// *************************************************************************** *
// *                                                                           *
// *                      Mentor Graphics Corporation                          *
// *                          All rights reserved                              *
// *                                                                           *
// *************************************************************************** *
// *                                                                           *
// * Description:         CANDB File                                           *
// * Generated at:        2022-07-01 13:40                                     *
// * System:              ZSDB122200                                           *
// * Variant:             DC1E_EU                                              *
// * Network:             BodyExposedCAN                                       *
// *                                                                           *
// *************************************************************************** *
// *                                                                           *
// *             THIS CONFIGURATION MIGHT CONTAIN SOME ERRORS                  *
// *              IF THE INPUT MODEL WAS NOT PROPERLY FORMED!                  *
// *                    Do Not Use this File directly!                         *
// *                                                                           *
// *************************************************************************** *
VERSION "BodyExposedCAN"

NS_ :

BS_ :

BU_ :  CEM ETC HCML HCMR RCML RCMM RCMR

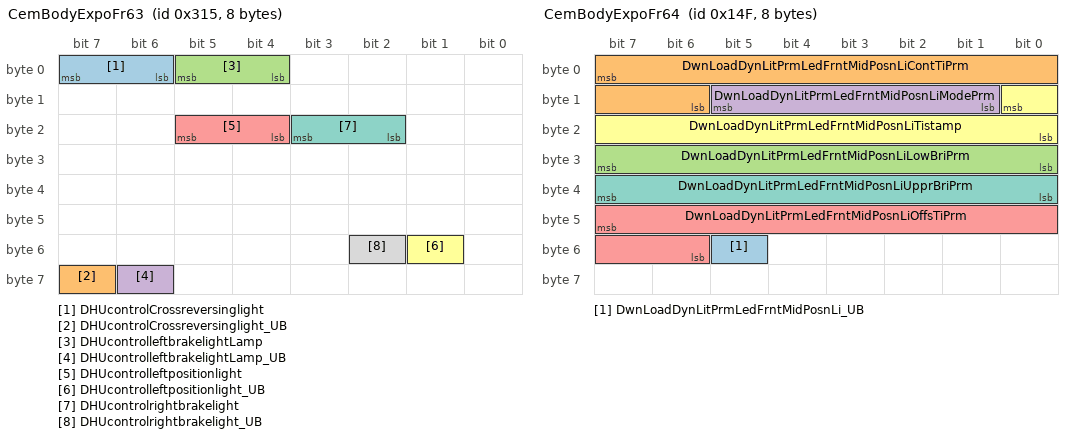
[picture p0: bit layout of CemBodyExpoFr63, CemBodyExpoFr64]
BO_ 789 CemBodyExpoFr63 : 8 CEM
 SG_ DHUcontrolCrossreversinglight : 7|2@0+ (1,0) [0|3] "" RCMM
 SG_ DHUcontrolCrossreversinglight_UB : 63|1@0+ (1,0) [0|1] "" RCMM
 SG_ DHUcontrolleftbrakelightLamp : 5|2@0+ (1,0) [0|3] "" RCML
 SG_ DHUcontrolleftbrakelightLamp_UB : 62|1@0+ (1,0) [0|1] "" RCML
 SG_ DHUcontrolleftpositionlight : 21|2@0+ (1,0) [0|3] "" RCML
 SG_ DHUcontrolleftpositionlight_UB : 49|1@0+ (1,0) [0|1] "" RCML
 SG_ DHUcontrolrightbrakelight : 19|2@0+ (1,0) [0|3] "" RCMR
 SG_ DHUcontrolrightbrakelight_UB : 50|1@0+ (1,0) [0|1] "" RCMR

BO_ 335 CemBodyExpoFr64 : 8 CEM
 SG_ DwnLoadDynLitPrmLedFrntMidPosnLi_UB : 53|1@0+ (1,0) [0|1] "" Vector_XXX
 SG_ DwnLoadDynLitPrmLedFrntMidPosnLiContTiPrm : 7|10@0+ (1.0,0.0) [0.0|1000.0] "Milliseconds" Vector_XXX
 SG_ DwnLoadDynLitPrmLedFrntMidPosnLiLowBriPrm : 31|8@0+ (1.0,0.0) [0.0|100.0] "%" Vector_XXX
 SG_ DwnLoadDynLitPrmLedFrntMidPosnLiModePrm : 13|5@0+ (1,0) [0|31] "" Vector_XXX
 SG_ DwnLoadDynLitPrmLedFrntMidPosnLiOffsTiPrm : 47|10@0+ (1.0,0.0) [0.0|1000.0] "Milliseconds" Vector_XXX
 SG_ DwnLoadDynLitPrmLedFrntMidPosnLiTistamp : 8|9@0+ (1.0,0.0) [0.0|511.0] "Unitless" Vector_XXX
 SG_ DwnLoadDynLitPrmLedFrntMidPosnLiUpprBriPrm : 39|8@0+ (1.0,0.0) [0.0|100.0] "%" Vector_XXX

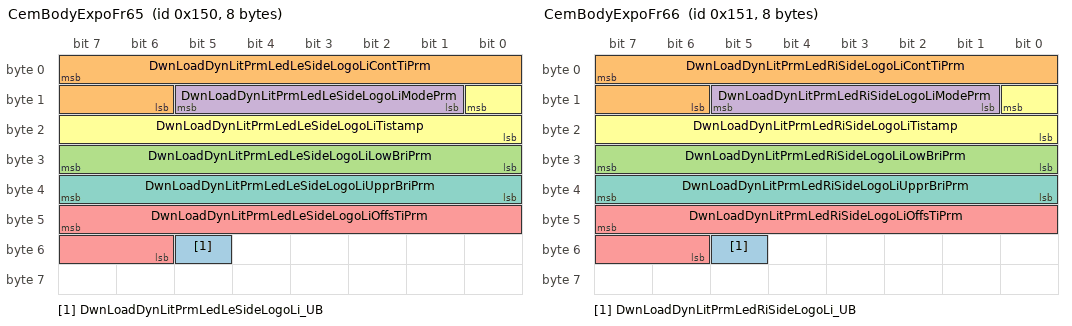
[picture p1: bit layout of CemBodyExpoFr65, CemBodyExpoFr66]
BO_ 336 CemBodyExpoFr65 : 8 CEM
 SG_ DwnLoadDynLitPrmLedLeSideLogoLi_UB : 53|1@0+ (1,0) [0|1] "" HCML
 SG_ DwnLoadDynLitPrmLedLeSideLogoLiContTiPrm : 7|10@0+ (1.0,0.0) [0.0|1000.0] "Milliseconds" HCML
 SG_ DwnLoadDynLitPrmLedLeSideLogoLiLowBriPrm : 31|8@0+ (1.0,0.0) [0.0|100.0] "%" HCML
 SG_ DwnLoadDynLitPrmLedLeSideLogoLiModePrm : 13|5@0+ (1,0) [0|31] "" HCML
 SG_ DwnLoadDynLitPrmLedLeSideLogoLiOffsTiPrm : 47|10@0+ (1.0,0.0) [0.0|1000.0] "Milliseconds" HCML
 SG_ DwnLoadDynLitPrmLedLeSideLogoLiTistamp : 8|9@0+ (1.0,0.0) [0.0|511.0] "Unitless" HCML
 SG_ DwnLoadDynLitPrmLedLeSideLogoLiUpprBriPrm : 39|8@0+ (1.0,0.0) [0.0|100.0] "%" HCML

BO_ 337 CemBodyExpoFr66 : 8 CEM
 SG_ DwnLoadDynLitPrmLedRiSideLogoLi_UB : 53|1@0+ (1,0) [0|1] "" HCMR
 SG_ DwnLoadDynLitPrmLedRiSideLogoLiContTiPrm : 7|10@0+ (1.0,0.0) [0.0|1000.0] "Milliseconds" HCMR
 SG_ DwnLoadDynLitPrmLedRiSideLogoLiLowBriPrm : 31|8@0+ (1.0,0.0) [0.0|100.0] "%" HCMR
 SG_ DwnLoadDynLitPrmLedRiSideLogoLiModePrm : 13|5@0+ (1,0) [0|31] "" HCMR
 SG_ DwnLoadDynLitPrmLedRiSideLogoLiOffsTiPrm : 47|10@0+ (1.0,0.0) [0.0|1000.0] "Milliseconds" HCMR
 SG_ DwnLoadDynLitPrmLedRiSideLogoLiTistamp : 8|9@0+ (1.0,0.0) [0.0|511.0] "Unitless" HCMR
 SG_ DwnLoadDynLitPrmLedRiSideLogoLiUpprBriPrm : 39|8@0+ (1.0,0.0) [0.0|100.0] "%" HCMR

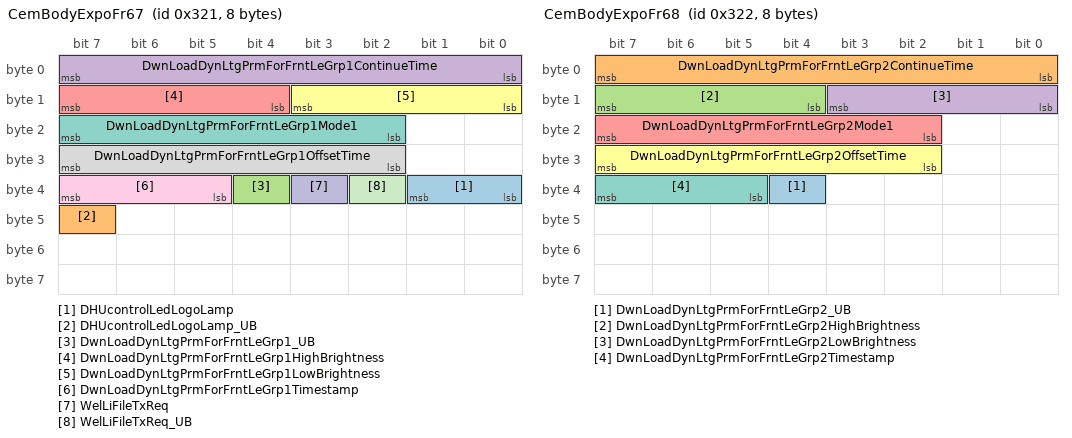
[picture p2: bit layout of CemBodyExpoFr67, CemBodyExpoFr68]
BO_ 801 CemBodyExpoFr67 : 8 CEM
 SG_ DHUcontrolLedLogoLamp : 33|2@0+ (1,0) [0|3] "" RCMM
 SG_ DHUcontrolLedLogoLamp_UB : 47|1@0+ (1,0) [0|1] "" RCMM
 SG_ DwnLoadDynLtgPrmForFrntLeGrp1_UB : 36|1@0+ (1,0) [0|1] "" HCML
 SG_ DwnLoadDynLtgPrmForFrntLeGrp1ContinueTime : 7|8@0+ (1.0,0.0) [0.0|255.0] "Unitless" HCML
 SG_ DwnLoadDynLtgPrmForFrntLeGrp1HighBrightness : 15|4@0+ (1.0,0.0) [0.0|10.0] "Unitless" HCML
 SG_ DwnLoadDynLtgPrmForFrntLeGrp1LowBrightness : 11|4@0+ (1.0,0.0) [0.0|10.0] "Unitless" HCML
 SG_ DwnLoadDynLtgPrmForFrntLeGrp1Mode1 : 23|6@0+ (1,0) [0|63] "" HCML
 SG_ DwnLoadDynLtgPrmForFrntLeGrp1OffsetTime : 31|6@0+ (1.0,0.0) [0.0|63.0] "Unitless" HCML
 SG_ DwnLoadDynLtgPrmForFrntLeGrp1Timestamp : 39|3@0+ (1.0,0.0) [0.0|7.0] "Unitless" HCML
 SG_ WelLiFileTxReq : 35|1@0+ (1,0) [0|1] "" HCML,HCMR
 SG_ WelLiFileTxReq_UB : 34|1@0+ (1,0) [0|1] "" HCML,HCMR

BO_ 802 CemBodyExpoFr68 : 8 CEM
 SG_ DwnLoadDynLtgPrmForFrntLeGrp2_UB : 36|1@0+ (1,0) [0|1] "" HCML
 SG_ DwnLoadDynLtgPrmForFrntLeGrp2ContinueTime : 7|8@0+ (1.0,0.0) [0.0|255.0] "Unitless" HCML
 SG_ DwnLoadDynLtgPrmForFrntLeGrp2HighBrightness : 15|4@0+ (1.0,0.0) [0.0|10.0] "Unitless" HCML
 SG_ DwnLoadDynLtgPrmForFrntLeGrp2LowBrightness : 11|4@0+ (1.0,0.0) [0.0|10.0] "Unitless" HCML
 SG_ DwnLoadDynLtgPrmForFrntLeGrp2Mode1 : 23|6@0+ (1,0) [0|63] "" HCML
 SG_ DwnLoadDynLtgPrmForFrntLeGrp2OffsetTime : 31|6@0+ (1.0,0.0) [0.0|63.0] "Unitless" HCML
 SG_ DwnLoadDynLtgPrmForFrntLeGrp2Timestamp : 39|3@0+ (1.0,0.0) [0.0|7.0] "Unitless" HCML

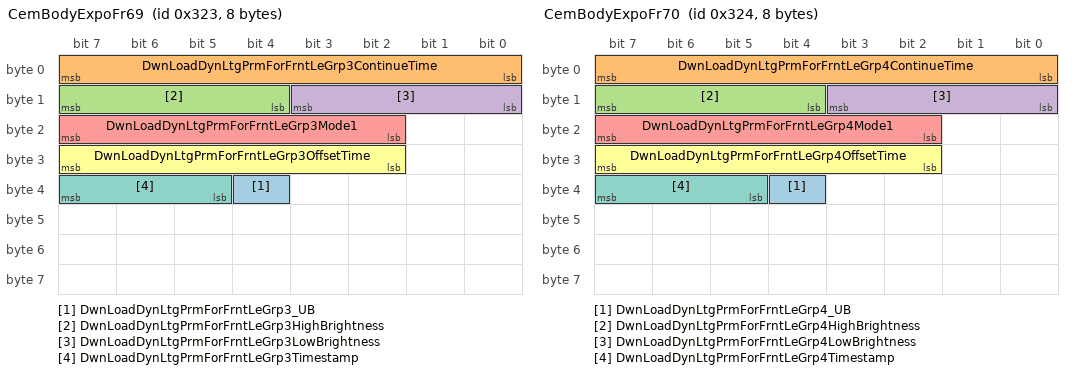
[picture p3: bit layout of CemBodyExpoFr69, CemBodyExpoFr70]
BO_ 803 CemBodyExpoFr69 : 8 CEM
 SG_ DwnLoadDynLtgPrmForFrntLeGrp3_UB : 36|1@0+ (1,0) [0|1] "" HCML
 SG_ DwnLoadDynLtgPrmForFrntLeGrp3ContinueTime : 7|8@0+ (1.0,0.0) [0.0|255.0] "Unitless" HCML
 SG_ DwnLoadDynLtgPrmForFrntLeGrp3HighBrightness : 15|4@0+ (1.0,0.0) [0.0|10.0] "Unitless" HCML
 SG_ DwnLoadDynLtgPrmForFrntLeGrp3LowBrightness : 11|4@0+ (1.0,0.0) [0.0|10.0] "Unitless" HCML
 SG_ DwnLoadDynLtgPrmForFrntLeGrp3Mode1 : 23|6@0+ (1,0) [0|63] "" HCML
 SG_ DwnLoadDynLtgPrmForFrntLeGrp3OffsetTime : 31|6@0+ (1.0,0.0) [0.0|63.0] "Unitless" HCML
 SG_ DwnLoadDynLtgPrmForFrntLeGrp3Timestamp : 39|3@0+ (1.0,0.0) [0.0|7.0] "Unitless" HCML

BO_ 804 CemBodyExpoFr70 : 8 CEM
 SG_ DwnLoadDynLtgPrmForFrntLeGrp4_UB : 36|1@0+ (1,0) [0|1] "" HCML
 SG_ DwnLoadDynLtgPrmForFrntLeGrp4ContinueTime : 7|8@0+ (1.0,0.0) [0.0|255.0] "Unitless" HCML
 SG_ DwnLoadDynLtgPrmForFrntLeGrp4HighBrightness : 15|4@0+ (1.0,0.0) [0.0|10.0] "Unitless" HCML
 SG_ DwnLoadDynLtgPrmForFrntLeGrp4LowBrightness : 11|4@0+ (1.0,0.0) [0.0|10.0] "Unitless" HCML
 SG_ DwnLoadDynLtgPrmForFrntLeGrp4Mode1 : 23|6@0+ (1,0) [0|63] "" HCML
 SG_ DwnLoadDynLtgPrmForFrntLeGrp4OffsetTime : 31|6@0+ (1.0,0.0) [0.0|63.0] "Unitless" HCML
 SG_ DwnLoadDynLtgPrmForFrntLeGrp4Timestamp : 39|3@0+ (1.0,0.0) [0.0|7.0] "Unitless" HCML

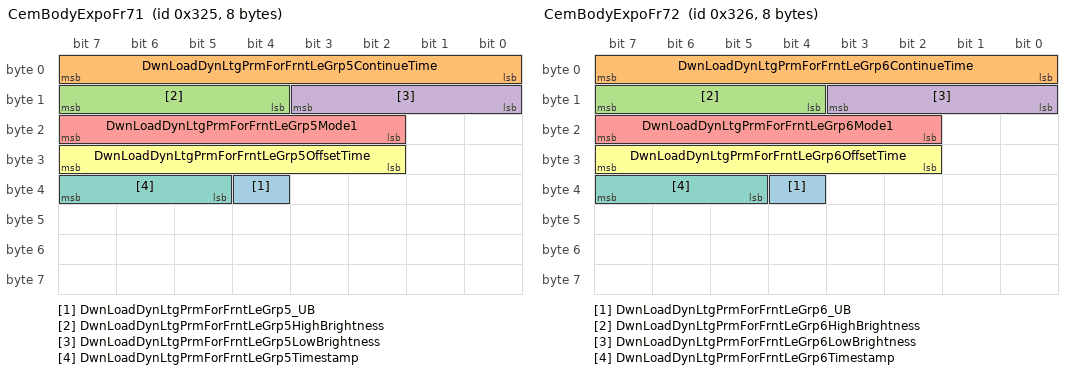
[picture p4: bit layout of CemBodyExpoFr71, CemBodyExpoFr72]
BO_ 805 CemBodyExpoFr71 : 8 CEM
 SG_ DwnLoadDynLtgPrmForFrntLeGrp5_UB : 36|1@0+ (1,0) [0|1] "" HCML
 SG_ DwnLoadDynLtgPrmForFrntLeGrp5ContinueTime : 7|8@0+ (1.0,0.0) [0.0|255.0] "Unitless" HCML
 SG_ DwnLoadDynLtgPrmForFrntLeGrp5HighBrightness : 15|4@0+ (1.0,0.0) [0.0|10.0] "Unitless" HCML
 SG_ DwnLoadDynLtgPrmForFrntLeGrp5LowBrightness : 11|4@0+ (1.0,0.0) [0.0|10.0] "Unitless" HCML
 SG_ DwnLoadDynLtgPrmForFrntLeGrp5Mode1 : 23|6@0+ (1,0) [0|63] "" HCML
 SG_ DwnLoadDynLtgPrmForFrntLeGrp5OffsetTime : 31|6@0+ (1.0,0.0) [0.0|63.0] "Unitless" HCML
 SG_ DwnLoadDynLtgPrmForFrntLeGrp5Timestamp : 39|3@0+ (1.0,0.0) [0.0|7.0] "Unitless" HCML

BO_ 806 CemBodyExpoFr72 : 8 CEM
 SG_ DwnLoadDynLtgPrmForFrntLeGrp6_UB : 36|1@0+ (1,0) [0|1] "" HCML
 SG_ DwnLoadDynLtgPrmForFrntLeGrp6ContinueTime : 7|8@0+ (1.0,0.0) [0.0|255.0] "Unitless" HCML
 SG_ DwnLoadDynLtgPrmForFrntLeGrp6HighBrightness : 15|4@0+ (1.0,0.0) [0.0|10.0] "Unitless" HCML
 SG_ DwnLoadDynLtgPrmForFrntLeGrp6LowBrightness : 11|4@0+ (1.0,0.0) [0.0|10.0] "Unitless" HCML
 SG_ DwnLoadDynLtgPrmForFrntLeGrp6Mode1 : 23|6@0+ (1,0) [0|63] "" HCML
 SG_ DwnLoadDynLtgPrmForFrntLeGrp6OffsetTime : 31|6@0+ (1.0,0.0) [0.0|63.0] "Unitless" HCML
 SG_ DwnLoadDynLtgPrmForFrntLeGrp6Timestamp : 39|3@0+ (1.0,0.0) [0.0|7.0] "Unitless" HCML

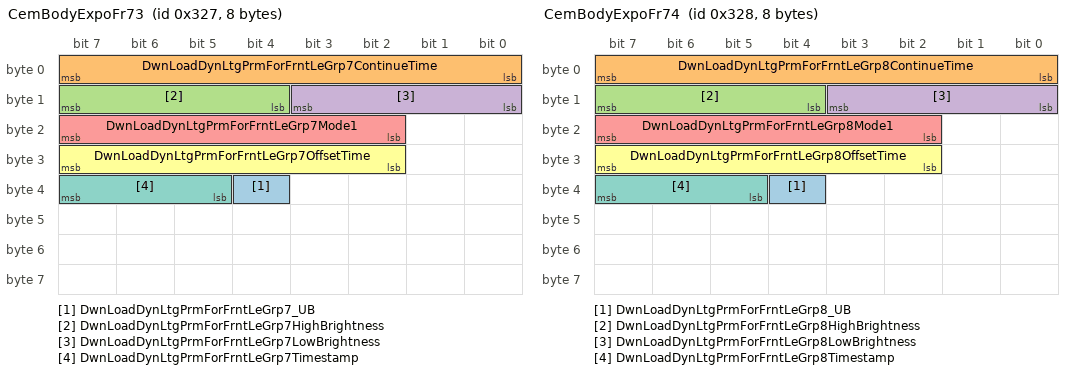
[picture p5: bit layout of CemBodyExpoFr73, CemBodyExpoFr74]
BO_ 807 CemBodyExpoFr73 : 8 CEM
 SG_ DwnLoadDynLtgPrmForFrntLeGrp7_UB : 36|1@0+ (1,0) [0|1] "" HCML
 SG_ DwnLoadDynLtgPrmForFrntLeGrp7ContinueTime : 7|8@0+ (1.0,0.0) [0.0|255.0] "Unitless" HCML
 SG_ DwnLoadDynLtgPrmForFrntLeGrp7HighBrightness : 15|4@0+ (1.0,0.0) [0.0|10.0] "Unitless" HCML
 SG_ DwnLoadDynLtgPrmForFrntLeGrp7LowBrightness : 11|4@0+ (1.0,0.0) [0.0|10.0] "Unitless" HCML
 SG_ DwnLoadDynLtgPrmForFrntLeGrp7Mode1 : 23|6@0+ (1,0) [0|63] "" HCML
 SG_ DwnLoadDynLtgPrmForFrntLeGrp7OffsetTime : 31|6@0+ (1.0,0.0) [0.0|63.0] "Unitless" HCML
 SG_ DwnLoadDynLtgPrmForFrntLeGrp7Timestamp : 39|3@0+ (1.0,0.0) [0.0|7.0] "Unitless" HCML

BO_ 808 CemBodyExpoFr74 : 8 CEM
 SG_ DwnLoadDynLtgPrmForFrntLeGrp8_UB : 36|1@0+ (1,0) [0|1] "" HCML
 SG_ DwnLoadDynLtgPrmForFrntLeGrp8ContinueTime : 7|8@0+ (1.0,0.0) [0.0|255.0] "Unitless" HCML
 SG_ DwnLoadDynLtgPrmForFrntLeGrp8HighBrightness : 15|4@0+ (1.0,0.0) [0.0|10.0] "Unitless" HCML
 SG_ DwnLoadDynLtgPrmForFrntLeGrp8LowBrightness : 11|4@0+ (1.0,0.0) [0.0|10.0] "Unitless" HCML
 SG_ DwnLoadDynLtgPrmForFrntLeGrp8Mode1 : 23|6@0+ (1,0) [0|63] "" HCML
 SG_ DwnLoadDynLtgPrmForFrntLeGrp8OffsetTime : 31|6@0+ (1.0,0.0) [0.0|63.0] "Unitless" HCML
 SG_ DwnLoadDynLtgPrmForFrntLeGrp8Timestamp : 39|3@0+ (1.0,0.0) [0.0|7.0] "Unitless" HCML

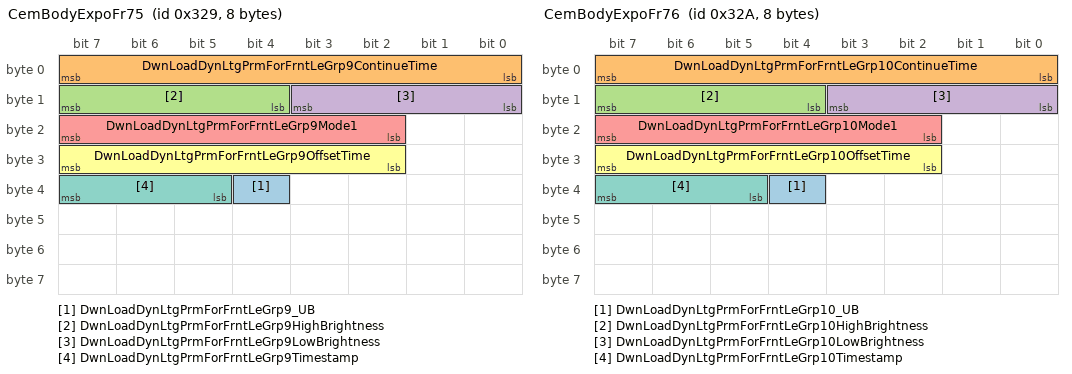
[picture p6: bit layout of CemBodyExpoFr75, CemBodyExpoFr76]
BO_ 809 CemBodyExpoFr75 : 8 CEM
 SG_ DwnLoadDynLtgPrmForFrntLeGrp9_UB : 36|1@0+ (1,0) [0|1] "" HCML
 SG_ DwnLoadDynLtgPrmForFrntLeGrp9ContinueTime : 7|8@0+ (1.0,0.0) [0.0|255.0] "Unitless" HCML
 SG_ DwnLoadDynLtgPrmForFrntLeGrp9HighBrightness : 15|4@0+ (1.0,0.0) [0.0|10.0] "Unitless" HCML
 SG_ DwnLoadDynLtgPrmForFrntLeGrp9LowBrightness : 11|4@0+ (1.0,0.0) [0.0|10.0] "Unitless" HCML
 SG_ DwnLoadDynLtgPrmForFrntLeGrp9Mode1 : 23|6@0+ (1,0) [0|63] "" HCML
 SG_ DwnLoadDynLtgPrmForFrntLeGrp9OffsetTime : 31|6@0+ (1.0,0.0) [0.0|63.0] "Unitless" HCML
 SG_ DwnLoadDynLtgPrmForFrntLeGrp9Timestamp : 39|3@0+ (1.0,0.0) [0.0|7.0] "Unitless" HCML

BO_ 810 CemBodyExpoFr76 : 8 CEM
 SG_ DwnLoadDynLtgPrmForFrntLeGrp10_UB : 36|1@0+ (1,0) [0|1] "" HCML
 SG_ DwnLoadDynLtgPrmForFrntLeGrp10ContinueTime : 7|8@0+ (1.0,0.0) [0.0|255.0] "Unitless" HCML
 SG_ DwnLoadDynLtgPrmForFrntLeGrp10HighBrightness : 15|4@0+ (1.0,0.0) [0.0|10.0] "Unitless" HCML
 SG_ DwnLoadDynLtgPrmForFrntLeGrp10LowBrightness : 11|4@0+ (1.0,0.0) [0.0|10.0] "Unitless" HCML
 SG_ DwnLoadDynLtgPrmForFrntLeGrp10Mode1 : 23|6@0+ (1,0) [0|63] "" HCML
 SG_ DwnLoadDynLtgPrmForFrntLeGrp10OffsetTime : 31|6@0+ (1.0,0.0) [0.0|63.0] "Unitless" HCML
 SG_ DwnLoadDynLtgPrmForFrntLeGrp10Timestamp : 39|3@0+ (1.0,0.0) [0.0|7.0] "Unitless" HCML

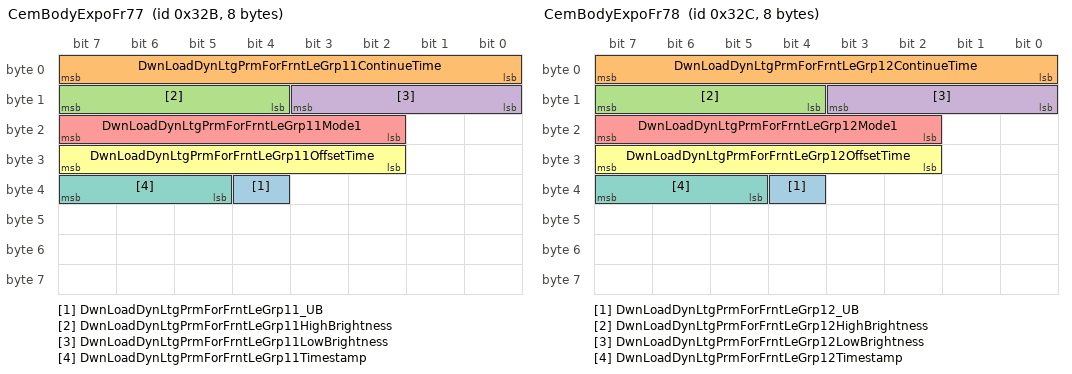
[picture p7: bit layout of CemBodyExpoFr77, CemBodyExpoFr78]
BO_ 811 CemBodyExpoFr77 : 8 CEM
 SG_ DwnLoadDynLtgPrmForFrntLeGrp11_UB : 36|1@0+ (1,0) [0|1] "" HCML
 SG_ DwnLoadDynLtgPrmForFrntLeGrp11ContinueTime : 7|8@0+ (1.0,0.0) [0.0|255.0] "Unitless" HCML
 SG_ DwnLoadDynLtgPrmForFrntLeGrp11HighBrightness : 15|4@0+ (1.0,0.0) [0.0|10.0] "Unitless" HCML
 SG_ DwnLoadDynLtgPrmForFrntLeGrp11LowBrightness : 11|4@0+ (1.0,0.0) [0.0|10.0] "Unitless" HCML
 SG_ DwnLoadDynLtgPrmForFrntLeGrp11Mode1 : 23|6@0+ (1,0) [0|63] "" HCML
 SG_ DwnLoadDynLtgPrmForFrntLeGrp11OffsetTime : 31|6@0+ (1.0,0.0) [0.0|63.0] "Unitless" HCML
 SG_ DwnLoadDynLtgPrmForFrntLeGrp11Timestamp : 39|3@0+ (1.0,0.0) [0.0|7.0] "Unitless" HCML

BO_ 812 CemBodyExpoFr78 : 8 CEM
 SG_ DwnLoadDynLtgPrmForFrntLeGrp12_UB : 36|1@0+ (1,0) [0|1] "" HCML
 SG_ DwnLoadDynLtgPrmForFrntLeGrp12ContinueTime : 7|8@0+ (1.0,0.0) [0.0|255.0] "Unitless" HCML
 SG_ DwnLoadDynLtgPrmForFrntLeGrp12HighBrightness : 15|4@0+ (1.0,0.0) [0.0|10.0] "Unitless" HCML
 SG_ DwnLoadDynLtgPrmForFrntLeGrp12LowBrightness : 11|4@0+ (1.0,0.0) [0.0|10.0] "Unitless" HCML
 SG_ DwnLoadDynLtgPrmForFrntLeGrp12Mode1 : 23|6@0+ (1,0) [0|63] "" HCML
 SG_ DwnLoadDynLtgPrmForFrntLeGrp12OffsetTime : 31|6@0+ (1.0,0.0) [0.0|63.0] "Unitless" HCML
 SG_ DwnLoadDynLtgPrmForFrntLeGrp12Timestamp : 39|3@0+ (1.0,0.0) [0.0|7.0] "Unitless" HCML

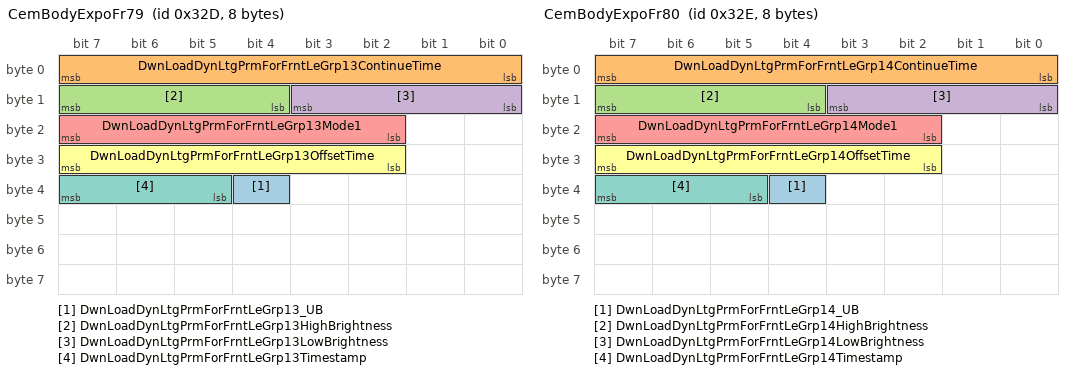
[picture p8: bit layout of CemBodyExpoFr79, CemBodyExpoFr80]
BO_ 813 CemBodyExpoFr79 : 8 CEM
 SG_ DwnLoadDynLtgPrmForFrntLeGrp13_UB : 36|1@0+ (1,0) [0|1] "" HCML
 SG_ DwnLoadDynLtgPrmForFrntLeGrp13ContinueTime : 7|8@0+ (1.0,0.0) [0.0|255.0] "Unitless" HCML
 SG_ DwnLoadDynLtgPrmForFrntLeGrp13HighBrightness : 15|4@0+ (1.0,0.0) [0.0|10.0] "Unitless" HCML
 SG_ DwnLoadDynLtgPrmForFrntLeGrp13LowBrightness : 11|4@0+ (1.0,0.0) [0.0|10.0] "Unitless" HCML
 SG_ DwnLoadDynLtgPrmForFrntLeGrp13Mode1 : 23|6@0+ (1,0) [0|63] "" HCML
 SG_ DwnLoadDynLtgPrmForFrntLeGrp13OffsetTime : 31|6@0+ (1.0,0.0) [0.0|63.0] "Unitless" HCML
 SG_ DwnLoadDynLtgPrmForFrntLeGrp13Timestamp : 39|3@0+ (1.0,0.0) [0.0|7.0] "Unitless" HCML

BO_ 814 CemBodyExpoFr80 : 8 CEM
 SG_ DwnLoadDynLtgPrmForFrntLeGrp14_UB : 36|1@0+ (1,0) [0|1] "" HCML
 SG_ DwnLoadDynLtgPrmForFrntLeGrp14ContinueTime : 7|8@0+ (1.0,0.0) [0.0|255.0] "Unitless" HCML
 SG_ DwnLoadDynLtgPrmForFrntLeGrp14HighBrightness : 15|4@0+ (1.0,0.0) [0.0|10.0] "Unitless" HCML
 SG_ DwnLoadDynLtgPrmForFrntLeGrp14LowBrightness : 11|4@0+ (1.0,0.0) [0.0|10.0] "Unitless" HCML
 SG_ DwnLoadDynLtgPrmForFrntLeGrp14Mode1 : 23|6@0+ (1,0) [0|63] "" HCML
 SG_ DwnLoadDynLtgPrmForFrntLeGrp14OffsetTime : 31|6@0+ (1.0,0.0) [0.0|63.0] "Unitless" HCML
 SG_ DwnLoadDynLtgPrmForFrntLeGrp14Timestamp : 39|3@0+ (1.0,0.0) [0.0|7.0] "Unitless" HCML

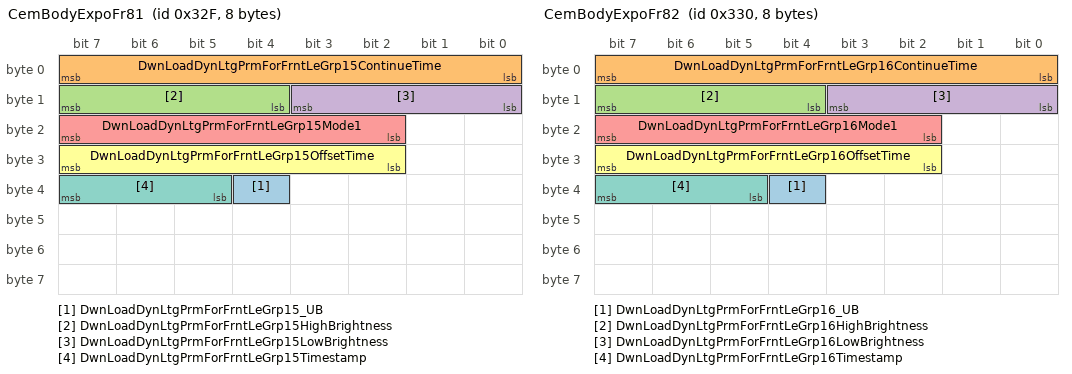
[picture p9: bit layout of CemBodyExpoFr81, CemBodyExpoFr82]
BO_ 815 CemBodyExpoFr81 : 8 CEM
 SG_ DwnLoadDynLtgPrmForFrntLeGrp15_UB : 36|1@0+ (1,0) [0|1] "" HCML
 SG_ DwnLoadDynLtgPrmForFrntLeGrp15ContinueTime : 7|8@0+ (1.0,0.0) [0.0|255.0] "Unitless" HCML
 SG_ DwnLoadDynLtgPrmForFrntLeGrp15HighBrightness : 15|4@0+ (1.0,0.0) [0.0|10.0] "Unitless" HCML
 SG_ DwnLoadDynLtgPrmForFrntLeGrp15LowBrightness : 11|4@0+ (1.0,0.0) [0.0|10.0] "Unitless" HCML
 SG_ DwnLoadDynLtgPrmForFrntLeGrp15Mode1 : 23|6@0+ (1,0) [0|63] "" HCML
 SG_ DwnLoadDynLtgPrmForFrntLeGrp15OffsetTime : 31|6@0+ (1.0,0.0) [0.0|63.0] "Unitless" HCML
 SG_ DwnLoadDynLtgPrmForFrntLeGrp15Timestamp : 39|3@0+ (1.0,0.0) [0.0|7.0] "Unitless" HCML

BO_ 816 CemBodyExpoFr82 : 8 CEM
 SG_ DwnLoadDynLtgPrmForFrntLeGrp16_UB : 36|1@0+ (1,0) [0|1] "" HCML
 SG_ DwnLoadDynLtgPrmForFrntLeGrp16ContinueTime : 7|8@0+ (1.0,0.0) [0.0|255.0] "Unitless" HCML
 SG_ DwnLoadDynLtgPrmForFrntLeGrp16HighBrightness : 15|4@0+ (1.0,0.0) [0.0|10.0] "Unitless" HCML
 SG_ DwnLoadDynLtgPrmForFrntLeGrp16LowBrightness : 11|4@0+ (1.0,0.0) [0.0|10.0] "Unitless" HCML
 SG_ DwnLoadDynLtgPrmForFrntLeGrp16Mode1 : 23|6@0+ (1,0) [0|63] "" HCML
 SG_ DwnLoadDynLtgPrmForFrntLeGrp16OffsetTime : 31|6@0+ (1.0,0.0) [0.0|63.0] "Unitless" HCML
 SG_ DwnLoadDynLtgPrmForFrntLeGrp16Timestamp : 39|3@0+ (1.0,0.0) [0.0|7.0] "Unitless" HCML

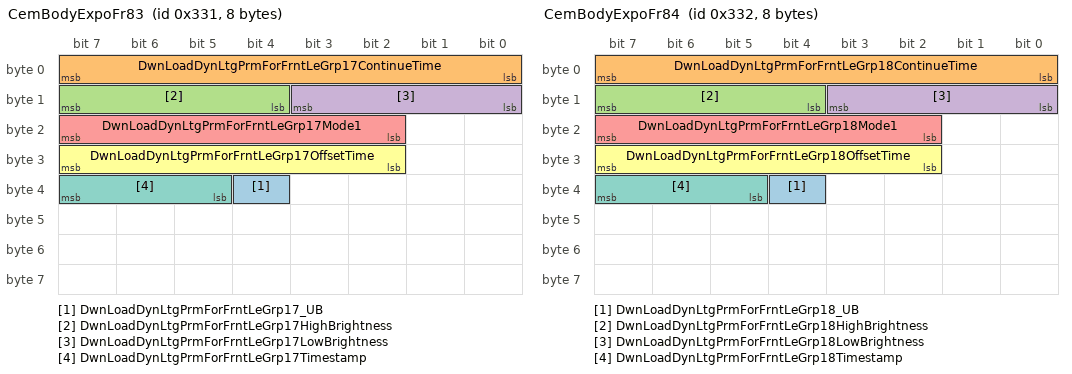
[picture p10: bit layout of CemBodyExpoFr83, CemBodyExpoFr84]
BO_ 817 CemBodyExpoFr83 : 8 CEM
 SG_ DwnLoadDynLtgPrmForFrntLeGrp17_UB : 36|1@0+ (1,0) [0|1] "" HCML
 SG_ DwnLoadDynLtgPrmForFrntLeGrp17ContinueTime : 7|8@0+ (1.0,0.0) [0.0|255.0] "Unitless" HCML
 SG_ DwnLoadDynLtgPrmForFrntLeGrp17HighBrightness : 15|4@0+ (1.0,0.0) [0.0|10.0] "Unitless" HCML
 SG_ DwnLoadDynLtgPrmForFrntLeGrp17LowBrightness : 11|4@0+ (1.0,0.0) [0.0|10.0] "Unitless" HCML
 SG_ DwnLoadDynLtgPrmForFrntLeGrp17Mode1 : 23|6@0+ (1,0) [0|63] "" HCML
 SG_ DwnLoadDynLtgPrmForFrntLeGrp17OffsetTime : 31|6@0+ (1.0,0.0) [0.0|63.0] "Unitless" HCML
 SG_ DwnLoadDynLtgPrmForFrntLeGrp17Timestamp : 39|3@0+ (1.0,0.0) [0.0|7.0] "Unitless" HCML

BO_ 818 CemBodyExpoFr84 : 8 CEM
 SG_ DwnLoadDynLtgPrmForFrntLeGrp18_UB : 36|1@0+ (1,0) [0|1] "" HCML
 SG_ DwnLoadDynLtgPrmForFrntLeGrp18ContinueTime : 7|8@0+ (1.0,0.0) [0.0|255.0] "Unitless" HCML
 SG_ DwnLoadDynLtgPrmForFrntLeGrp18HighBrightness : 15|4@0+ (1.0,0.0) [0.0|10.0] "Unitless" HCML
 SG_ DwnLoadDynLtgPrmForFrntLeGrp18LowBrightness : 11|4@0+ (1.0,0.0) [0.0|10.0] "Unitless" HCML
 SG_ DwnLoadDynLtgPrmForFrntLeGrp18Mode1 : 23|6@0+ (1,0) [0|63] "" HCML
 SG_ DwnLoadDynLtgPrmForFrntLeGrp18OffsetTime : 31|6@0+ (1.0,0.0) [0.0|63.0] "Unitless" HCML
 SG_ DwnLoadDynLtgPrmForFrntLeGrp18Timestamp : 39|3@0+ (1.0,0.0) [0.0|7.0] "Unitless" HCML

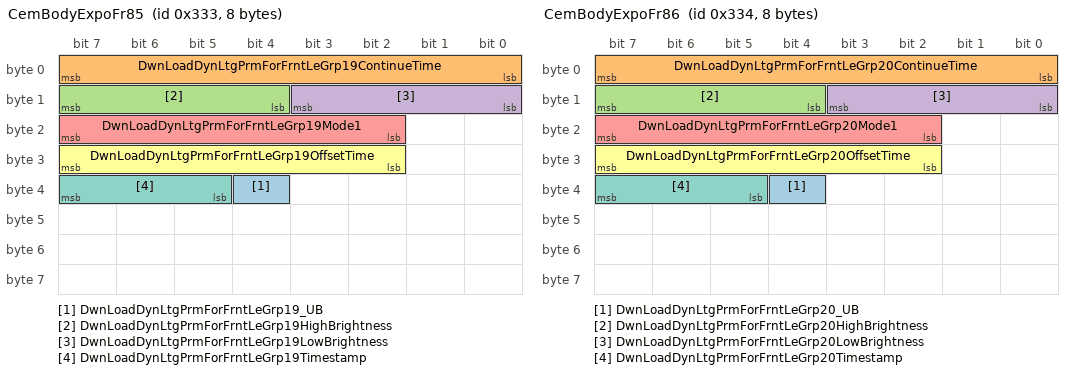
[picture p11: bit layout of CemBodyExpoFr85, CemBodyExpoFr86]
BO_ 819 CemBodyExpoFr85 : 8 CEM
 SG_ DwnLoadDynLtgPrmForFrntLeGrp19_UB : 36|1@0+ (1,0) [0|1] "" HCML
 SG_ DwnLoadDynLtgPrmForFrntLeGrp19ContinueTime : 7|8@0+ (1.0,0.0) [0.0|255.0] "Unitless" HCML
 SG_ DwnLoadDynLtgPrmForFrntLeGrp19HighBrightness : 15|4@0+ (1.0,0.0) [0.0|10.0] "Unitless" HCML
 SG_ DwnLoadDynLtgPrmForFrntLeGrp19LowBrightness : 11|4@0+ (1.0,0.0) [0.0|10.0] "Unitless" HCML
 SG_ DwnLoadDynLtgPrmForFrntLeGrp19Mode1 : 23|6@0+ (1,0) [0|63] "" HCML
 SG_ DwnLoadDynLtgPrmForFrntLeGrp19OffsetTime : 31|6@0+ (1.0,0.0) [0.0|63.0] "Unitless" HCML
 SG_ DwnLoadDynLtgPrmForFrntLeGrp19Timestamp : 39|3@0+ (1.0,0.0) [0.0|7.0] "Unitless" HCML

BO_ 820 CemBodyExpoFr86 : 8 CEM
 SG_ DwnLoadDynLtgPrmForFrntLeGrp20_UB : 36|1@0+ (1,0) [0|1] "" HCML
 SG_ DwnLoadDynLtgPrmForFrntLeGrp20ContinueTime : 7|8@0+ (1.0,0.0) [0.0|255.0] "Unitless" HCML
 SG_ DwnLoadDynLtgPrmForFrntLeGrp20HighBrightness : 15|4@0+ (1.0,0.0) [0.0|10.0] "Unitless" HCML
 SG_ DwnLoadDynLtgPrmForFrntLeGrp20LowBrightness : 11|4@0+ (1.0,0.0) [0.0|10.0] "Unitless" HCML
 SG_ DwnLoadDynLtgPrmForFrntLeGrp20Mode1 : 23|6@0+ (1,0) [0|63] "" HCML
 SG_ DwnLoadDynLtgPrmForFrntLeGrp20OffsetTime : 31|6@0+ (1.0,0.0) [0.0|63.0] "Unitless" HCML
 SG_ DwnLoadDynLtgPrmForFrntLeGrp20Timestamp : 39|3@0+ (1.0,0.0) [0.0|7.0] "Unitless" HCML

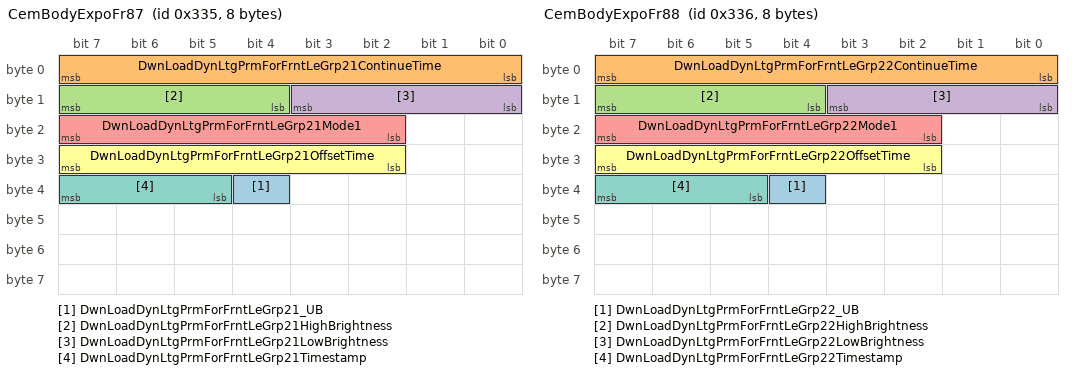
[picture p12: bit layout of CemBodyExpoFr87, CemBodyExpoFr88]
BO_ 821 CemBodyExpoFr87 : 8 CEM
 SG_ DwnLoadDynLtgPrmForFrntLeGrp21_UB : 36|1@0+ (1,0) [0|1] "" HCML
 SG_ DwnLoadDynLtgPrmForFrntLeGrp21ContinueTime : 7|8@0+ (1.0,0.0) [0.0|255.0] "Unitless" HCML
 SG_ DwnLoadDynLtgPrmForFrntLeGrp21HighBrightness : 15|4@0+ (1.0,0.0) [0.0|10.0] "Unitless" HCML
 SG_ DwnLoadDynLtgPrmForFrntLeGrp21LowBrightness : 11|4@0+ (1.0,0.0) [0.0|10.0] "Unitless" HCML
 SG_ DwnLoadDynLtgPrmForFrntLeGrp21Mode1 : 23|6@0+ (1,0) [0|63] "" HCML
 SG_ DwnLoadDynLtgPrmForFrntLeGrp21OffsetTime : 31|6@0+ (1.0,0.0) [0.0|63.0] "Unitless" HCML
 SG_ DwnLoadDynLtgPrmForFrntLeGrp21Timestamp : 39|3@0+ (1.0,0.0) [0.0|7.0] "Unitless" HCML

BO_ 822 CemBodyExpoFr88 : 8 CEM
 SG_ DwnLoadDynLtgPrmForFrntLeGrp22_UB : 36|1@0+ (1,0) [0|1] "" HCML
 SG_ DwnLoadDynLtgPrmForFrntLeGrp22ContinueTime : 7|8@0+ (1.0,0.0) [0.0|255.0] "Unitless" HCML
 SG_ DwnLoadDynLtgPrmForFrntLeGrp22HighBrightness : 15|4@0+ (1.0,0.0) [0.0|10.0] "Unitless" HCML
 SG_ DwnLoadDynLtgPrmForFrntLeGrp22LowBrightness : 11|4@0+ (1.0,0.0) [0.0|10.0] "Unitless" HCML
 SG_ DwnLoadDynLtgPrmForFrntLeGrp22Mode1 : 23|6@0+ (1,0) [0|63] "" HCML
 SG_ DwnLoadDynLtgPrmForFrntLeGrp22OffsetTime : 31|6@0+ (1.0,0.0) [0.0|63.0] "Unitless" HCML
 SG_ DwnLoadDynLtgPrmForFrntLeGrp22Timestamp : 39|3@0+ (1.0,0.0) [0.0|7.0] "Unitless" HCML

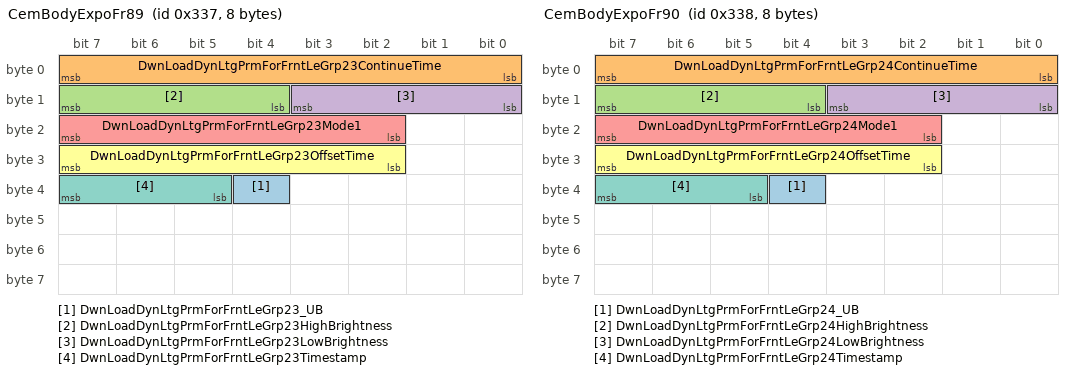
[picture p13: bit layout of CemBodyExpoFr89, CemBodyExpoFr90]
BO_ 823 CemBodyExpoFr89 : 8 CEM
 SG_ DwnLoadDynLtgPrmForFrntLeGrp23_UB : 36|1@0+ (1,0) [0|1] "" HCML
 SG_ DwnLoadDynLtgPrmForFrntLeGrp23ContinueTime : 7|8@0+ (1.0,0.0) [0.0|255.0] "Unitless" HCML
 SG_ DwnLoadDynLtgPrmForFrntLeGrp23HighBrightness : 15|4@0+ (1.0,0.0) [0.0|10.0] "Unitless" HCML
 SG_ DwnLoadDynLtgPrmForFrntLeGrp23LowBrightness : 11|4@0+ (1.0,0.0) [0.0|10.0] "Unitless" HCML
 SG_ DwnLoadDynLtgPrmForFrntLeGrp23Mode1 : 23|6@0+ (1,0) [0|63] "" HCML
 SG_ DwnLoadDynLtgPrmForFrntLeGrp23OffsetTime : 31|6@0+ (1.0,0.0) [0.0|63.0] "Unitless" HCML
 SG_ DwnLoadDynLtgPrmForFrntLeGrp23Timestamp : 39|3@0+ (1.0,0.0) [0.0|7.0] "Unitless" HCML

BO_ 824 CemBodyExpoFr90 : 8 CEM
 SG_ DwnLoadDynLtgPrmForFrntLeGrp24_UB : 36|1@0+ (1,0) [0|1] "" HCML
 SG_ DwnLoadDynLtgPrmForFrntLeGrp24ContinueTime : 7|8@0+ (1.0,0.0) [0.0|255.0] "Unitless" HCML
 SG_ DwnLoadDynLtgPrmForFrntLeGrp24HighBrightness : 15|4@0+ (1.0,0.0) [0.0|10.0] "Unitless" HCML
 SG_ DwnLoadDynLtgPrmForFrntLeGrp24LowBrightness : 11|4@0+ (1.0,0.0) [0.0|10.0] "Unitless" HCML
 SG_ DwnLoadDynLtgPrmForFrntLeGrp24Mode1 : 23|6@0+ (1,0) [0|63] "" HCML
 SG_ DwnLoadDynLtgPrmForFrntLeGrp24OffsetTime : 31|6@0+ (1.0,0.0) [0.0|63.0] "Unitless" HCML
 SG_ DwnLoadDynLtgPrmForFrntLeGrp24Timestamp : 39|3@0+ (1.0,0.0) [0.0|7.0] "Unitless" HCML

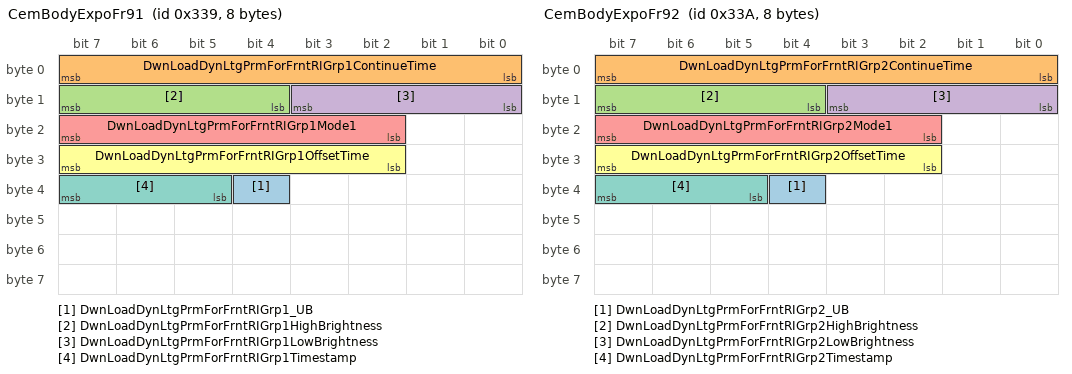
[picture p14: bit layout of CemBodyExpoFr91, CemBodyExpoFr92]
BO_ 825 CemBodyExpoFr91 : 8 CEM
 SG_ DwnLoadDynLtgPrmForFrntRIGrp1_UB : 36|1@0+ (1,0) [0|1] "" HCMR
 SG_ DwnLoadDynLtgPrmForFrntRIGrp1ContinueTime : 7|8@0+ (1.0,0.0) [0.0|255.0] "Unitless" HCMR
 SG_ DwnLoadDynLtgPrmForFrntRIGrp1HighBrightness : 15|4@0+ (1.0,0.0) [0.0|10.0] "Unitless" HCMR
 SG_ DwnLoadDynLtgPrmForFrntRIGrp1LowBrightness : 11|4@0+ (1.0,0.0) [0.0|10.0] "Unitless" HCMR
 SG_ DwnLoadDynLtgPrmForFrntRIGrp1Mode1 : 23|6@0+ (1,0) [0|63] "" HCMR
 SG_ DwnLoadDynLtgPrmForFrntRIGrp1OffsetTime : 31|6@0+ (1.0,0.0) [0.0|63.0] "Unitless" HCMR
 SG_ DwnLoadDynLtgPrmForFrntRIGrp1Timestamp : 39|3@0+ (1.0,0.0) [0.0|7.0] "Unitless" HCMR

BO_ 826 CemBodyExpoFr92 : 8 CEM
 SG_ DwnLoadDynLtgPrmForFrntRIGrp2_UB : 36|1@0+ (1,0) [0|1] "" HCMR
 SG_ DwnLoadDynLtgPrmForFrntRIGrp2ContinueTime : 7|8@0+ (1.0,0.0) [0.0|255.0] "Unitless" HCMR
 SG_ DwnLoadDynLtgPrmForFrntRIGrp2HighBrightness : 15|4@0+ (1.0,0.0) [0.0|10.0] "Unitless" HCMR
 SG_ DwnLoadDynLtgPrmForFrntRIGrp2LowBrightness : 11|4@0+ (1.0,0.0) [0.0|10.0] "Unitless" HCMR
 SG_ DwnLoadDynLtgPrmForFrntRIGrp2Mode1 : 23|6@0+ (1,0) [0|63] "" HCMR
 SG_ DwnLoadDynLtgPrmForFrntRIGrp2OffsetTime : 31|6@0+ (1.0,0.0) [0.0|63.0] "Unitless" HCMR
 SG_ DwnLoadDynLtgPrmForFrntRIGrp2Timestamp : 39|3@0+ (1.0,0.0) [0.0|7.0] "Unitless" HCMR

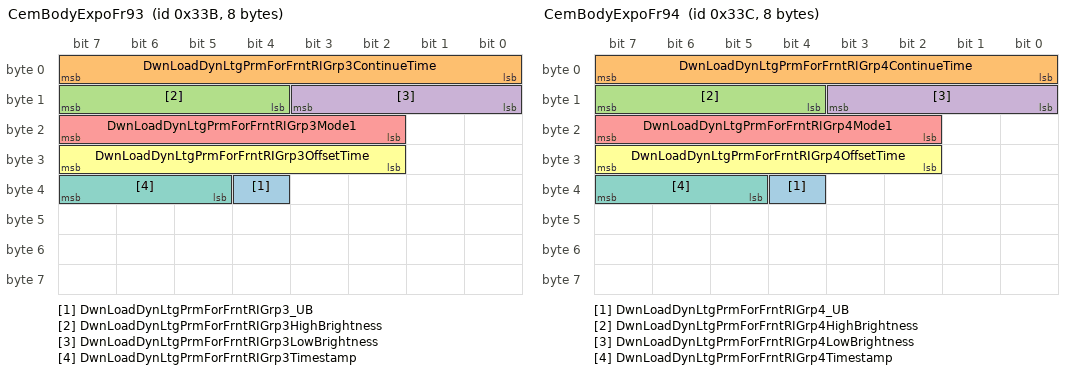
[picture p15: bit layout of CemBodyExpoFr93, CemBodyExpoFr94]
BO_ 827 CemBodyExpoFr93 : 8 CEM
 SG_ DwnLoadDynLtgPrmForFrntRIGrp3_UB : 36|1@0+ (1,0) [0|1] "" HCMR
 SG_ DwnLoadDynLtgPrmForFrntRIGrp3ContinueTime : 7|8@0+ (1.0,0.0) [0.0|255.0] "Unitless" HCMR
 SG_ DwnLoadDynLtgPrmForFrntRIGrp3HighBrightness : 15|4@0+ (1.0,0.0) [0.0|10.0] "Unitless" HCMR
 SG_ DwnLoadDynLtgPrmForFrntRIGrp3LowBrightness : 11|4@0+ (1.0,0.0) [0.0|10.0] "Unitless" HCMR
 SG_ DwnLoadDynLtgPrmForFrntRIGrp3Mode1 : 23|6@0+ (1,0) [0|63] "" HCMR
 SG_ DwnLoadDynLtgPrmForFrntRIGrp3OffsetTime : 31|6@0+ (1.0,0.0) [0.0|63.0] "Unitless" HCMR
 SG_ DwnLoadDynLtgPrmForFrntRIGrp3Timestamp : 39|3@0+ (1.0,0.0) [0.0|7.0] "Unitless" HCMR

BO_ 828 CemBodyExpoFr94 : 8 CEM
 SG_ DwnLoadDynLtgPrmForFrntRIGrp4_UB : 36|1@0+ (1,0) [0|1] "" HCMR
 SG_ DwnLoadDynLtgPrmForFrntRIGrp4ContinueTime : 7|8@0+ (1.0,0.0) [0.0|255.0] "Unitless" HCMR
 SG_ DwnLoadDynLtgPrmForFrntRIGrp4HighBrightness : 15|4@0+ (1.0,0.0) [0.0|10.0] "Unitless" HCMR
 SG_ DwnLoadDynLtgPrmForFrntRIGrp4LowBrightness : 11|4@0+ (1.0,0.0) [0.0|10.0] "Unitless" HCMR
 SG_ DwnLoadDynLtgPrmForFrntRIGrp4Mode1 : 23|6@0+ (1,0) [0|63] "" HCMR
 SG_ DwnLoadDynLtgPrmForFrntRIGrp4OffsetTime : 31|6@0+ (1.0,0.0) [0.0|63.0] "Unitless" HCMR
 SG_ DwnLoadDynLtgPrmForFrntRIGrp4Timestamp : 39|3@0+ (1.0,0.0) [0.0|7.0] "Unitless" HCMR

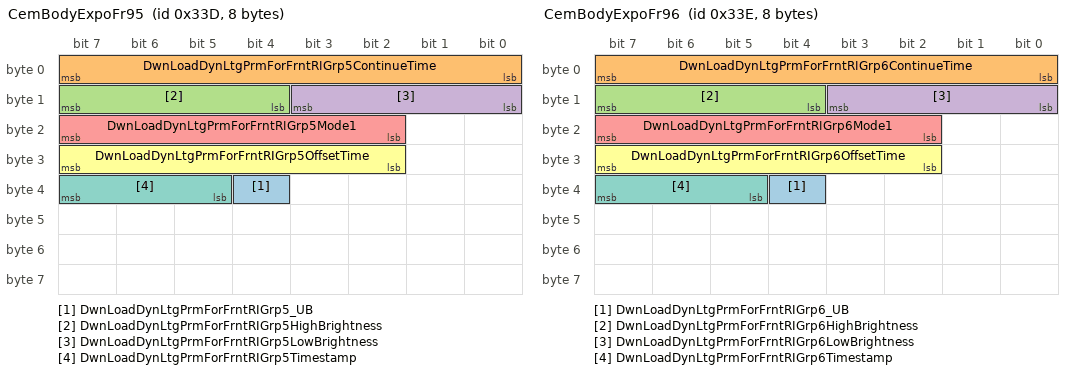
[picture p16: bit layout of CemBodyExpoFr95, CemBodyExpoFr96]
BO_ 829 CemBodyExpoFr95 : 8 CEM
 SG_ DwnLoadDynLtgPrmForFrntRIGrp5_UB : 36|1@0+ (1,0) [0|1] "" HCMR
 SG_ DwnLoadDynLtgPrmForFrntRIGrp5ContinueTime : 7|8@0+ (1.0,0.0) [0.0|255.0] "Unitless" HCMR
 SG_ DwnLoadDynLtgPrmForFrntRIGrp5HighBrightness : 15|4@0+ (1.0,0.0) [0.0|10.0] "Unitless" HCMR
 SG_ DwnLoadDynLtgPrmForFrntRIGrp5LowBrightness : 11|4@0+ (1.0,0.0) [0.0|10.0] "Unitless" HCMR
 SG_ DwnLoadDynLtgPrmForFrntRIGrp5Mode1 : 23|6@0+ (1,0) [0|63] "" HCMR
 SG_ DwnLoadDynLtgPrmForFrntRIGrp5OffsetTime : 31|6@0+ (1.0,0.0) [0.0|63.0] "Unitless" HCMR
 SG_ DwnLoadDynLtgPrmForFrntRIGrp5Timestamp : 39|3@0+ (1.0,0.0) [0.0|7.0] "Unitless" HCMR

BO_ 830 CemBodyExpoFr96 : 8 CEM
 SG_ DwnLoadDynLtgPrmForFrntRIGrp6_UB : 36|1@0+ (1,0) [0|1] "" HCMR
 SG_ DwnLoadDynLtgPrmForFrntRIGrp6ContinueTime : 7|8@0+ (1.0,0.0) [0.0|255.0] "Unitless" HCMR
 SG_ DwnLoadDynLtgPrmForFrntRIGrp6HighBrightness : 15|4@0+ (1.0,0.0) [0.0|10.0] "Unitless" HCMR
 SG_ DwnLoadDynLtgPrmForFrntRIGrp6LowBrightness : 11|4@0+ (1.0,0.0) [0.0|10.0] "Unitless" HCMR
 SG_ DwnLoadDynLtgPrmForFrntRIGrp6Mode1 : 23|6@0+ (1,0) [0|63] "" HCMR
 SG_ DwnLoadDynLtgPrmForFrntRIGrp6OffsetTime : 31|6@0+ (1.0,0.0) [0.0|63.0] "Unitless" HCMR
 SG_ DwnLoadDynLtgPrmForFrntRIGrp6Timestamp : 39|3@0+ (1.0,0.0) [0.0|7.0] "Unitless" HCMR

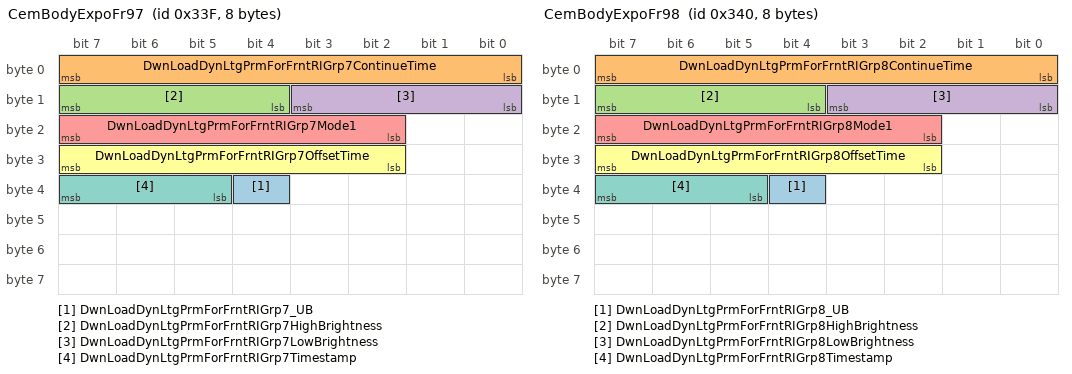
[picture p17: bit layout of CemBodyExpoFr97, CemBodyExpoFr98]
BO_ 831 CemBodyExpoFr97 : 8 CEM
 SG_ DwnLoadDynLtgPrmForFrntRIGrp7_UB : 36|1@0+ (1,0) [0|1] "" HCMR
 SG_ DwnLoadDynLtgPrmForFrntRIGrp7ContinueTime : 7|8@0+ (1.0,0.0) [0.0|255.0] "Unitless" HCMR
 SG_ DwnLoadDynLtgPrmForFrntRIGrp7HighBrightness : 15|4@0+ (1.0,0.0) [0.0|10.0] "Unitless" HCMR
 SG_ DwnLoadDynLtgPrmForFrntRIGrp7LowBrightness : 11|4@0+ (1.0,0.0) [0.0|10.0] "Unitless" HCMR
 SG_ DwnLoadDynLtgPrmForFrntRIGrp7Mode1 : 23|6@0+ (1,0) [0|63] "" HCMR
 SG_ DwnLoadDynLtgPrmForFrntRIGrp7OffsetTime : 31|6@0+ (1.0,0.0) [0.0|63.0] "Unitless" HCMR
 SG_ DwnLoadDynLtgPrmForFrntRIGrp7Timestamp : 39|3@0+ (1.0,0.0) [0.0|7.0] "Unitless" HCMR

BO_ 832 CemBodyExpoFr98 : 8 CEM
 SG_ DwnLoadDynLtgPrmForFrntRIGrp8_UB : 36|1@0+ (1,0) [0|1] "" HCMR
 SG_ DwnLoadDynLtgPrmForFrntRIGrp8ContinueTime : 7|8@0+ (1.0,0.0) [0.0|255.0] "Unitless" HCMR
 SG_ DwnLoadDynLtgPrmForFrntRIGrp8HighBrightness : 15|4@0+ (1.0,0.0) [0.0|10.0] "Unitless" HCMR
 SG_ DwnLoadDynLtgPrmForFrntRIGrp8LowBrightness : 11|4@0+ (1.0,0.0) [0.0|10.0] "Unitless" HCMR
 SG_ DwnLoadDynLtgPrmForFrntRIGrp8Mode1 : 23|6@0+ (1,0) [0|63] "" HCMR
 SG_ DwnLoadDynLtgPrmForFrntRIGrp8OffsetTime : 31|6@0+ (1.0,0.0) [0.0|63.0] "Unitless" HCMR
 SG_ DwnLoadDynLtgPrmForFrntRIGrp8Timestamp : 39|3@0+ (1.0,0.0) [0.0|7.0] "Unitless" HCMR

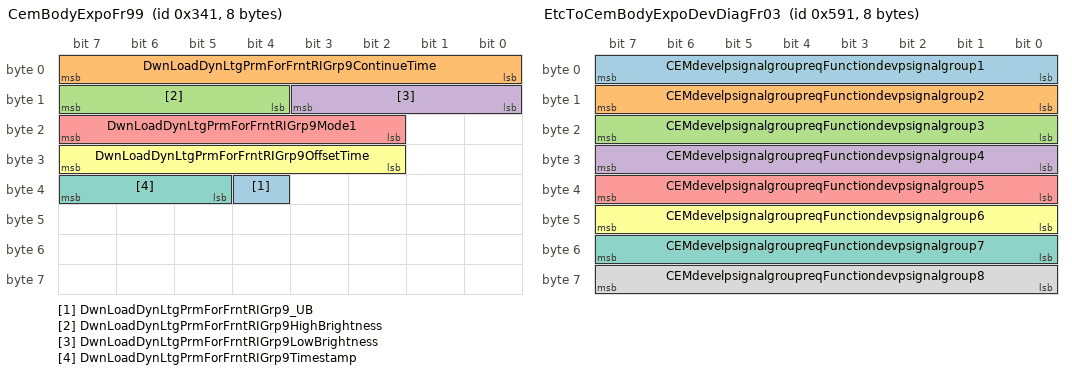
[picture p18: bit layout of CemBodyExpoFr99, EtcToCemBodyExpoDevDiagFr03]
BO_ 833 CemBodyExpoFr99 : 8 CEM
 SG_ DwnLoadDynLtgPrmForFrntRIGrp9_UB : 36|1@0+ (1,0) [0|1] "" HCMR
 SG_ DwnLoadDynLtgPrmForFrntRIGrp9ContinueTime : 7|8@0+ (1.0,0.0) [0.0|255.0] "Unitless" HCMR
 SG_ DwnLoadDynLtgPrmForFrntRIGrp9HighBrightness : 15|4@0+ (1.0,0.0) [0.0|10.0] "Unitless" HCMR
 SG_ DwnLoadDynLtgPrmForFrntRIGrp9LowBrightness : 11|4@0+ (1.0,0.0) [0.0|10.0] "Unitless" HCMR
 SG_ DwnLoadDynLtgPrmForFrntRIGrp9Mode1 : 23|6@0+ (1,0) [0|63] "" HCMR
 SG_ DwnLoadDynLtgPrmForFrntRIGrp9OffsetTime : 31|6@0+ (1.0,0.0) [0.0|63.0] "Unitless" HCMR
 SG_ DwnLoadDynLtgPrmForFrntRIGrp9Timestamp : 39|3@0+ (1.0,0.0) [0.0|7.0] "Unitless" HCMR

BO_ 2047 CemToAllFuncBodyCanExposedDiagReqFrame : 8 CEM
 SG_ CemToAllFuncBodyCanExpDiagReqNpdu : 7|64@0+ (1,0) [0|0] "" HCML, HCMR, RCML, RCMM, RCMR

BO_ 1969 CemToDpod2BodyCanExposedDiagReqFrame : 8 CEM
 SG_ CemToDpod2BodyCanExpDiagReqNpdu : 7|64@0+ (1,0) [0|0] "" Vector_XXX

BO_ 1978 CemToFccmBodyCanExposedDiagReqFrame : 8 CEM
 SG_ CemToFccmBodyCanExpDiagReqNpdu : 7|64@0+ (1,0) [0|0] "" Vector_XXX

BO_ 1977 CemToGcmBodyCanExposedDiagReqFrame : 8 CEM
 SG_ CemToGcmBodyCanExpDiagReqNpdu : 7|64@0+ (1,0) [0|0] "" Vector_XXX

BO_ 1981 CemToGpflBodyCanExposedDiagReqFrame : 8 CEM
 SG_ CemToGpflBodyCanExpDiagReqNpdu : 7|64@0+ (1,0) [0|0] "" Vector_XXX

BO_ 1982 CemToGpfrBodyCanExposedDiagReqFrame : 8 CEM
 SG_ CemToGpfrBodyCanExpDiagReqNpdu : 7|64@0+ (1,0) [0|0] "" Vector_XXX

BO_ 1984 CemToGprlBodyCanExposedDiagReqFrame : 8 CEM
 SG_ CemToGprlBodyCanExpDiagReqNpdu : 7|64@0+ (1,0) [0|0] "" Vector_XXX

BO_ 1985 CemToGprrBodyCanExposedDiagReqFrame : 8 CEM
 SG_ CemToGprrBodyCanExpDiagReqNpdu : 7|64@0+ (1,0) [0|0] "" Vector_XXX

BO_ 1971 CemToHcmlBodyCanExposedDiagReqFrame : 8 CEM
 SG_ CemToHcmlBodyCanExpDiagReqNpdu : 7|64@0+ (1,0) [0|0] "" HCML

BO_ 1972 CemToHcmrBodyCanExposedDiagReqFrame : 8 CEM
 SG_ CemToHcmrBodyCanExpDiagReqNpdu : 7|64@0+ (1,0) [0|0] "" HCMR

BO_ 1968 CemToLpod2BodyCanExposedDiagReqFrame : 8 CEM
 SG_ CemToLpod2BodyCanExpDiagReqNpdu : 7|64@0+ (1,0) [0|0] "" Vector_XXX

BO_ 1980 CemToPpod2BodyCanExposedDiagReqFrame : 8 CEM
 SG_ CemToPpod2BodyCanExpDiagReqNpdu : 7|64@0+ (1,0) [0|0] "" Vector_XXX

BO_ 1970 CemToRcmBodyCanExposedDiagReqFrame : 8 CEM
 SG_ CemToRcmBodyCanExpDiagReqNpdu : 7|64@0+ (1,0) [0|0] "" Vector_XXX

BO_ 1973 CemToRcmlBodyCanExposedDiagReqFrame : 8 CEM
 SG_ CemToRcmlBodyCanExpDiagReqNpdu : 7|64@0+ (1,0) [0|0] "" RCML

BO_ 1975 CemToRcmmBodyCanExposedDiagReqFrame : 8 CEM
 SG_ CemToRcmmBodyCanExpDiagReqNpdu : 7|64@0+ (1,0) [0|0] "" RCMM

BO_ 1974 CemToRcmrBodyCanExposedDiagReqFrame : 8 CEM
 SG_ CemToRcmrBodyCanExpDiagReqNpdu : 7|64@0+ (1,0) [0|0] "" RCMR

BO_ 1979 CemToRpod2BodyCanExposedDiagReqFrame : 8 CEM
 SG_ CemToRpod2BodyCanExpDiagReqNpdu : 7|64@0+ (1,0) [0|0] "" Vector_XXX

BO_ 1425 EtcToCemBodyExpoDevDiagFr03 : 8 ETC
 SG_ CEMdevelpsignalgroupreqFunctiondevpsignalgroup1 : 7|8@0+ (1.0,0.0) [0.0|255.0] "Unitless" CEM
 SG_ CEMdevelpsignalgroupreqFunctiondevpsignalgroup2 : 15|8@0+ (1.0,0.0) [0.0|255.0] "Unitless" CEM
 SG_ CEMdevelpsignalgroupreqFunctiondevpsignalgroup3 : 23|8@0+ (1.0,0.0) [0.0|255.0] "Unitless" CEM
 SG_ CEMdevelpsignalgroupreqFunctiondevpsignalgroup4 : 31|8@0+ (1.0,0.0) [0.0|255.0] "Unitless" CEM
 SG_ CEMdevelpsignalgroupreqFunctiondevpsignalgroup5 : 39|8@0+ (1.0,0.0) [0.0|255.0] "Unitless" CEM
 SG_ CEMdevelpsignalgroupreqFunctiondevpsignalgroup6 : 47|8@0+ (1.0,0.0) [0.0|255.0] "Unitless" CEM
 SG_ CEMdevelpsignalgroupreqFunctiondevpsignalgroup7 : 55|8@0+ (1.0,0.0) [0.0|255.0] "Unitless" CEM
 SG_ CEMdevelpsignalgroupreqFunctiondevpsignalgroup8 : 63|8@0+ (1.0,0.0) [0.0|255.0] "Unitless" CEM

BO_ 1430 EtctoHcmlXCPFr01 : 8 ETC

BO_ 1428 EtctoHcmrXCPFr01 : 8 ETC

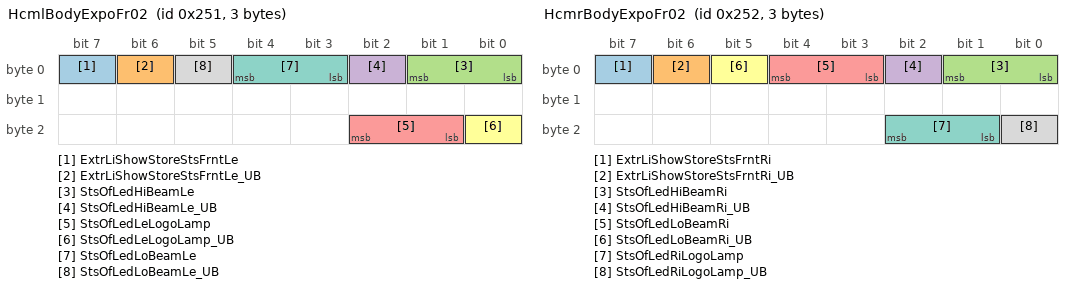
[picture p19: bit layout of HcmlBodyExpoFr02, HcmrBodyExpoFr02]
BO_ 593 HcmlBodyExpoFr02 : 3 HCML
 SG_ ExtrLiShowStoreStsFrntLe : 7|1@0+ (1,0) [0|1] "" CEM
 SG_ ExtrLiShowStoreStsFrntLe_UB : 6|1@0+ (1,0) [0|1] "" CEM
 SG_ StsOfLedHiBeamLe : 1|2@0+ (1,0) [0|3] "" CEM
 SG_ StsOfLedHiBeamLe_UB : 2|1@0+ (1,0) [0|1] "" CEM
 SG_ StsOfLedLeLogoLamp : 18|2@0+ (1,0) [0|3] "" CEM
 SG_ StsOfLedLeLogoLamp_UB : 16|1@0+ (1,0) [0|1] "" CEM
 SG_ StsOfLedLoBeamLe : 4|2@0+ (1,0) [0|3] "" CEM
 SG_ StsOfLedLoBeamLe_UB : 5|1@0+ (1,0) [0|1] "" CEM

BO_ 124 HcmlBodyExpoFr04 : 8 HCML
 SG_ DwnLoadStsFbOfHdlampLe : 5|2@0+ (1,0) [0|3] "" CEM
 SG_ DwnLoadStsFbOfHdlampLe_UB : 39|1@0+ (1,0) [0|1] "" CEM
 SG_ DwnLoadStsFbOfLogoLampLe : 57|2@0+ (1,0) [0|3] "" CEM
 SG_ DwnLoadStsFbOfLogoLampLe_UB : 21|1@0+ (1,0) [0|1] "" CEM
 SG_ ExtrLiShowActvnFrntLeFb : 28|2@0+ (1,0) [0|3] "" CEM
 SG_ ExtrLiShowActvnFrntLeFb_UB : 20|1@0+ (1,0) [0|1] "" CEM
 SG_ ExtrLiShowActvnLeLogoFb : 59|2@0+ (1,0) [0|3] "" CEM
 SG_ ExtrLiShowActvnLeLogoFb_UB : 22|1@0+ (1,0) [0|1] "" CEM
 SG_ HdlampLeInpSts1 : 49|1@0+ (1,0) [0|1] "" CEM
 SG_ HdlampLeInpSts1_UB : 48|1@0+ (1,0) [0|1] "" CEM
 SG_ HdlampLeInpSts2 : 63|1@0+ (1,0) [0|1] "" CEM
 SG_ HdlampLeInpSts2_UB : 62|1@0+ (1,0) [0|1] "" CEM
 SG_ StsOfAfsLe : 1|2@0+ (1,0) [0|3] "" CEM
 SG_ StsOfAfsLe_UB : 38|1@0+ (1,0) [0|1] "" CEM
 SG_ StsOfAhbcLe : 3|2@0+ (1,0) [0|3] "" CEM
 SG_ StsOfAhbcLe_UB : 37|1@0+ (1,0) [0|1] "" CEM
 SG_ StsOfFrntSideMkrLampLe2 : 9|2@0+ (1,0) [0|3] "" CEM
 SG_ StsOfFrntSideMkrLampLe2_UB : 34|1@0+ (1,0) [0|1] "" CEM
 SG_ StsOfLedCornrgLampLe : 11|2@0+ (1,0) [0|3] "" CEM
 SG_ StsOfLedCornrgLampLe_UB : 33|1@0+ (1,0) [0|1] "" CEM
 SG_ StsOfLedDaytiRunngLampLe : 13|2@0+ (1,0) [0|3] "" CEM
 SG_ StsOfLedDaytiRunngLampLe_UB : 32|1@0+ (1,0) [0|1] "" CEM
 SG_ StsOfLedFrntFogLampLe : 15|2@0+ (1,0) [0|3] "" CEM
 SG_ StsOfLedFrntFogLampLe_UB : 31|1@0+ (1,0) [0|1] "" CEM
 SG_ StsOfLedFrntPosnLampLe : 17|2@0+ (1,0) [0|3] "" CEM
 SG_ StsOfLedFrntPosnLampLe_UB : 30|1@0+ (1,0) [0|1] "" CEM
 SG_ StsOfLedFrntTurnIndcrLe : 19|2@0+ (1,0) [0|3] "" CEM
 SG_ StsOfLedFrntTurnIndcrLe_UB : 29|1@0+ (1,0) [0|1] "" CEM
 SG_ StsOfLvlgLe_UB : 36|1@0+ (1,0) [0|1] "" CEM
 SG_ StsOfLvlgLeChks : 47|8@0+ (1.0,0.0) [0.0|255.0] "Unitless" CEM
 SG_ StsOfLvlgLeCntr : 55|4@0+ (1.0,0.0) [0.0|15.0] "Unitless" CEM
 SG_ StsOfLvlgLeStsOfLvlgLe : 51|2@0+ (1,0) [0|3] "" CEM
 SG_ StsOfSwvlgLe : 7|2@0+ (1,0) [0|3] "" CEM
 SG_ StsOfSwvlgLe_UB : 35|1@0+ (1,0) [0|1] "" CEM
 SG_ StsOfTouristModLe : 25|2@0+ (1,0) [0|3] "" CEM
 SG_ StsOfTouristModLe_UB : 26|1@0+ (1,0) [0|1] "" CEM
 SG_ StsOfWelGbyFrntLe : 61|1@0+ (1,0) [0|1] "" CEM
 SG_ StsOfWelGbyFrntLe_UB : 60|1@0+ (1,0) [0|1] "" CEM

BO_ 1329 HcmlBodyExposedNMFr : 8 HCML
 SG_ PNC16_HCML : 16|1@0+ (1,0) [0|0] "" Vector_XXX
 SG_ PNC17_HCML : 17|1@0+ (1,0) [0|0] "" Vector_XXX
 SG_ PNC18_HCML : 18|1@0+ (1,0) [0|0] "" Vector_XXX
 SG_ PNC19_HCML : 19|1@0+ (1,0) [0|0] "" Vector_XXX
 SG_ PNC20_HCML : 20|1@0+ (1,0) [0|0] "" Vector_XXX
 SG_ PNC21_HCML : 21|1@0+ (1,0) [0|0] "" Vector_XXX
 SG_ PNC22_HCML : 22|1@0+ (1,0) [0|0] "" Vector_XXX
 SG_ PNC23_HCML : 23|1@0+ (1,0) [0|0] "" Vector_XXX
 SG_ PNC24_HCML : 24|1@0+ (1,0) [0|0] "" Vector_XXX
 SG_ PNC25_HCML : 25|1@0+ (1,0) [0|0] "" Vector_XXX
 SG_ PNC26_HCML : 26|1@0+ (1,0) [0|0] "" Vector_XXX
 SG_ PNC27_HCML : 27|1@0+ (1,0) [0|0] "" Vector_XXX
 SG_ PNC28_HCML : 28|1@0+ (1,0) [0|0] "" Vector_XXX
 SG_ PNC29_HCML : 29|1@0+ (1,0) [0|0] "" Vector_XXX
 SG_ PNC30_HCML : 30|1@0+ (1,0) [0|0] "" Vector_XXX
 SG_ PNC31_HCML : 31|1@0+ (1,0) [0|0] "" Vector_XXX
 SG_ PNC32_HCML : 32|1@0+ (1,0) [0|0] "" Vector_XXX
 SG_ PNC33_HCML : 33|1@0+ (1,0) [0|0] "" Vector_XXX
 SG_ PNC34_HCML : 34|1@0+ (1,0) [0|0] "" Vector_XXX
 SG_ PNC35_HCML : 35|1@0+ (1,0) [0|0] "" Vector_XXX
 SG_ PNC36_HCML : 36|1@0+ (1,0) [0|0] "" Vector_XXX
 SG_ PNC37_HCML : 37|1@0+ (1,0) [0|0] "" Vector_XXX
 SG_ PNC38_HCML : 38|1@0+ (1,0) [0|0] "" Vector_XXX
 SG_ PNC39_HCML : 39|1@0+ (1,0) [0|0] "" Vector_XXX
 SG_ PNC40_HCML : 40|1@0+ (1,0) [0|0] "" Vector_XXX
 SG_ PNC41_HCML : 41|1@0+ (1,0) [0|0] "" Vector_XXX
 SG_ PNC42_HCML : 42|1@0+ (1,0) [0|0] "" Vector_XXX
 SG_ NM_PNI_HCML : 14|1@0+ (1,0) [0|0] "" Vector_XXX
 SG_ NM_AW_HCML : 12|1@0+ (1,0) [0|0] "" Vector_XXX
 SG_ NM_CS_HCML : 11|1@0+ (1,0) [0|0] "" Vector_XXX
 SG_ NM_RMR_HCML : 8|1@0+ (1,0) [0|0] "" Vector_XXX
 SG_ NM_NodeID_HCML : 7|8@0+ (1,0) [0|0] "" Vector_XXX

BO_ 1715 HcmlToCemBodyCanExposedDiagResFrame : 8 HCML
 SG_ HcmlToCemBodyCanExpDiagResNpdu : 7|64@0+ (1,0) [0|0] "" CEM

BO_ 1424 HcmltoEtcXCPFr01 : 8 HCML

BO_ 594 HcmrBodyExpoFr02 : 3 HCMR
 SG_ ExtrLiShowStoreStsFrntRi : 7|1@0+ (1,0) [0|1] "" CEM
 SG_ ExtrLiShowStoreStsFrntRi_UB : 6|1@0+ (1,0) [0|1] "" CEM
 SG_ StsOfLedHiBeamRi : 1|2@0+ (1,0) [0|3] "" CEM
 SG_ StsOfLedHiBeamRi_UB : 2|1@0+ (1,0) [0|1] "" CEM
 SG_ StsOfLedLoBeamRi : 4|2@0+ (1,0) [0|3] "" CEM
 SG_ StsOfLedLoBeamRi_UB : 5|1@0+ (1,0) [0|1] "" CEM
 SG_ StsOfLedRiLogoLamp : 18|2@0+ (1,0) [0|3] "" CEM
 SG_ StsOfLedRiLogoLamp_UB : 16|1@0+ (1,0) [0|1] "" CEM

BO_ 127 HcmrBodyExpoFr04 : 8 HCMR
 SG_ DwnLoadStsFbOfHdlampRi : 5|2@0+ (1,0) [0|3] "" CEM
 SG_ DwnLoadStsFbOfHdlampRi_UB : 39|1@0+ (1,0) [0|1] "" CEM
 SG_ DwnLoadStsFbOfLogoLampRi : 57|2@0+ (1,0) [0|3] "" CEM
 SG_ DwnLoadStsFbOfLogoLampRi_UB : 21|1@0+ (1,0) [0|1] "" CEM
 SG_ ExtrLiShowActvnFrntRiFb : 28|2@0+ (1,0) [0|3] "" CEM
 SG_ ExtrLiShowActvnFrntRiFb_UB : 20|1@0+ (1,0) [0|1] "" CEM
 SG_ ExtrLiShowActvnRiLogoFb : 59|2@0+ (1,0) [0|3] "" CEM
 SG_ ExtrLiShowActvnRiLogoFb_UB : 22|1@0+ (1,0) [0|1] "" CEM
 SG_ HdlampRiInpSts1 : 49|1@0+ (1,0) [0|1] "" CEM
 SG_ HdlampRiInpSts1_UB : 48|1@0+ (1,0) [0|1] "" CEM
 SG_ HdlampRiInpSts2 : 63|1@0+ (1,0) [0|1] "" CEM
 SG_ HdlampRiInpSts2_UB : 62|1@0+ (1,0) [0|1] "" CEM
 SG_ StsOfAfsRi : 1|2@0+ (1,0) [0|3] "" CEM
 SG_ StsOfAfsRi_UB : 38|1@0+ (1,0) [0|1] "" CEM
 SG_ StsOfAhbcRi : 3|2@0+ (1,0) [0|3] "" CEM
 SG_ StsOfAhbcRi_UB : 37|1@0+ (1,0) [0|1] "" CEM
 SG_ StsOfFrntSideMkrLampRi2 : 9|2@0+ (1,0) [0|3] "" CEM
 SG_ StsOfFrntSideMkrLampRi2_UB : 34|1@0+ (1,0) [0|1] "" CEM
 SG_ StsOfLedCornrgLampRi : 11|2@0+ (1,0) [0|3] "" CEM
 SG_ StsOfLedCornrgLampRi_UB : 33|1@0+ (1,0) [0|1] "" CEM
 SG_ StsOfLedDaytiRunngLampRi : 13|2@0+ (1,0) [0|3] "" CEM
 SG_ StsOfLedDaytiRunngLampRi_UB : 32|1@0+ (1,0) [0|1] "" CEM
 SG_ StsOfLedFrntFogLampRi : 15|2@0+ (1,0) [0|3] "" CEM
 SG_ StsOfLedFrntFogLampRi_UB : 31|1@0+ (1,0) [0|1] "" CEM
 SG_ StsOfLedFrntPosnLampRi : 17|2@0+ (1,0) [0|3] "" CEM
 SG_ StsOfLedFrntPosnLampRi_UB : 30|1@0+ (1,0) [0|1] "" CEM
 SG_ StsOfLedFrntTurnIndcrRi : 19|2@0+ (1,0) [0|3] "" CEM
 SG_ StsOfLedFrntTurnIndcrRi_UB : 29|1@0+ (1,0) [0|1] "" CEM
 SG_ StsOfLvlgRi_UB : 36|1@0+ (1,0) [0|1] "" CEM
 SG_ StsOfLvlgRiChks : 47|8@0+ (1.0,0.0) [0.0|255.0] "Unitless" CEM
 SG_ StsOfLvlgRiCntr : 55|4@0+ (1.0,0.0) [0.0|15.0] "Unitless" CEM
 SG_ StsOfLvlgRiStsOfLvlgRi : 51|2@0+ (1,0) [0|3] "" CEM
 SG_ StsOfSwvlgRi : 7|2@0+ (1,0) [0|3] "" CEM
 SG_ StsOfSwvlgRi_UB : 35|1@0+ (1,0) [0|1] "" CEM
 SG_ StsOfTouristModRi : 25|2@0+ (1,0) [0|3] "" CEM
 SG_ StsOfTouristModRi_UB : 26|1@0+ (1,0) [0|1] "" CEM
 SG_ StsOfWelGbyFrntRi : 61|1@0+ (1,0) [0|1] "" CEM
 SG_ StsOfWelGbyFrntRi_UB : 60|1@0+ (1,0) [0|1] "" CEM

BO_ 1330 HcmrBodyExposedNMFr : 8 HCMR
 SG_ PNC16_HCMR : 16|1@0+ (1,0) [0|0] "" HCML
 SG_ PNC17_HCMR : 17|1@0+ (1,0) [0|0] "" HCML
 SG_ PNC18_HCMR : 18|1@0+ (1,0) [0|0] "" HCML
 SG_ PNC19_HCMR : 19|1@0+ (1,0) [0|0] "" HCML
 SG_ PNC20_HCMR : 20|1@0+ (1,0) [0|0] "" HCML
 SG_ PNC21_HCMR : 21|1@0+ (1,0) [0|0] "" HCML
 SG_ PNC22_HCMR : 22|1@0+ (1,0) [0|0] "" HCML
 SG_ PNC23_HCMR : 23|1@0+ (1,0) [0|0] "" HCML
 SG_ PNC24_HCMR : 24|1@0+ (1,0) [0|0] "" HCML
 SG_ PNC25_HCMR : 25|1@0+ (1,0) [0|0] "" HCML
 SG_ PNC26_HCMR : 26|1@0+ (1,0) [0|0] "" HCML
 SG_ PNC27_HCMR : 27|1@0+ (1,0) [0|0] "" HCML
 SG_ PNC28_HCMR : 28|1@0+ (1,0) [0|0] "" HCML
 SG_ PNC29_HCMR : 29|1@0+ (1,0) [0|0] "" HCML
 SG_ PNC30_HCMR : 30|1@0+ (1,0) [0|0] "" HCML
 SG_ PNC31_HCMR : 31|1@0+ (1,0) [0|0] "" HCML
 SG_ PNC32_HCMR : 32|1@0+ (1,0) [0|0] "" HCML
 SG_ PNC33_HCMR : 33|1@0+ (1,0) [0|0] "" HCML
 SG_ PNC34_HCMR : 34|1@0+ (1,0) [0|0] "" HCML
 SG_ PNC35_HCMR : 35|1@0+ (1,0) [0|0] "" HCML
 SG_ PNC36_HCMR : 36|1@0+ (1,0) [0|0] "" HCML
 SG_ PNC37_HCMR : 37|1@0+ (1,0) [0|0] "" HCML
 SG_ PNC38_HCMR : 38|1@0+ (1,0) [0|0] "" HCML
 SG_ PNC39_HCMR : 39|1@0+ (1,0) [0|0] "" HCML
 SG_ PNC40_HCMR : 40|1@0+ (1,0) [0|0] "" HCML
 SG_ PNC41_HCMR : 41|1@0+ (1,0) [0|0] "" HCML
 SG_ PNC42_HCMR : 42|1@0+ (1,0) [0|0] "" HCML
 SG_ NM_PNI_HCMR : 14|1@0+ (1,0) [0|0] "" HCML
 SG_ NM_AW_HCMR : 12|1@0+ (1,0) [0|0] "" HCML
 SG_ NM_CS_HCMR : 11|1@0+ (1,0) [0|0] "" HCML
 SG_ NM_RMR_HCMR : 8|1@0+ (1,0) [0|0] "" HCML
 SG_ NM_NodeID_HCMR : 7|8@0+ (1,0) [0|0] "" HCML

BO_ 1716 HcmrToCemBodyCanExposedDiagResFrame : 8 HCMR
 SG_ HcmrToCemBodyCanExpDiagResNpdu : 7|64@0+ (1,0) [0|0] "" CEM

BO_ 1426 HcmrtoEtcXCPFr01 : 8 HCMR

BO_ 592 RcmlBodyExpoFr01 : 8 RCML
 SG_ DwnLoadStsFbOfReLampCtrlLe1 : 17|2@0+ (1,0) [0|3] "" CEM
 SG_ DwnLoadStsFbOfReLampCtrlLe1_UB : 27|1@0+ (1,0) [0|1] "" CEM
 SG_ ExtrLiShowActvnReLeFb : 19|2@0+ (1,0) [0|3] "" CEM
 SG_ ExtrLiShowActvnReLeFb_UB : 26|1@0+ (1,0) [0|1] "" CEM
 SG_ ExtrLiShowStoreStsReLe1 : 1|1@0+ (1,0) [0|1] "" CEM
 SG_ ExtrLiShowStoreStsReLe1_UB : 0|1@0+ (1,0) [0|1] "" CEM
 SG_ StsOfLedPosnLampLe1 : 9|2@0+ (1,0) [0|3] "" CEM
 SG_ StsOfLedPosnLampLe1_UB : 25|1@0+ (1,0) [0|1] "" CEM
 SG_ StsOfLedReFogLampLe1 : 11|2@0+ (1,0) [0|3] "" CEM
 SG_ StsOfLedReFogLampLe1_UB : 24|1@0+ (1,0) [0|1] "" CEM
 SG_ StsOfLedReLampLe1 : 13|2@0+ (1,0) [0|3] "" CEM
 SG_ StsOfLedReLampLe1_UB : 23|1@0+ (1,0) [0|1] "" CEM
 SG_ StsOfLedRvsgLampLe1 : 15|2@0+ (1,0) [0|3] "" CEM
 SG_ StsOfLedRvsgLampLe1_UB : 22|1@0+ (1,0) [0|1] "" CEM
 SG_ StsOfLedStopLampLe1 : 21|2@0+ (1,0) [0|3] "" CEM
 SG_ StsOfLedStopLampLe1_UB : 30|1@0+ (1,0) [0|1] "" CEM
 SG_ StsOfLedTurnIndcrLe1 : 29|2@0+ (1,0) [0|3] "" CEM
 SG_ StsOfLedTurnIndcrLe1_UB : 31|1@0+ (1,0) [0|1] "" CEM
 SG_ StsOfWelGbyReLe1 : 39|1@0+ (1,0) [0|1] "" CEM
 SG_ StsOfWelGbyReLe1_UB : 38|1@0+ (1,0) [0|1] "" CEM

BO_ 1331 RcmlBodyExposedNMFr : 8 RCML
 SG_ PNC16_RCML : 16|1@0+ (1,0) [0|0] "" Vector_XXX
 SG_ PNC17_RCML : 17|1@0+ (1,0) [0|0] "" Vector_XXX
 SG_ PNC18_RCML : 18|1@0+ (1,0) [0|0] "" Vector_XXX
 SG_ PNC19_RCML : 19|1@0+ (1,0) [0|0] "" Vector_XXX
 SG_ PNC20_RCML : 20|1@0+ (1,0) [0|0] "" Vector_XXX
 SG_ PNC21_RCML : 21|1@0+ (1,0) [0|0] "" Vector_XXX
 SG_ PNC22_RCML : 22|1@0+ (1,0) [0|0] "" Vector_XXX
 SG_ PNC23_RCML : 23|1@0+ (1,0) [0|0] "" Vector_XXX
 SG_ PNC24_RCML : 24|1@0+ (1,0) [0|0] "" Vector_XXX
 SG_ PNC25_RCML : 25|1@0+ (1,0) [0|0] "" Vector_XXX
 SG_ PNC26_RCML : 26|1@0+ (1,0) [0|0] "" Vector_XXX
 SG_ PNC27_RCML : 27|1@0+ (1,0) [0|0] "" Vector_XXX
 SG_ PNC28_RCML : 28|1@0+ (1,0) [0|0] "" Vector_XXX
 SG_ PNC29_RCML : 29|1@0+ (1,0) [0|0] "" Vector_XXX
 SG_ PNC30_RCML : 30|1@0+ (1,0) [0|0] "" Vector_XXX
 SG_ PNC31_RCML : 31|1@0+ (1,0) [0|0] "" Vector_XXX
 SG_ PNC32_RCML : 32|1@0+ (1,0) [0|0] "" Vector_XXX
 SG_ PNC33_RCML : 33|1@0+ (1,0) [0|0] "" Vector_XXX
 SG_ PNC34_RCML : 34|1@0+ (1,0) [0|0] "" Vector_XXX
 SG_ PNC35_RCML : 35|1@0+ (1,0) [0|0] "" Vector_XXX
 SG_ PNC36_RCML : 36|1@0+ (1,0) [0|0] "" Vector_XXX
 SG_ PNC37_RCML : 37|1@0+ (1,0) [0|0] "" Vector_XXX
 SG_ PNC38_RCML : 38|1@0+ (1,0) [0|0] "" Vector_XXX
 SG_ PNC39_RCML : 39|1@0+ (1,0) [0|0] "" Vector_XXX
 SG_ PNC40_RCML : 40|1@0+ (1,0) [0|0] "" Vector_XXX
 SG_ PNC41_RCML : 41|1@0+ (1,0) [0|0] "" Vector_XXX
 SG_ PNC42_RCML : 42|1@0+ (1,0) [0|0] "" Vector_XXX
 SG_ NM_PNI_RCML : 14|1@0+ (1,0) [0|0] "" Vector_XXX
 SG_ NM_AW_RCML : 12|1@0+ (1,0) [0|0] "" Vector_XXX
 SG_ NM_CS_RCML : 11|1@0+ (1,0) [0|0] "" Vector_XXX
 SG_ NM_RMR_RCML : 8|1@0+ (1,0) [0|0] "" Vector_XXX
 SG_ NM_NodeID_RCML : 7|8@0+ (1,0) [0|0] "" Vector_XXX

BO_ 1717 RcmlToCemBodyCanExposedDiagResFrame : 8 RCML
 SG_ RcmlToCemBodyCanExpDiagResNpdu : 7|64@0+ (1,0) [0|0] "" CEM

BO_ 596 RcmmBodyExpoFr02 : 8 RCMM
 SG_ DwnLoadStsFbOfReLampCtrlLe2 : 1|2@0+ (1,0) [0|3] "" CEM
 SG_ DwnLoadStsFbOfReLampCtrlLe2_UB : 47|1@0+ (1,0) [0|1] "" CEM
 SG_ DwnLoadStsFbOfReLampCtrlRi2 : 3|2@0+ (1,0) [0|3] "" CEM
 SG_ DwnLoadStsFbOfReLampCtrlRi2_UB : 46|1@0+ (1,0) [0|1] "" CEM
 SG_ ExtrLiShowActvnReLe2Fb : 5|2@0+ (1,0) [0|3] "" CEM
 SG_ ExtrLiShowActvnReLe2Fb_UB : 45|1@0+ (1,0) [0|1] "" CEM
 SG_ ExtrLiShowActvnReRi2Fb : 7|2@0+ (1,0) [0|3] "" CEM
 SG_ ExtrLiShowActvnReRi2Fb_UB : 44|1@0+ (1,0) [0|1] "" CEM
 SG_ ExtrLiShowStoreStsReLe2 : 51|1@0+ (1,0) [0|1] "" CEM
 SG_ ExtrLiShowStoreStsReLe2_UB : 50|1@0+ (1,0) [0|1] "" CEM
 SG_ ExtrLiShowStoreStsReRi2 : 49|1@0+ (1,0) [0|1] "" CEM
 SG_ ExtrLiShowStoreStsReRi2_UB : 48|1@0+ (1,0) [0|1] "" CEM
 SG_ StsOfLedPosnLampLe2 : 9|2@0+ (1,0) [0|3] "" CEM
 SG_ StsOfLedPosnLampLe2_UB : 43|1@0+ (1,0) [0|1] "" CEM
 SG_ StsOfLedPosnLampRi2 : 11|2@0+ (1,0) [0|3] "" CEM
 SG_ StsOfLedPosnLampRi2_UB : 42|1@0+ (1,0) [0|1] "" CEM
 SG_ StsOfLedReFogLampLe2 : 13|2@0+ (1,0) [0|3] "" CEM
 SG_ StsOfLedReFogLampLe2_UB : 41|1@0+ (1,0) [0|1] "" CEM
 SG_ StsOfLedReFogLampRi2 : 15|2@0+ (1,0) [0|3] "" CEM
 SG_ StsOfLedReFogLampRi2_UB : 40|1@0+ (1,0) [0|1] "" CEM
 SG_ StsOfLedReLampLe2 : 17|2@0+ (1,0) [0|3] "" CEM
 SG_ StsOfLedReLampLe2_UB : 39|1@0+ (1,0) [0|1] "" CEM
 SG_ StsOfLedReLampRi2 : 19|2@0+ (1,0) [0|3] "" CEM
 SG_ StsOfLedReLampRi2_UB : 38|1@0+ (1,0) [0|1] "" CEM
 SG_ StsOfLedRvsgLampLe2 : 21|2@0+ (1,0) [0|3] "" CEM
 SG_ StsOfLedRvsgLampLe2_UB : 37|1@0+ (1,0) [0|1] "" CEM
 SG_ StsOfLedRvsgLampRi2 : 23|2@0+ (1,0) [0|3] "" CEM
 SG_ StsOfLedRvsgLampRi2_UB : 36|1@0+ (1,0) [0|1] "" CEM
 SG_ StsOfLedStopLampLe2 : 25|2@0+ (1,0) [0|3] "" CEM
 SG_ StsOfLedStopLampLe2_UB : 35|1@0+ (1,0) [0|1] "" CEM
 SG_ StsOfLedStopLampRi2 : 27|2@0+ (1,0) [0|3] "" CEM
 SG_ StsOfLedStopLampRi2_UB : 34|1@0+ (1,0) [0|1] "" CEM
 SG_ StsOfLedTurnIndcrLe2 : 29|2@0+ (1,0) [0|3] "" CEM
 SG_ StsOfLedTurnIndcrLe2_UB : 33|1@0+ (1,0) [0|1] "" CEM
 SG_ StsOfLedTurnIndcrRi2 : 31|2@0+ (1,0) [0|3] "" CEM
 SG_ StsOfLedTurnIndcrRi2_UB : 32|1@0+ (1,0) [0|1] "" CEM
 SG_ StsOfWelGbyReLe2 : 55|1@0+ (1,0) [0|1] "" CEM
 SG_ StsOfWelGbyReLe2_UB : 54|1@0+ (1,0) [0|1] "" CEM
 SG_ StsOfWelGbyReRi2 : 53|1@0+ (1,0) [0|1] "" CEM
 SG_ StsOfWelGbyReRi2_UB : 52|1@0+ (1,0) [0|1] "" CEM

BO_ 1333 RcmmBodyExposedNMFr : 8 RCMM
 SG_ PNC16_RCMM : 16|1@0+ (1,0) [0|0] "" RCML
 SG_ PNC17_RCMM : 17|1@0+ (1,0) [0|0] "" RCML
 SG_ PNC18_RCMM : 18|1@0+ (1,0) [0|0] "" RCML
 SG_ PNC19_RCMM : 19|1@0+ (1,0) [0|0] "" RCML
 SG_ PNC20_RCMM : 20|1@0+ (1,0) [0|0] "" RCML
 SG_ PNC21_RCMM : 21|1@0+ (1,0) [0|0] "" RCML
 SG_ PNC22_RCMM : 22|1@0+ (1,0) [0|0] "" RCML
 SG_ PNC23_RCMM : 23|1@0+ (1,0) [0|0] "" RCML
 SG_ PNC24_RCMM : 24|1@0+ (1,0) [0|0] "" RCML
 SG_ PNC25_RCMM : 25|1@0+ (1,0) [0|0] "" RCML
 SG_ PNC26_RCMM : 26|1@0+ (1,0) [0|0] "" RCML
 SG_ PNC27_RCMM : 27|1@0+ (1,0) [0|0] "" RCML
 SG_ PNC28_RCMM : 28|1@0+ (1,0) [0|0] "" RCML
 SG_ PNC29_RCMM : 29|1@0+ (1,0) [0|0] "" RCML
 SG_ PNC30_RCMM : 30|1@0+ (1,0) [0|0] "" RCML
 SG_ PNC31_RCMM : 31|1@0+ (1,0) [0|0] "" RCML
 SG_ PNC32_RCMM : 32|1@0+ (1,0) [0|0] "" RCML
 SG_ PNC33_RCMM : 33|1@0+ (1,0) [0|0] "" RCML
 SG_ PNC34_RCMM : 34|1@0+ (1,0) [0|0] "" RCML
 SG_ PNC35_RCMM : 35|1@0+ (1,0) [0|0] "" RCML
 SG_ PNC36_RCMM : 36|1@0+ (1,0) [0|0] "" RCML
 SG_ PNC37_RCMM : 37|1@0+ (1,0) [0|0] "" RCML
 SG_ PNC38_RCMM : 38|1@0+ (1,0) [0|0] "" RCML
 SG_ PNC39_RCMM : 39|1@0+ (1,0) [0|0] "" RCML
 SG_ PNC40_RCMM : 40|1@0+ (1,0) [0|0] "" RCML
 SG_ PNC41_RCMM : 41|1@0+ (1,0) [0|0] "" RCML
 SG_ PNC42_RCMM : 42|1@0+ (1,0) [0|0] "" RCML
 SG_ NM_PNI_RCMM : 14|1@0+ (1,0) [0|0] "" RCML
 SG_ NM_AW_RCMM : 12|1@0+ (1,0) [0|0] "" RCML
 SG_ NM_CS_RCMM : 11|1@0+ (1,0) [0|0] "" RCML
 SG_ NM_RMR_RCMM : 8|1@0+ (1,0) [0|0] "" RCML
 SG_ NM_NodeID_RCMM : 7|8@0+ (1,0) [0|0] "" RCML

BO_ 1719 RcmmToCemBodyCanExposedDiagResFrame : 8 RCMM
 SG_ RcmmToCemBodyCanExpDiagResNpdu : 7|64@0+ (1,0) [0|0] "" CEM

BO_ 608 RcmrBodyExpoFr01 : 8 RCMR
 SG_ DwnLoadStsFbOfReLampCtrlRi1 : 17|2@0+ (1,0) [0|3] "" CEM
 SG_ DwnLoadStsFbOfReLampCtrlRi1_UB : 20|1@0+ (1,0) [0|1] "" CEM
 SG_ ExtrLiShowActvnReRiFb : 19|2@0+ (1,0) [0|3] "" CEM
 SG_ ExtrLiShowActvnReRiFb_UB : 21|1@0+ (1,0) [0|1] "" CEM
 SG_ ExtrLiShowStoreStsReRi1 : 1|1@0+ (1,0) [0|1] "" CEM
 SG_ ExtrLiShowStoreStsReRi1_UB : 0|1@0+ (1,0) [0|1] "" CEM
 SG_ StsOfLedPosnLampRi1 : 9|2@0+ (1,0) [0|3] "" CEM
 SG_ StsOfLedPosnLampRi1_UB : 31|1@0+ (1,0) [0|1] "" CEM
 SG_ StsOfLedReFogLampRi1 : 11|2@0+ (1,0) [0|3] "" CEM
 SG_ StsOfLedReFogLampRi1_UB : 30|1@0+ (1,0) [0|1] "" CEM
 SG_ StsOfLedReLampRi1 : 13|2@0+ (1,0) [0|3] "" CEM
 SG_ StsOfLedReLampRi1_UB : 29|1@0+ (1,0) [0|1] "" CEM
 SG_ StsOfLedRvsgLampRi1 : 15|2@0+ (1,0) [0|3] "" CEM
 SG_ StsOfLedRvsgLampRi1_UB : 28|1@0+ (1,0) [0|1] "" CEM
 SG_ StsOfLedStopLampRi1 : 23|2@0+ (1,0) [0|3] "" CEM
 SG_ StsOfLedStopLampRi1_UB : 27|1@0+ (1,0) [0|1] "" CEM
 SG_ StsOfLedTurnIndcrRi1 : 25|2@0+ (1,0) [0|3] "" CEM
 SG_ StsOfLedTurnIndcrRi1_UB : 26|1@0+ (1,0) [0|1] "" CEM
 SG_ StsOfWelGbyReRi1 : 39|1@0+ (1,0) [0|1] "" CEM
 SG_ StsOfWelGbyReRi1_UB : 38|1@0+ (1,0) [0|1] "" CEM

BO_ 1332 RcmrBodyExposedNMFr : 8 RCMR
 SG_ PNC16_RCMR : 16|1@0+ (1,0) [0|0] "" RCMM
 SG_ PNC17_RCMR : 17|1@0+ (1,0) [0|0] "" RCMM
 SG_ PNC18_RCMR : 18|1@0+ (1,0) [0|0] "" RCMM
 SG_ PNC19_RCMR : 19|1@0+ (1,0) [0|0] "" RCMM
 SG_ PNC20_RCMR : 20|1@0+ (1,0) [0|0] "" RCMM
 SG_ PNC21_RCMR : 21|1@0+ (1,0) [0|0] "" RCMM
 SG_ PNC22_RCMR : 22|1@0+ (1,0) [0|0] "" RCMM
 SG_ PNC23_RCMR : 23|1@0+ (1,0) [0|0] "" RCMM
 SG_ PNC24_RCMR : 24|1@0+ (1,0) [0|0] "" RCMM
 SG_ PNC25_RCMR : 25|1@0+ (1,0) [0|0] "" RCMM
 SG_ PNC26_RCMR : 26|1@0+ (1,0) [0|0] "" RCMM
 SG_ PNC27_RCMR : 27|1@0+ (1,0) [0|0] "" RCMM
 SG_ PNC28_RCMR : 28|1@0+ (1,0) [0|0] "" RCMM
 SG_ PNC29_RCMR : 29|1@0+ (1,0) [0|0] "" RCMM
 SG_ PNC30_RCMR : 30|1@0+ (1,0) [0|0] "" RCMM
 SG_ PNC31_RCMR : 31|1@0+ (1,0) [0|0] "" RCMM
 SG_ PNC32_RCMR : 32|1@0+ (1,0) [0|0] "" RCMM
 SG_ PNC33_RCMR : 33|1@0+ (1,0) [0|0] "" RCMM
 SG_ PNC34_RCMR : 34|1@0+ (1,0) [0|0] "" RCMM
 SG_ PNC35_RCMR : 35|1@0+ (1,0) [0|0] "" RCMM
 SG_ PNC36_RCMR : 36|1@0+ (1,0) [0|0] "" RCMM
 SG_ PNC37_RCMR : 37|1@0+ (1,0) [0|0] "" RCMM
 SG_ PNC38_RCMR : 38|1@0+ (1,0) [0|0] "" RCMM
 SG_ PNC39_RCMR : 39|1@0+ (1,0) [0|0] "" RCMM
 SG_ PNC40_RCMR : 40|1@0+ (1,0) [0|0] "" RCMM
 SG_ PNC41_RCMR : 41|1@0+ (1,0) [0|0] "" RCMM
 SG_ PNC42_RCMR : 42|1@0+ (1,0) [0|0] "" RCMM
 SG_ NM_PNI_RCMR : 14|1@0+ (1,0) [0|0] "" RCMM
 SG_ NM_AW_RCMR : 12|1@0+ (1,0) [0|0] "" RCMM
 SG_ NM_CS_RCMR : 11|1@0+ (1,0) [0|0] "" RCMM
 SG_ NM_RMR_RCMR : 8|1@0+ (1,0) [0|0] "" RCMM
 SG_ NM_NodeID_RCMR : 7|8@0+ (1,0) [0|0] "" RCMM

BO_ 1718 RcmrToCemBodyCanExposedDiagResFrame : 8 RCMR
 SG_ RcmrToCemBodyCanExpDiagResNpdu : 7|64@0+ (1,0) [0|0] "" CEM

CM_ SG_ 789 DHUcontrolCrossreversinglight "DHU control Cross reversing light
0 = OnOffNoReqNoReq
1 = OnOffNoReqOn
2 = OnOffNoReqOff";
CM_ SG_ 789 DHUcontrolleftbrakelightLamp "DHU control left brakelight Lamp
0 = OnOffNoReqNoReq
1 = OnOffNoReqOn
2 = OnOffNoReqOff";
CM_ SG_ 789 DHUcontrolleftpositionlight "DHU control left position light
0 = OnOffNoReqNoReq
1 = OnOffNoReqOn
2 = OnOffNoReqOff";
CM_ SG_ 789 DHUcontrolrightbrakelight "DHU control right brake light
0 = OnOffNoReqNoReq
1 = OnOffNoReqOn
2 = OnOffNoReqOff

";
CM_ SG_ 335 DwnLoadDynLitPrmLedFrntMidPosnLiContTiPrm "Light Show Continue Time Parameter 1";
CM_ SG_ 335 DwnLoadDynLitPrmLedFrntMidPosnLiLowBriPrm "Light Show Lower Brightness Parameter 1";
CM_ SG_ 335 DwnLoadDynLitPrmLedFrntMidPosnLiModePrm "Light Show Mode Parameter 1";
CM_ SG_ 335 DwnLoadDynLitPrmLedFrntMidPosnLiOffsTiPrm "Light Show Offset Time Parameter 1";
CM_ SG_ 335 DwnLoadDynLitPrmLedFrntMidPosnLiTistamp "Light Show time stamp";
CM_ SG_ 335 DwnLoadDynLitPrmLedFrntMidPosnLiUpprBriPrm "Light Show Upper Brightness Parameter 1";
CM_ SG_ 336 DwnLoadDynLitPrmLedLeSideLogoLiContTiPrm "Light Show Continue Time Parameter 1";
CM_ SG_ 336 DwnLoadDynLitPrmLedLeSideLogoLiLowBriPrm "Light Show Lower Brightness Parameter 1";
CM_ SG_ 336 DwnLoadDynLitPrmLedLeSideLogoLiModePrm "Light Show Mode Parameter 1";
CM_ SG_ 336 DwnLoadDynLitPrmLedLeSideLogoLiOffsTiPrm "Light Show Offset Time Parameter 1";
CM_ SG_ 336 DwnLoadDynLitPrmLedLeSideLogoLiTistamp "Light Show time stamp";
CM_ SG_ 336 DwnLoadDynLitPrmLedLeSideLogoLiUpprBriPrm "Light Show Upper Brightness Parameter 1";
CM_ SG_ 337 DwnLoadDynLitPrmLedRiSideLogoLiContTiPrm "Light Show Continue Time Parameter 1";
CM_ SG_ 337 DwnLoadDynLitPrmLedRiSideLogoLiLowBriPrm "Light Show Lower Brightness Parameter 1";
CM_ SG_ 337 DwnLoadDynLitPrmLedRiSideLogoLiModePrm "Light Show Mode Parameter 1";
CM_ SG_ 337 DwnLoadDynLitPrmLedRiSideLogoLiOffsTiPrm "Light Show Offset Time Parameter 1";
CM_ SG_ 337 DwnLoadDynLitPrmLedRiSideLogoLiTistamp "Light Show time stamp";
CM_ SG_ 337 DwnLoadDynLitPrmLedRiSideLogoLiUpprBriPrm "Light Show Upper Brightness Parameter 1";
CM_ SG_ 801 DHUcontrolLedLogoLamp "DHU control active LedLogo Lamp";
CM_ SG_ 801 DwnLoadDynLtgPrmForFrntLeGrp1ContinueTime "Light Show Continue Time Parameter 2";
CM_ SG_ 801 DwnLoadDynLtgPrmForFrntLeGrp1HighBrightness "Light Show Upper Brightness Parameter 2";
CM_ SG_ 801 DwnLoadDynLtgPrmForFrntLeGrp1LowBrightness "Light Show Lower Brightness Parameter 2";
CM_ SG_ 801 DwnLoadDynLtgPrmForFrntLeGrp1Mode1 "Light Show Mode Parameter 2";
CM_ SG_ 801 DwnLoadDynLtgPrmForFrntLeGrp1OffsetTime "Light Show Offset Time Parameter 2";
CM_ SG_ 801 DwnLoadDynLtgPrmForFrntLeGrp1Timestamp "Light Show time stamp 2";
CM_ SG_ 801 WelLiFileTxReq "Request signal for transferring sequence table. If the value has been set to on, the parameter of lamp elements can be downloaded from DHU to HCM/RCM. ";
CM_ SG_ 802 DwnLoadDynLtgPrmForFrntLeGrp2ContinueTime "Light Show Continue Time Parameter 2";
CM_ SG_ 802 DwnLoadDynLtgPrmForFrntLeGrp2HighBrightness "Light Show Upper Brightness Parameter 2";
CM_ SG_ 802 DwnLoadDynLtgPrmForFrntLeGrp2LowBrightness "Light Show Lower Brightness Parameter 2";
CM_ SG_ 802 DwnLoadDynLtgPrmForFrntLeGrp2Mode1 "Light Show Mode Parameter 2";
CM_ SG_ 802 DwnLoadDynLtgPrmForFrntLeGrp2OffsetTime "Light Show Offset Time Parameter 2";
CM_ SG_ 802 DwnLoadDynLtgPrmForFrntLeGrp2Timestamp "Light Show time stamp 2";
CM_ SG_ 803 DwnLoadDynLtgPrmForFrntLeGrp3ContinueTime "Light Show Continue Time Parameter 2";
CM_ SG_ 803 DwnLoadDynLtgPrmForFrntLeGrp3HighBrightness "Light Show Upper Brightness Parameter 2";
CM_ SG_ 803 DwnLoadDynLtgPrmForFrntLeGrp3LowBrightness "Light Show Lower Brightness Parameter 2";
CM_ SG_ 803 DwnLoadDynLtgPrmForFrntLeGrp3Mode1 "Light Show Mode Parameter 2";
CM_ SG_ 803 DwnLoadDynLtgPrmForFrntLeGrp3OffsetTime "Light Show Offset Time Parameter 2";
CM_ SG_ 803 DwnLoadDynLtgPrmForFrntLeGrp3Timestamp "Light Show time stamp 2";
CM_ SG_ 804 DwnLoadDynLtgPrmForFrntLeGrp4ContinueTime "Light Show Continue Time Parameter 2";
CM_ SG_ 804 DwnLoadDynLtgPrmForFrntLeGrp4HighBrightness "Light Show Upper Brightness Parameter 2";
CM_ SG_ 804 DwnLoadDynLtgPrmForFrntLeGrp4LowBrightness "Light Show Lower Brightness Parameter 2";
CM_ SG_ 804 DwnLoadDynLtgPrmForFrntLeGrp4Mode1 "Light Show Mode Parameter 2";
CM_ SG_ 804 DwnLoadDynLtgPrmForFrntLeGrp4OffsetTime "Light Show Offset Time Parameter 2";
CM_ SG_ 804 DwnLoadDynLtgPrmForFrntLeGrp4Timestamp "Light Show time stamp 2";
CM_ SG_ 805 DwnLoadDynLtgPrmForFrntLeGrp5ContinueTime "Light Show Continue Time Parameter 2";
CM_ SG_ 805 DwnLoadDynLtgPrmForFrntLeGrp5HighBrightness "Light Show Upper Brightness Parameter 2";
CM_ SG_ 805 DwnLoadDynLtgPrmForFrntLeGrp5LowBrightness "Light Show Lower Brightness Parameter 2";
CM_ SG_ 805 DwnLoadDynLtgPrmForFrntLeGrp5Mode1 "Light Show Mode Parameter 2";
CM_ SG_ 805 DwnLoadDynLtgPrmForFrntLeGrp5OffsetTime "Light Show Offset Time Parameter 2";
CM_ SG_ 805 DwnLoadDynLtgPrmForFrntLeGrp5Timestamp "Light Show time stamp 2";
CM_ SG_ 806 DwnLoadDynLtgPrmForFrntLeGrp6ContinueTime "Light Show Continue Time Parameter 2";
CM_ SG_ 806 DwnLoadDynLtgPrmForFrntLeGrp6HighBrightness "Light Show Upper Brightness Parameter 2";
CM_ SG_ 806 DwnLoadDynLtgPrmForFrntLeGrp6LowBrightness "Light Show Lower Brightness Parameter 2";
CM_ SG_ 806 DwnLoadDynLtgPrmForFrntLeGrp6Mode1 "Light Show Mode Parameter 2";
CM_ SG_ 806 DwnLoadDynLtgPrmForFrntLeGrp6OffsetTime "Light Show Offset Time Parameter 2";
CM_ SG_ 806 DwnLoadDynLtgPrmForFrntLeGrp6Timestamp "Light Show time stamp 2";
CM_ SG_ 807 DwnLoadDynLtgPrmForFrntLeGrp7ContinueTime "Light Show Continue Time Parameter 2";
CM_ SG_ 807 DwnLoadDynLtgPrmForFrntLeGrp7HighBrightness "Light Show Upper Brightness Parameter 2";
CM_ SG_ 807 DwnLoadDynLtgPrmForFrntLeGrp7LowBrightness "Light Show Lower Brightness Parameter 2";
CM_ SG_ 807 DwnLoadDynLtgPrmForFrntLeGrp7Mode1 "Light Show Mode Parameter 2";
CM_ SG_ 807 DwnLoadDynLtgPrmForFrntLeGrp7OffsetTime "Light Show Offset Time Parameter 2";
CM_ SG_ 807 DwnLoadDynLtgPrmForFrntLeGrp7Timestamp "Light Show time stamp 2";
CM_ SG_ 808 DwnLoadDynLtgPrmForFrntLeGrp8ContinueTime "Light Show Continue Time Parameter 2";
CM_ SG_ 808 DwnLoadDynLtgPrmForFrntLeGrp8HighBrightness "Light Show Upper Brightness Parameter 2";
CM_ SG_ 808 DwnLoadDynLtgPrmForFrntLeGrp8LowBrightness "Light Show Lower Brightness Parameter 2";
CM_ SG_ 808 DwnLoadDynLtgPrmForFrntLeGrp8Mode1 "Light Show Mode Parameter 2";
CM_ SG_ 808 DwnLoadDynLtgPrmForFrntLeGrp8OffsetTime "Light Show Offset Time Parameter 2";
CM_ SG_ 808 DwnLoadDynLtgPrmForFrntLeGrp8Timestamp "Light Show time stamp 2";
CM_ SG_ 809 DwnLoadDynLtgPrmForFrntLeGrp9ContinueTime "Light Show Continue Time Parameter 2";
CM_ SG_ 809 DwnLoadDynLtgPrmForFrntLeGrp9HighBrightness "Light Show Upper Brightness Parameter 2";
CM_ SG_ 809 DwnLoadDynLtgPrmForFrntLeGrp9LowBrightness "Light Show Lower Brightness Parameter 2";
CM_ SG_ 809 DwnLoadDynLtgPrmForFrntLeGrp9Mode1 "Light Show Mode Parameter 2";
CM_ SG_ 809 DwnLoadDynLtgPrmForFrntLeGrp9OffsetTime "Light Show Offset Time Parameter 2";
CM_ SG_ 809 DwnLoadDynLtgPrmForFrntLeGrp9Timestamp "Light Show time stamp 2";
CM_ SG_ 810 DwnLoadDynLtgPrmForFrntLeGrp10ContinueTime "Light Show Continue Time Parameter 2";
CM_ SG_ 810 DwnLoadDynLtgPrmForFrntLeGrp10HighBrightness "Light Show Upper Brightness Parameter 2";
CM_ SG_ 810 DwnLoadDynLtgPrmForFrntLeGrp10LowBrightness "Light Show Lower Brightness Parameter 2";
CM_ SG_ 810 DwnLoadDynLtgPrmForFrntLeGrp10Mode1 "Light Show Mode Parameter 2";
CM_ SG_ 810 DwnLoadDynLtgPrmForFrntLeGrp10OffsetTime "Light Show Offset Time Parameter 2";
CM_ SG_ 810 DwnLoadDynLtgPrmForFrntLeGrp10Timestamp "Light Show time stamp 2";
CM_ SG_ 811 DwnLoadDynLtgPrmForFrntLeGrp11ContinueTime "Light Show Continue Time Parameter 2";
CM_ SG_ 811 DwnLoadDynLtgPrmForFrntLeGrp11HighBrightness "Light Show Upper Brightness Parameter 2";
CM_ SG_ 811 DwnLoadDynLtgPrmForFrntLeGrp11LowBrightness "Light Show Lower Brightness Parameter 2";
CM_ SG_ 811 DwnLoadDynLtgPrmForFrntLeGrp11Mode1 "Light Show Mode Parameter 2";
CM_ SG_ 811 DwnLoadDynLtgPrmForFrntLeGrp11OffsetTime "Light Show Offset Time Parameter 2";
CM_ SG_ 811 DwnLoadDynLtgPrmForFrntLeGrp11Timestamp "Light Show time stamp 2";
CM_ SG_ 812 DwnLoadDynLtgPrmForFrntLeGrp12ContinueTime "Light Show Continue Time Parameter 2";
CM_ SG_ 812 DwnLoadDynLtgPrmForFrntLeGrp12HighBrightness "Light Show Upper Brightness Parameter 2";
CM_ SG_ 812 DwnLoadDynLtgPrmForFrntLeGrp12LowBrightness "Light Show Lower Brightness Parameter 2";
CM_ SG_ 812 DwnLoadDynLtgPrmForFrntLeGrp12Mode1 "Light Show Mode Parameter 2";
CM_ SG_ 812 DwnLoadDynLtgPrmForFrntLeGrp12OffsetTime "Light Show Offset Time Parameter 2";
CM_ SG_ 812 DwnLoadDynLtgPrmForFrntLeGrp12Timestamp "Light Show time stamp 2";
CM_ SG_ 813 DwnLoadDynLtgPrmForFrntLeGrp13ContinueTime "Light Show Continue Time Parameter 2";
CM_ SG_ 813 DwnLoadDynLtgPrmForFrntLeGrp13HighBrightness "Light Show Upper Brightness Parameter 2";
CM_ SG_ 813 DwnLoadDynLtgPrmForFrntLeGrp13LowBrightness "Light Show Lower Brightness Parameter 2";
CM_ SG_ 813 DwnLoadDynLtgPrmForFrntLeGrp13Mode1 "Light Show Mode Parameter 2";
CM_ SG_ 813 DwnLoadDynLtgPrmForFrntLeGrp13OffsetTime "Light Show Offset Time Parameter 2";
CM_ SG_ 813 DwnLoadDynLtgPrmForFrntLeGrp13Timestamp "Light Show time stamp 2";
CM_ SG_ 814 DwnLoadDynLtgPrmForFrntLeGrp14ContinueTime "Light Show Continue Time Parameter 2";
CM_ SG_ 814 DwnLoadDynLtgPrmForFrntLeGrp14HighBrightness "Light Show Upper Brightness Parameter 2";
CM_ SG_ 814 DwnLoadDynLtgPrmForFrntLeGrp14LowBrightness "Light Show Lower Brightness Parameter 2";
CM_ SG_ 814 DwnLoadDynLtgPrmForFrntLeGrp14Mode1 "Light Show Mode Parameter 2";
CM_ SG_ 814 DwnLoadDynLtgPrmForFrntLeGrp14OffsetTime "Light Show Offset Time Parameter 2";
CM_ SG_ 814 DwnLoadDynLtgPrmForFrntLeGrp14Timestamp "Light Show time stamp 2";
CM_ SG_ 815 DwnLoadDynLtgPrmForFrntLeGrp15ContinueTime "Light Show Continue Time Parameter 2";
CM_ SG_ 815 DwnLoadDynLtgPrmForFrntLeGrp15HighBrightness "Light Show Upper Brightness Parameter 2";
CM_ SG_ 815 DwnLoadDynLtgPrmForFrntLeGrp15LowBrightness "Light Show Lower Brightness Parameter 2";
CM_ SG_ 815 DwnLoadDynLtgPrmForFrntLeGrp15Mode1 "Light Show Mode Parameter 2";
CM_ SG_ 815 DwnLoadDynLtgPrmForFrntLeGrp15OffsetTime "Light Show Offset Time Parameter 2";
CM_ SG_ 815 DwnLoadDynLtgPrmForFrntLeGrp15Timestamp "Light Show time stamp 2";
CM_ SG_ 816 DwnLoadDynLtgPrmForFrntLeGrp16ContinueTime "Light Show Continue Time Parameter 2";
CM_ SG_ 816 DwnLoadDynLtgPrmForFrntLeGrp16HighBrightness "Light Show Upper Brightness Parameter 2";
CM_ SG_ 816 DwnLoadDynLtgPrmForFrntLeGrp16LowBrightness "Light Show Lower Brightness Parameter 2";
CM_ SG_ 816 DwnLoadDynLtgPrmForFrntLeGrp16Mode1 "Light Show Mode Parameter 2";
CM_ SG_ 816 DwnLoadDynLtgPrmForFrntLeGrp16OffsetTime "Light Show Offset Time Parameter 2";
CM_ SG_ 816 DwnLoadDynLtgPrmForFrntLeGrp16Timestamp "Light Show time stamp 2";
CM_ SG_ 817 DwnLoadDynLtgPrmForFrntLeGrp17ContinueTime "Light Show Continue Time Parameter 2";
CM_ SG_ 817 DwnLoadDynLtgPrmForFrntLeGrp17HighBrightness "Light Show Upper Brightness Parameter 2";
CM_ SG_ 817 DwnLoadDynLtgPrmForFrntLeGrp17LowBrightness "Light Show Lower Brightness Parameter 2";
CM_ SG_ 817 DwnLoadDynLtgPrmForFrntLeGrp17Mode1 "Light Show Mode Parameter 2";
CM_ SG_ 817 DwnLoadDynLtgPrmForFrntLeGrp17OffsetTime "Light Show Offset Time Parameter 2";
CM_ SG_ 817 DwnLoadDynLtgPrmForFrntLeGrp17Timestamp "Light Show time stamp 2";
CM_ SG_ 818 DwnLoadDynLtgPrmForFrntLeGrp18ContinueTime "Light Show Continue Time Parameter 2";
CM_ SG_ 818 DwnLoadDynLtgPrmForFrntLeGrp18HighBrightness "Light Show Upper Brightness Parameter 2";
CM_ SG_ 818 DwnLoadDynLtgPrmForFrntLeGrp18LowBrightness "Light Show Lower Brightness Parameter 2";
CM_ SG_ 818 DwnLoadDynLtgPrmForFrntLeGrp18Mode1 "Light Show Mode Parameter 2";
CM_ SG_ 818 DwnLoadDynLtgPrmForFrntLeGrp18OffsetTime "Light Show Offset Time Parameter 2";
CM_ SG_ 818 DwnLoadDynLtgPrmForFrntLeGrp18Timestamp "Light Show time stamp 2";
CM_ SG_ 819 DwnLoadDynLtgPrmForFrntLeGrp19ContinueTime "Light Show Continue Time Parameter 2";
CM_ SG_ 819 DwnLoadDynLtgPrmForFrntLeGrp19HighBrightness "Light Show Upper Brightness Parameter 2";
CM_ SG_ 819 DwnLoadDynLtgPrmForFrntLeGrp19LowBrightness "Light Show Lower Brightness Parameter 2";
CM_ SG_ 819 DwnLoadDynLtgPrmForFrntLeGrp19Mode1 "Light Show Mode Parameter 2";
CM_ SG_ 819 DwnLoadDynLtgPrmForFrntLeGrp19OffsetTime "Light Show Offset Time Parameter 2";
CM_ SG_ 819 DwnLoadDynLtgPrmForFrntLeGrp19Timestamp "Light Show time stamp 2";
CM_ SG_ 820 DwnLoadDynLtgPrmForFrntLeGrp20ContinueTime "Light Show Continue Time Parameter 2";
CM_ SG_ 820 DwnLoadDynLtgPrmForFrntLeGrp20HighBrightness "Light Show Upper Brightness Parameter 2";
CM_ SG_ 820 DwnLoadDynLtgPrmForFrntLeGrp20LowBrightness "Light Show Lower Brightness Parameter 2";
CM_ SG_ 820 DwnLoadDynLtgPrmForFrntLeGrp20Mode1 "Light Show Mode Parameter 2";
CM_ SG_ 820 DwnLoadDynLtgPrmForFrntLeGrp20OffsetTime "Light Show Offset Time Parameter 2";
CM_ SG_ 820 DwnLoadDynLtgPrmForFrntLeGrp20Timestamp "Light Show time stamp 2";
CM_ SG_ 821 DwnLoadDynLtgPrmForFrntLeGrp21ContinueTime "Light Show Continue Time Parameter 2";
CM_ SG_ 821 DwnLoadDynLtgPrmForFrntLeGrp21HighBrightness "Light Show Upper Brightness Parameter 2";
CM_ SG_ 821 DwnLoadDynLtgPrmForFrntLeGrp21LowBrightness "Light Show Lower Brightness Parameter 2";
CM_ SG_ 821 DwnLoadDynLtgPrmForFrntLeGrp21Mode1 "Light Show Mode Parameter 2";
CM_ SG_ 821 DwnLoadDynLtgPrmForFrntLeGrp21OffsetTime "Light Show Offset Time Parameter 2";
CM_ SG_ 821 DwnLoadDynLtgPrmForFrntLeGrp21Timestamp "Light Show time stamp 2";
CM_ SG_ 822 DwnLoadDynLtgPrmForFrntLeGrp22ContinueTime "Light Show Continue Time Parameter 2";
CM_ SG_ 822 DwnLoadDynLtgPrmForFrntLeGrp22HighBrightness "Light Show Upper Brightness Parameter 2";
CM_ SG_ 822 DwnLoadDynLtgPrmForFrntLeGrp22LowBrightness "Light Show Lower Brightness Parameter 2";
CM_ SG_ 822 DwnLoadDynLtgPrmForFrntLeGrp22Mode1 "Light Show Mode Parameter 2";
CM_ SG_ 822 DwnLoadDynLtgPrmForFrntLeGrp22OffsetTime "Light Show Offset Time Parameter 2";
CM_ SG_ 822 DwnLoadDynLtgPrmForFrntLeGrp22Timestamp "Light Show time stamp 2";
CM_ SG_ 823 DwnLoadDynLtgPrmForFrntLeGrp23ContinueTime "Light Show Continue Time Parameter 2";
CM_ SG_ 823 DwnLoadDynLtgPrmForFrntLeGrp23HighBrightness "Light Show Upper Brightness Parameter 2";
CM_ SG_ 823 DwnLoadDynLtgPrmForFrntLeGrp23LowBrightness "Light Show Lower Brightness Parameter 2";
CM_ SG_ 823 DwnLoadDynLtgPrmForFrntLeGrp23Mode1 "Light Show Mode Parameter 2";
CM_ SG_ 823 DwnLoadDynLtgPrmForFrntLeGrp23OffsetTime "Light Show Offset Time Parameter 2";
CM_ SG_ 823 DwnLoadDynLtgPrmForFrntLeGrp23Timestamp "Light Show time stamp 2";
CM_ SG_ 824 DwnLoadDynLtgPrmForFrntLeGrp24ContinueTime "Light Show Continue Time Parameter 2";
CM_ SG_ 824 DwnLoadDynLtgPrmForFrntLeGrp24HighBrightness "Light Show Upper Brightness Parameter 2";
CM_ SG_ 824 DwnLoadDynLtgPrmForFrntLeGrp24LowBrightness "Light Show Lower Brightness Parameter 2";
CM_ SG_ 824 DwnLoadDynLtgPrmForFrntLeGrp24Mode1 "Light Show Mode Parameter 2";
CM_ SG_ 824 DwnLoadDynLtgPrmForFrntLeGrp24OffsetTime "Light Show Offset Time Parameter 2";
CM_ SG_ 824 DwnLoadDynLtgPrmForFrntLeGrp24Timestamp "Light Show time stamp 2";
CM_ SG_ 825 DwnLoadDynLtgPrmForFrntRIGrp1ContinueTime "Light Show Continue Time Parameter 2";
CM_ SG_ 825 DwnLoadDynLtgPrmForFrntRIGrp1HighBrightness "Light Show Upper Brightness Parameter 2";
CM_ SG_ 825 DwnLoadDynLtgPrmForFrntRIGrp1LowBrightness "Light Show Lower Brightness Parameter 2";
CM_ SG_ 825 DwnLoadDynLtgPrmForFrntRIGrp1Mode1 "Light Show Mode Parameter 2";
CM_ SG_ 825 DwnLoadDynLtgPrmForFrntRIGrp1OffsetTime "Light Show Offset Time Parameter 2";
CM_ SG_ 825 DwnLoadDynLtgPrmForFrntRIGrp1Timestamp "Light Show time stamp 2";
CM_ SG_ 826 DwnLoadDynLtgPrmForFrntRIGrp2ContinueTime "Light Show Continue Time Parameter 2";
CM_ SG_ 826 DwnLoadDynLtgPrmForFrntRIGrp2HighBrightness "Light Show Upper Brightness Parameter 2";
CM_ SG_ 826 DwnLoadDynLtgPrmForFrntRIGrp2LowBrightness "Light Show Lower Brightness Parameter 2";
CM_ SG_ 826 DwnLoadDynLtgPrmForFrntRIGrp2Mode1 "Light Show Mode Parameter 2";
CM_ SG_ 826 DwnLoadDynLtgPrmForFrntRIGrp2OffsetTime "Light Show Offset Time Parameter 2";
CM_ SG_ 826 DwnLoadDynLtgPrmForFrntRIGrp2Timestamp "Light Show time stamp 2";
CM_ SG_ 827 DwnLoadDynLtgPrmForFrntRIGrp3ContinueTime "Light Show Continue Time Parameter 2";
CM_ SG_ 827 DwnLoadDynLtgPrmForFrntRIGrp3HighBrightness "Light Show Upper Brightness Parameter 2";
CM_ SG_ 827 DwnLoadDynLtgPrmForFrntRIGrp3LowBrightness "Light Show Lower Brightness Parameter 2";
CM_ SG_ 827 DwnLoadDynLtgPrmForFrntRIGrp3Mode1 "Light Show Mode Parameter 2";
CM_ SG_ 827 DwnLoadDynLtgPrmForFrntRIGrp3OffsetTime "Light Show Offset Time Parameter 2";
CM_ SG_ 827 DwnLoadDynLtgPrmForFrntRIGrp3Timestamp "Light Show time stamp 2";
CM_ SG_ 828 DwnLoadDynLtgPrmForFrntRIGrp4ContinueTime "Light Show Continue Time Parameter 2";
CM_ SG_ 828 DwnLoadDynLtgPrmForFrntRIGrp4HighBrightness "Light Show Upper Brightness Parameter 2";
CM_ SG_ 828 DwnLoadDynLtgPrmForFrntRIGrp4LowBrightness "Light Show Lower Brightness Parameter 2";
CM_ SG_ 828 DwnLoadDynLtgPrmForFrntRIGrp4Mode1 "Light Show Mode Parameter 2";
CM_ SG_ 828 DwnLoadDynLtgPrmForFrntRIGrp4OffsetTime "Light Show Offset Time Parameter 2";
CM_ SG_ 828 DwnLoadDynLtgPrmForFrntRIGrp4Timestamp "Light Show time stamp 2";
CM_ SG_ 829 DwnLoadDynLtgPrmForFrntRIGrp5ContinueTime "Light Show Continue Time Parameter 2";
CM_ SG_ 829 DwnLoadDynLtgPrmForFrntRIGrp5HighBrightness "Light Show Upper Brightness Parameter 2";
CM_ SG_ 829 DwnLoadDynLtgPrmForFrntRIGrp5LowBrightness "Light Show Lower Brightness Parameter 2";
CM_ SG_ 829 DwnLoadDynLtgPrmForFrntRIGrp5Mode1 "Light Show Mode Parameter 2";
CM_ SG_ 829 DwnLoadDynLtgPrmForFrntRIGrp5OffsetTime "Light Show Offset Time Parameter 2";
CM_ SG_ 829 DwnLoadDynLtgPrmForFrntRIGrp5Timestamp "Light Show time stamp 2";
CM_ SG_ 830 DwnLoadDynLtgPrmForFrntRIGrp6ContinueTime "Light Show Continue Time Parameter 2";
CM_ SG_ 830 DwnLoadDynLtgPrmForFrntRIGrp6HighBrightness "Light Show Upper Brightness Parameter 2";
CM_ SG_ 830 DwnLoadDynLtgPrmForFrntRIGrp6LowBrightness "Light Show Lower Brightness Parameter 2";
CM_ SG_ 830 DwnLoadDynLtgPrmForFrntRIGrp6Mode1 "Light Show Mode Parameter 2";
CM_ SG_ 830 DwnLoadDynLtgPrmForFrntRIGrp6OffsetTime "Light Show Offset Time Parameter 2";
CM_ SG_ 830 DwnLoadDynLtgPrmForFrntRIGrp6Timestamp "Light Show time stamp 2";
CM_ SG_ 831 DwnLoadDynLtgPrmForFrntRIGrp7ContinueTime "Light Show Continue Time Parameter 2";
CM_ SG_ 831 DwnLoadDynLtgPrmForFrntRIGrp7HighBrightness "Light Show Upper Brightness Parameter 2";
CM_ SG_ 831 DwnLoadDynLtgPrmForFrntRIGrp7LowBrightness "Light Show Lower Brightness Parameter 2";
CM_ SG_ 831 DwnLoadDynLtgPrmForFrntRIGrp7Mode1 "Light Show Mode Parameter 2";
CM_ SG_ 831 DwnLoadDynLtgPrmForFrntRIGrp7OffsetTime "Light Show Offset Time Parameter 2";
CM_ SG_ 831 DwnLoadDynLtgPrmForFrntRIGrp7Timestamp "Light Show time stamp 2";
CM_ SG_ 832 DwnLoadDynLtgPrmForFrntRIGrp8ContinueTime "Light Show Continue Time Parameter 2";
CM_ SG_ 832 DwnLoadDynLtgPrmForFrntRIGrp8HighBrightness "Light Show Upper Brightness Parameter 2";
CM_ SG_ 832 DwnLoadDynLtgPrmForFrntRIGrp8LowBrightness "Light Show Lower Brightness Parameter 2";
CM_ SG_ 832 DwnLoadDynLtgPrmForFrntRIGrp8Mode1 "Light Show Mode Parameter 2";
CM_ SG_ 832 DwnLoadDynLtgPrmForFrntRIGrp8OffsetTime "Light Show Offset Time Parameter 2";
CM_ SG_ 832 DwnLoadDynLtgPrmForFrntRIGrp8Timestamp "Light Show time stamp 2";
CM_ SG_ 833 DwnLoadDynLtgPrmForFrntRIGrp9ContinueTime "Light Show Continue Time Parameter 2";
CM_ SG_ 833 DwnLoadDynLtgPrmForFrntRIGrp9HighBrightness "Light Show Upper Brightness Parameter 2";
CM_ SG_ 833 DwnLoadDynLtgPrmForFrntRIGrp9LowBrightness "Light Show Lower Brightness Parameter 2";
CM_ SG_ 833 DwnLoadDynLtgPrmForFrntRIGrp9Mode1 "Light Show Mode Parameter 2";
CM_ SG_ 833 DwnLoadDynLtgPrmForFrntRIGrp9OffsetTime "Light Show Offset Time Parameter 2";
CM_ SG_ 833 DwnLoadDynLtgPrmForFrntRIGrp9Timestamp "Light Show time stamp 2";
CM_ SG_ 1425 CEMdevelpsignalgroupreqFunctiondevpsignalgroup1 "develop signal group request";
CM_ SG_ 1425 CEMdevelpsignalgroupreqFunctiondevpsignalgroup2 "develop signal group request";
CM_ SG_ 1425 CEMdevelpsignalgroupreqFunctiondevpsignalgroup3 "develop signal group request";
CM_ SG_ 1425 CEMdevelpsignalgroupreqFunctiondevpsignalgroup4 "develop signal group request";
CM_ SG_ 1425 CEMdevelpsignalgroupreqFunctiondevpsignalgroup5 "develop signal group request";
CM_ SG_ 1425 CEMdevelpsignalgroupreqFunctiondevpsignalgroup6 "develop signal group request";
CM_ SG_ 1425 CEMdevelpsignalgroupreqFunctiondevpsignalgroup7 "develop signal group request";
CM_ SG_ 1425 CEMdevelpsignalgroupreqFunctiondevpsignalgroup8 "develop signal group request";
CM_ SG_ 593 ExtrLiShowStoreStsFrntLe "ExtrLiShowStoreStsFrntLe";
CM_ SG_ 593 StsOfLedHiBeamLe "Status of Led High Beam Left.";
CM_ SG_ 593 StsOfLedLeLogoLamp "Status of Led Left Logo Light Lamp";
CM_ SG_ 593 StsOfLedLoBeamLe "Status of Led Low Beam Left.";
CM_ SG_ 124 DwnLoadStsFbOfHdlampLe "Download of Dynamic light sequence Feedback signal.";
CM_ SG_ 124 DwnLoadStsFbOfLogoLampLe "Download status feedback of Left Logo Light lamp.";
CM_ SG_ 124 ExtrLiShowActvnFrntLeFb "Activation of Exterior Light Show Feedback Frong Left Head Lamp";
CM_ SG_ 124 ExtrLiShowActvnLeLogoFb "Activation of Exterior Light Show Feedback from Left Logo Light Lamp";
CM_ SG_ 124 HdlampLeInpSts1 "Ext. Light relay input driver warning and fault tracing";
CM_ SG_ 124 HdlampLeInpSts2 "Ignition relay input driver warning and fault tracing";
CM_ SG_ 124 StsOfAfsLe "Status of AFS light distribution Left.";
CM_ SG_ 124 StsOfAhbcLe "Status of Auto High Beam Control Left.";
CM_ SG_ 124 StsOfFrntSideMkrLampLe2 "Status of Front Side Marker Lamp Left 2.";
CM_ SG_ 124 StsOfLedCornrgLampLe "Status of Led Cornering Lamp Left.";
CM_ SG_ 124 StsOfLedDaytiRunngLampLe "Status of Led Day Time Running Lamp Left.";
CM_ SG_ 124 StsOfLedFrntFogLampLe "Status of Led Front Fog Light Left.";
CM_ SG_ 124 StsOfLedFrntPosnLampLe "Status of Led Front Position Lamp Left.";
CM_ SG_ 124 StsOfLedFrntTurnIndcrLe "Status of Led Front Turn Indicator Left.";
CM_ SG_ 124 StsOfLvlgLeChks "Status of Head Lamp Leveling Motor Check Sum";
CM_ SG_ 124 StsOfLvlgLeCntr "Status of Head Lamp Leveling Motor Counter";
CM_ SG_ 124 StsOfLvlgLeStsOfLvlgLe "Status of Head Lamp Leveling Motor";
CM_ SG_ 124 StsOfSwvlgLe "Status of Bending Light Left.";
CM_ SG_ 124 StsOfTouristModLe "Status of Tourist Mode Left.";
CM_ SG_ 124 StsOfWelGbyFrntLe "status of welcome and goodbye light from HCML";
CM_ SG_ 594 ExtrLiShowStoreStsFrntRi "ExtrLiShowStoreStsFrntRi";
CM_ SG_ 594 StsOfLedHiBeamRi "Status of High Beam Led Right.";
CM_ SG_ 594 StsOfLedLoBeamRi "Status of Low Beam Led Right";
CM_ SG_ 594 StsOfLedRiLogoLamp "Status of Led Right Logo Light Lamp";
CM_ SG_ 127 DwnLoadStsFbOfHdlampRi "Download of Dynamic light sequence Feedback signal.";
CM_ SG_ 127 DwnLoadStsFbOfLogoLampRi "Download status feedback of Right Logo Light lamp.";
CM_ SG_ 127 ExtrLiShowActvnFrntRiFb "Activation of Exterior Light Show Feedback Frong Right Head Lamp";
CM_ SG_ 127 ExtrLiShowActvnRiLogoFb "Activation of Exterior Light Show Feedback from Right Logo Light Lamp";
CM_ SG_ 127 HdlampRiInpSts1 "Ext. Light relay input driver warning and fault tracing";
CM_ SG_ 127 HdlampRiInpSts2 "Ignition relay input driver warning and fault tracing";
CM_ SG_ 127 StsOfAfsRi "Status of AFS light distribution Right.";
CM_ SG_ 127 StsOfAhbcRi "Status of Auto High Beam Control Right.";
CM_ SG_ 127 StsOfFrntSideMkrLampRi2 "Status of Front Side Marker Lamp Right 2.";
CM_ SG_ 127 StsOfLedCornrgLampRi "Status of Led Cornering Lamp Right.";
CM_ SG_ 127 StsOfLedDaytiRunngLampRi "Status of Led Day Time Running Lamp Right.";
CM_ SG_ 127 StsOfLedFrntFogLampRi "Status of Led Front Fog Lamp Right.";
CM_ SG_ 127 StsOfLedFrntPosnLampRi "Status of Led Front Position Lamp Right.";
CM_ SG_ 127 StsOfLedFrntTurnIndcrRi "Status of Front Turn Right Indicator";
CM_ SG_ 127 StsOfLvlgRiChks "Status of Head Lamp Leveling Motor Check Sum";
CM_ SG_ 127 StsOfLvlgRiCntr "Status of Head Lamp Leveling Motor Counter";
CM_ SG_ 127 StsOfLvlgRiStsOfLvlgRi "Status of Head Lamp Leveling Motor";
CM_ SG_ 127 StsOfSwvlgRi "Status of Bending Light Right.";
CM_ SG_ 127 StsOfTouristModRi "Status of Tourist Mode Right.";
CM_ SG_ 127 StsOfWelGbyFrntRi "status of welcome and goodbye light from HCMR";
CM_ SG_ 592 DwnLoadStsFbOfReLampCtrlLe1 "Download Status Feedback of Rear Lamp Control Left 1";
CM_ SG_ 592 ExtrLiShowActvnReLeFb "Activation Exterior Light Show Feedback";
CM_ SG_ 592 ExtrLiShowStoreStsReLe1 "ExtrLiShowStoreStsReLe1";
CM_ SG_ 592 StsOfLedPosnLampLe1 "Status of Led Position Lamp Left 1. ";
CM_ SG_ 592 StsOfLedReFogLampLe1 "Status of Led Rear Fog Lampp Left 1.";
CM_ SG_ 592 StsOfLedReLampLe1 "Status Of LED Rear Lamp Left 1.";
CM_ SG_ 592 StsOfLedRvsgLampLe1 "Status of Led Reversing Lamp left 1.";
CM_ SG_ 592 StsOfLedStopLampLe1 "Status of Led Stop Lamp Left 1.";
CM_ SG_ 592 StsOfLedTurnIndcrLe1 "Status of Led Turn Indicator Left 1.";
CM_ SG_ 592 StsOfWelGbyReLe1 "status of welcome and goodbye light from RCML";
CM_ SG_ 596 DwnLoadStsFbOfReLampCtrlLe2 "Download status feedback of Rearlamp Left 2.";
CM_ SG_ 596 DwnLoadStsFbOfReLampCtrlRi2 "Download Status Feedback of Rear Lamp Control Right 2";
CM_ SG_ 596 ExtrLiShowActvnReLe2Fb "Activation of Exterior Light Show Feedback Rear Lamp Left 2.";
CM_ SG_ 596 ExtrLiShowActvnReRi2Fb "Activation of Exterior Light Show Feedback Rear Lamp Right 2.";
CM_ SG_ 596 ExtrLiShowStoreStsReLe2 "ExtrLiShowStoreStsReLe2";
CM_ SG_ 596 ExtrLiShowStoreStsReRi2 "ExtrLiShowStoreStsReRi2";
CM_ SG_ 596 StsOfLedPosnLampLe2 "Status of Led Position Lamp Left 2.";
CM_ SG_ 596 StsOfLedPosnLampRi2 "Status of Led Position Lamp Right 2.";
CM_ SG_ 596 StsOfLedReFogLampLe2 "Status of Led Rear Fog Lamp Left 2.";
CM_ SG_ 596 StsOfLedReFogLampRi2 "Status of Led Rear Fog Lamp Right 2.";
CM_ SG_ 596 StsOfLedReLampLe2 "Status Of LED Rear Lamp Left 2.";
CM_ SG_ 596 StsOfLedReLampRi2 "Status Of LED Rear Lamp Right 2.";
CM_ SG_ 596 StsOfLedRvsgLampLe2 "Status of Led Reversing Lamp Left 2.";
CM_ SG_ 596 StsOfLedRvsgLampRi2 "Status of Led Reversing Lamp Right 2.";
CM_ SG_ 596 StsOfLedStopLampLe2 "Status of Led Stop Lamp Left 2.";
CM_ SG_ 596 StsOfLedStopLampRi2 "Status of Led Stop Lamp Right 2.";
CM_ SG_ 596 StsOfLedTurnIndcrLe2 "Status of Led Turn Indicator Left 2.";
CM_ SG_ 596 StsOfLedTurnIndcrRi2 "Status of Led Turn Indicator Right 2.";
CM_ SG_ 596 StsOfWelGbyReLe2 "status of welcome and goodbye light from RCMM";
CM_ SG_ 596 StsOfWelGbyReRi2 "status of welcome and goodbye light from RCMM";
CM_ SG_ 608 DwnLoadStsFbOfReLampCtrlRi1 "Download Status Feedback of Rear Lamp Control Right 1";
CM_ SG_ 608 ExtrLiShowActvnReRiFb "Activation Exterior Light Show Feedback";
CM_ SG_ 608 ExtrLiShowStoreStsReRi1 "ExtrLiShowStoreStsReRi1";
CM_ SG_ 608 StsOfLedPosnLampRi1 "Status of Led Position Lamp Right 1. ";
CM_ SG_ 608 StsOfLedReFogLampRi1 "Status of Led Rear Fog Lamp Right. ";
CM_ SG_ 608 StsOfLedReLampRi1 "Status Of LED Rear Lamp Right 1.";
CM_ SG_ 608 StsOfLedRvsgLampRi1 "Status of Led Reversing Lamp 1.";
CM_ SG_ 608 StsOfLedStopLampRi1 "Status of Led Stop Lamp Right 1. ";
CM_ SG_ 608 StsOfLedTurnIndcrRi1 "Status of Led Turn Indicator Right 1.";
CM_ SG_ 608 StsOfWelGbyReRi1 "status of welcome and goodbye light from RCMR";
BA_DEF_ BO_ "GenMsgSendType" ENUM "cyclic", "spontaneous", "not-used", "not-used", "not-used", "cyclicAndSpontaneous", "not-used", "cyclicIfActive", "NoMsgSendType"; // [us]
BA_DEF_ BO_ "GenMsgCycleTime" INT 0 65536; // [ms]
BA_DEF_ BO_ "GenMsgStartDelayTime" INT 0 65536; // [ms]
BA_DEF_ BO_ "GenMsgDelayTime" INT 0 65536; // [ms]
BA_DEF_ SG_ "GenSigSendType" ENUM "Cyclic","OnWrite","OnWriteWithRepetition","OnChange","OnChangeWithRepetition","IfActive","IfActiveWithRepetition","NoSigSendType";
BA_DEF_ SG_ "GenSigStartValue" HEX 0 80000000;
BA_DEF_ BO_ "GenMsgILSupport" ENUM "No","Yes";
BA_DEF_ BO_ "NmAsrMessage" ENUM "No","Yes";
BA_DEF_ SG_ "GenSigFuncType" ENUM "NoFunction","n/a","n/a","n/a","n/a","n/a","n/a","n/a","n/a","n/a","n/a","n/a","n/a","n/a","n/a","CHK","CNTR","n/a","n/a","n/a","CNTR_AR_01","CRC_AR_01_BOTH","CRC_AR_01_ALT","CRC_AR_01_LOW","CRC_AR_01_NIBBLE","CNTR_AR_04","CRC_AR_04A","CNTR_AR_05","CRC_AR_05";
BA_DEF_ SG_ "GenSigDataID" STRING;
BA_DEF_ SG_ "SigGroup" STRING;

BA_DEF_DEF_ "GenSigStartValue" 0;
BA_DEF_DEF_ "GenSigSendType" "NoSigSendType";
BA_DEF_DEF_ "GenMsgCycleTime" 0;
BA_DEF_DEF_ "GenMsgDelayTime" 0;
BA_DEF_DEF_ "GenMsgStartDelayTime" 0;
BA_DEF_DEF_ "GenMsgSendType" "NoMsgSendType";
BA_DEF_DEF_ "GenMsgILSupport" "Yes";
BA_DEF_DEF_ "NmAsrMessage" "No";
BA_DEF_DEF_ "GenSigFuncType" "NoFunction";
BA_DEF_DEF_ "GenSigDataID" "";
BA_DEF_DEF_ "SigGroup" "";
// Frame: CemBodyExpoFr63
BA_ "GenMsgSendType" BO_ 789 1;
BA_ "GenMsgDelayTime" BO_ 789 150.000;
BA_ "GenSigSendType" SG_ 789 DHUcontrolCrossreversinglight 1;
BA_ "GenSigSendType" SG_ 789 DHUcontrolleftbrakelightLamp 1;
BA_ "GenSigSendType" SG_ 789 DHUcontrolleftpositionlight 1;
BA_ "GenSigSendType" SG_ 789 DHUcontrolrightbrakelight 1;
// Frame: CemBodyExpoFr64
BA_ "GenMsgSendType" BO_ 335 1;
BA_ "GenMsgDelayTime" BO_ 335 30.000;
BA_ "GenSigSendType" SG_ 335 DwnLoadDynLitPrmLedFrntMidPosnLiContTiPrm 1;
BA_ "SigGroup" SG_ 335 DwnLoadDynLitPrmLedFrntMidPosnLiContTiPrm "DwnLoadDynLitPrmLedFrntMidPosnLi";
BA_ "GenSigSendType" SG_ 335 DwnLoadDynLitPrmLedFrntMidPosnLiLowBriPrm 1;
BA_ "SigGroup" SG_ 335 DwnLoadDynLitPrmLedFrntMidPosnLiLowBriPrm "DwnLoadDynLitPrmLedFrntMidPosnLi";
BA_ "GenSigSendType" SG_ 335 DwnLoadDynLitPrmLedFrntMidPosnLiModePrm 1;
BA_ "SigGroup" SG_ 335 DwnLoadDynLitPrmLedFrntMidPosnLiModePrm "DwnLoadDynLitPrmLedFrntMidPosnLi";
BA_ "GenSigSendType" SG_ 335 DwnLoadDynLitPrmLedFrntMidPosnLiOffsTiPrm 1;
BA_ "SigGroup" SG_ 335 DwnLoadDynLitPrmLedFrntMidPosnLiOffsTiPrm "DwnLoadDynLitPrmLedFrntMidPosnLi";
BA_ "GenSigSendType" SG_ 335 DwnLoadDynLitPrmLedFrntMidPosnLiTistamp 1;
BA_ "SigGroup" SG_ 335 DwnLoadDynLitPrmLedFrntMidPosnLiTistamp "DwnLoadDynLitPrmLedFrntMidPosnLi";
BA_ "GenSigSendType" SG_ 335 DwnLoadDynLitPrmLedFrntMidPosnLiUpprBriPrm 1;
BA_ "SigGroup" SG_ 335 DwnLoadDynLitPrmLedFrntMidPosnLiUpprBriPrm "DwnLoadDynLitPrmLedFrntMidPosnLi";
// Frame: CemBodyExpoFr65
BA_ "GenMsgSendType" BO_ 336 1;
BA_ "GenMsgDelayTime" BO_ 336 30.000;
BA_ "GenSigSendType" SG_ 336 DwnLoadDynLitPrmLedLeSideLogoLiContTiPrm 1;
BA_ "GenSigSendType" SG_ 336 DwnLoadDynLitPrmLedLeSideLogoLiLowBriPrm 1;
BA_ "GenSigSendType" SG_ 336 DwnLoadDynLitPrmLedLeSideLogoLiModePrm 1;
BA_ "GenSigSendType" SG_ 336 DwnLoadDynLitPrmLedLeSideLogoLiOffsTiPrm 1;
BA_ "GenSigSendType" SG_ 336 DwnLoadDynLitPrmLedLeSideLogoLiTistamp 1;
BA_ "GenSigSendType" SG_ 336 DwnLoadDynLitPrmLedLeSideLogoLiUpprBriPrm 1;
// Frame: CemBodyExpoFr66
BA_ "GenMsgSendType" BO_ 337 1;
BA_ "GenMsgDelayTime" BO_ 337 30.000;
BA_ "GenSigSendType" SG_ 337 DwnLoadDynLitPrmLedRiSideLogoLiContTiPrm 1;
BA_ "GenSigSendType" SG_ 337 DwnLoadDynLitPrmLedRiSideLogoLiLowBriPrm 1;
BA_ "GenSigSendType" SG_ 337 DwnLoadDynLitPrmLedRiSideLogoLiModePrm 1;
BA_ "GenSigSendType" SG_ 337 DwnLoadDynLitPrmLedRiSideLogoLiOffsTiPrm 1;
BA_ "GenSigSendType" SG_ 337 DwnLoadDynLitPrmLedRiSideLogoLiTistamp 1;
BA_ "GenSigSendType" SG_ 337 DwnLoadDynLitPrmLedRiSideLogoLiUpprBriPrm 1;
// Frame: CemBodyExpoFr67
BA_ "GenMsgSendType" BO_ 801 1;
BA_ "GenMsgDelayTime" BO_ 801 35.000;
BA_ "GenSigSendType" SG_ 801 DHUcontrolLedLogoLamp 1;
BA_ "GenSigSendType" SG_ 801 DwnLoadDynLtgPrmForFrntLeGrp1ContinueTime 1;
BA_ "GenSigSendType" SG_ 801 DwnLoadDynLtgPrmForFrntLeGrp1HighBrightness 1;
BA_ "GenSigSendType" SG_ 801 DwnLoadDynLtgPrmForFrntLeGrp1LowBrightness 1;
BA_ "GenSigSendType" SG_ 801 DwnLoadDynLtgPrmForFrntLeGrp1Mode1 1;
BA_ "GenSigSendType" SG_ 801 DwnLoadDynLtgPrmForFrntLeGrp1OffsetTime 1;
BA_ "GenSigSendType" SG_ 801 DwnLoadDynLtgPrmForFrntLeGrp1Timestamp 1;
BA_ "GenSigSendType" SG_ 801 WelLiFileTxReq 1;
// Frame: CemBodyExpoFr68
BA_ "GenMsgSendType" BO_ 802 1;
BA_ "GenMsgDelayTime" BO_ 802 35.000;
BA_ "GenSigSendType" SG_ 802 DwnLoadDynLtgPrmForFrntLeGrp2ContinueTime 1;
BA_ "GenSigSendType" SG_ 802 DwnLoadDynLtgPrmForFrntLeGrp2HighBrightness 1;
BA_ "GenSigSendType" SG_ 802 DwnLoadDynLtgPrmForFrntLeGrp2LowBrightness 1;
BA_ "GenSigSendType" SG_ 802 DwnLoadDynLtgPrmForFrntLeGrp2Mode1 1;
BA_ "GenSigSendType" SG_ 802 DwnLoadDynLtgPrmForFrntLeGrp2OffsetTime 1;
BA_ "GenSigSendType" SG_ 802 DwnLoadDynLtgPrmForFrntLeGrp2Timestamp 1;
// Frame: CemBodyExpoFr69
BA_ "GenMsgSendType" BO_ 803 1;
BA_ "GenMsgDelayTime" BO_ 803 35.000;
BA_ "GenSigSendType" SG_ 803 DwnLoadDynLtgPrmForFrntLeGrp3ContinueTime 1;
BA_ "GenSigSendType" SG_ 803 DwnLoadDynLtgPrmForFrntLeGrp3HighBrightness 1;
BA_ "GenSigSendType" SG_ 803 DwnLoadDynLtgPrmForFrntLeGrp3LowBrightness 1;
BA_ "GenSigSendType" SG_ 803 DwnLoadDynLtgPrmForFrntLeGrp3Mode1 1;
BA_ "GenSigSendType" SG_ 803 DwnLoadDynLtgPrmForFrntLeGrp3OffsetTime 1;
BA_ "GenSigSendType" SG_ 803 DwnLoadDynLtgPrmForFrntLeGrp3Timestamp 1;
// Frame: CemBodyExpoFr70
BA_ "GenMsgSendType" BO_ 804 1;
BA_ "GenMsgDelayTime" BO_ 804 35.000;
BA_ "GenSigSendType" SG_ 804 DwnLoadDynLtgPrmForFrntLeGrp4ContinueTime 1;
BA_ "GenSigSendType" SG_ 804 DwnLoadDynLtgPrmForFrntLeGrp4HighBrightness 1;
BA_ "GenSigSendType" SG_ 804 DwnLoadDynLtgPrmForFrntLeGrp4LowBrightness 1;
BA_ "GenSigSendType" SG_ 804 DwnLoadDynLtgPrmForFrntLeGrp4Mode1 1;
BA_ "GenSigSendType" SG_ 804 DwnLoadDynLtgPrmForFrntLeGrp4OffsetTime 1;
BA_ "GenSigSendType" SG_ 804 DwnLoadDynLtgPrmForFrntLeGrp4Timestamp 1;
// Frame: CemBodyExpoFr71
BA_ "GenMsgSendType" BO_ 805 1;
BA_ "GenMsgDelayTime" BO_ 805 35.000;
BA_ "GenSigSendType" SG_ 805 DwnLoadDynLtgPrmForFrntLeGrp5ContinueTime 1;
BA_ "GenSigSendType" SG_ 805 DwnLoadDynLtgPrmForFrntLeGrp5HighBrightness 1;
BA_ "GenSigSendType" SG_ 805 DwnLoadDynLtgPrmForFrntLeGrp5LowBrightness 1;
BA_ "GenSigSendType" SG_ 805 DwnLoadDynLtgPrmForFrntLeGrp5Mode1 1;
BA_ "GenSigSendType" SG_ 805 DwnLoadDynLtgPrmForFrntLeGrp5OffsetTime 1;
BA_ "GenSigSendType" SG_ 805 DwnLoadDynLtgPrmForFrntLeGrp5Timestamp 1;
// Frame: CemBodyExpoFr72
BA_ "GenMsgSendType" BO_ 806 1;
BA_ "GenMsgDelayTime" BO_ 806 35.000;
BA_ "GenSigSendType" SG_ 806 DwnLoadDynLtgPrmForFrntLeGrp6ContinueTime 1;
BA_ "GenSigSendType" SG_ 806 DwnLoadDynLtgPrmForFrntLeGrp6HighBrightness 1;
BA_ "GenSigSendType" SG_ 806 DwnLoadDynLtgPrmForFrntLeGrp6LowBrightness 1;
BA_ "GenSigSendType" SG_ 806 DwnLoadDynLtgPrmForFrntLeGrp6Mode1 1;
BA_ "GenSigSendType" SG_ 806 DwnLoadDynLtgPrmForFrntLeGrp6OffsetTime 1;
BA_ "GenSigSendType" SG_ 806 DwnLoadDynLtgPrmForFrntLeGrp6Timestamp 1;
// Frame: CemBodyExpoFr73
BA_ "GenMsgSendType" BO_ 807 1;
BA_ "GenMsgDelayTime" BO_ 807 35.000;
BA_ "GenSigSendType" SG_ 807 DwnLoadDynLtgPrmForFrntLeGrp7ContinueTime 1;
BA_ "GenSigSendType" SG_ 807 DwnLoadDynLtgPrmForFrntLeGrp7HighBrightness 1;
BA_ "GenSigSendType" SG_ 807 DwnLoadDynLtgPrmForFrntLeGrp7LowBrightness 1;
BA_ "GenSigSendType" SG_ 807 DwnLoadDynLtgPrmForFrntLeGrp7Mode1 1;
BA_ "GenSigSendType" SG_ 807 DwnLoadDynLtgPrmForFrntLeGrp7OffsetTime 1;
BA_ "GenSigSendType" SG_ 807 DwnLoadDynLtgPrmForFrntLeGrp7Timestamp 1;
// Frame: CemBodyExpoFr74
BA_ "GenMsgSendType" BO_ 808 1;
BA_ "GenMsgDelayTime" BO_ 808 35.000;
BA_ "GenSigSendType" SG_ 808 DwnLoadDynLtgPrmForFrntLeGrp8ContinueTime 1;
BA_ "GenSigSendType" SG_ 808 DwnLoadDynLtgPrmForFrntLeGrp8HighBrightness 1;
BA_ "GenSigSendType" SG_ 808 DwnLoadDynLtgPrmForFrntLeGrp8LowBrightness 1;
BA_ "GenSigSendType" SG_ 808 DwnLoadDynLtgPrmForFrntLeGrp8Mode1 1;
BA_ "GenSigSendType" SG_ 808 DwnLoadDynLtgPrmForFrntLeGrp8OffsetTime 1;
BA_ "GenSigSendType" SG_ 808 DwnLoadDynLtgPrmForFrntLeGrp8Timestamp 1;
// Frame: CemBodyExpoFr75
BA_ "GenMsgSendType" BO_ 809 1;
BA_ "GenMsgDelayTime" BO_ 809 35.000;
BA_ "GenSigSendType" SG_ 809 DwnLoadDynLtgPrmForFrntLeGrp9ContinueTime 1;
BA_ "GenSigSendType" SG_ 809 DwnLoadDynLtgPrmForFrntLeGrp9HighBrightness 1;
BA_ "GenSigSendType" SG_ 809 DwnLoadDynLtgPrmForFrntLeGrp9LowBrightness 1;
BA_ "GenSigSendType" SG_ 809 DwnLoadDynLtgPrmForFrntLeGrp9Mode1 1;
BA_ "GenSigSendType" SG_ 809 DwnLoadDynLtgPrmForFrntLeGrp9OffsetTime 1;
BA_ "GenSigSendType" SG_ 809 DwnLoadDynLtgPrmForFrntLeGrp9Timestamp 1;
// Frame: CemBodyExpoFr76
BA_ "GenMsgSendType" BO_ 810 1;
BA_ "GenMsgDelayTime" BO_ 810 35.000;
BA_ "GenSigSendType" SG_ 810 DwnLoadDynLtgPrmForFrntLeGrp10ContinueTime 1;
BA_ "GenSigSendType" SG_ 810 DwnLoadDynLtgPrmForFrntLeGrp10HighBrightness 1;
BA_ "GenSigSendType" SG_ 810 DwnLoadDynLtgPrmForFrntLeGrp10LowBrightness 1;
BA_ "GenSigSendType" SG_ 810 DwnLoadDynLtgPrmForFrntLeGrp10Mode1 1;
BA_ "GenSigSendType" SG_ 810 DwnLoadDynLtgPrmForFrntLeGrp10OffsetTime 1;
BA_ "GenSigSendType" SG_ 810 DwnLoadDynLtgPrmForFrntLeGrp10Timestamp 1;
// Frame: CemBodyExpoFr77
BA_ "GenMsgSendType" BO_ 811 1;
BA_ "GenMsgDelayTime" BO_ 811 35.000;
BA_ "GenSigSendType" SG_ 811 DwnLoadDynLtgPrmForFrntLeGrp11ContinueTime 1;
BA_ "GenSigSendType" SG_ 811 DwnLoadDynLtgPrmForFrntLeGrp11HighBrightness 1;
BA_ "GenSigSendType" SG_ 811 DwnLoadDynLtgPrmForFrntLeGrp11LowBrightness 1;
BA_ "GenSigSendType" SG_ 811 DwnLoadDynLtgPrmForFrntLeGrp11Mode1 1;
BA_ "GenSigSendType" SG_ 811 DwnLoadDynLtgPrmForFrntLeGrp11OffsetTime 1;
BA_ "GenSigSendType" SG_ 811 DwnLoadDynLtgPrmForFrntLeGrp11Timestamp 1;
// Frame: CemBodyExpoFr78
BA_ "GenMsgSendType" BO_ 812 1;
BA_ "GenMsgDelayTime" BO_ 812 35.000;
BA_ "GenSigSendType" SG_ 812 DwnLoadDynLtgPrmForFrntLeGrp12ContinueTime 1;
BA_ "GenSigSendType" SG_ 812 DwnLoadDynLtgPrmForFrntLeGrp12HighBrightness 1;
BA_ "GenSigSendType" SG_ 812 DwnLoadDynLtgPrmForFrntLeGrp12LowBrightness 1;
BA_ "GenSigSendType" SG_ 812 DwnLoadDynLtgPrmForFrntLeGrp12Mode1 1;
BA_ "GenSigSendType" SG_ 812 DwnLoadDynLtgPrmForFrntLeGrp12OffsetTime 1;
BA_ "GenSigSendType" SG_ 812 DwnLoadDynLtgPrmForFrntLeGrp12Timestamp 1;
// Frame: CemBodyExpoFr79
BA_ "GenMsgSendType" BO_ 813 1;
BA_ "GenMsgDelayTime" BO_ 813 35.000;
BA_ "GenSigSendType" SG_ 813 DwnLoadDynLtgPrmForFrntLeGrp13ContinueTime 1;
BA_ "GenSigSendType" SG_ 813 DwnLoadDynLtgPrmForFrntLeGrp13HighBrightness 1;
BA_ "GenSigSendType" SG_ 813 DwnLoadDynLtgPrmForFrntLeGrp13LowBrightness 1;
BA_ "GenSigSendType" SG_ 813 DwnLoadDynLtgPrmForFrntLeGrp13Mode1 1;
BA_ "GenSigSendType" SG_ 813 DwnLoadDynLtgPrmForFrntLeGrp13OffsetTime 1;
BA_ "GenSigSendType" SG_ 813 DwnLoadDynLtgPrmForFrntLeGrp13Timestamp 1;
// Frame: CemBodyExpoFr80
BA_ "GenMsgSendType" BO_ 814 1;
BA_ "GenMsgDelayTime" BO_ 814 35.000;
BA_ "GenSigSendType" SG_ 814 DwnLoadDynLtgPrmForFrntLeGrp14ContinueTime 1;
BA_ "GenSigSendType" SG_ 814 DwnLoadDynLtgPrmForFrntLeGrp14HighBrightness 1;
BA_ "GenSigSendType" SG_ 814 DwnLoadDynLtgPrmForFrntLeGrp14LowBrightness 1;
BA_ "GenSigSendType" SG_ 814 DwnLoadDynLtgPrmForFrntLeGrp14Mode1 1;
BA_ "GenSigSendType" SG_ 814 DwnLoadDynLtgPrmForFrntLeGrp14OffsetTime 1;
BA_ "GenSigSendType" SG_ 814 DwnLoadDynLtgPrmForFrntLeGrp14Timestamp 1;
// Frame: CemBodyExpoFr81
BA_ "GenMsgSendType" BO_ 815 1;
BA_ "GenMsgDelayTime" BO_ 815 35.000;
BA_ "GenSigSendType" SG_ 815 DwnLoadDynLtgPrmForFrntLeGrp15ContinueTime 1;
BA_ "GenSigSendType" SG_ 815 DwnLoadDynLtgPrmForFrntLeGrp15HighBrightness 1;
BA_ "GenSigSendType" SG_ 815 DwnLoadDynLtgPrmForFrntLeGrp15LowBrightness 1;
BA_ "GenSigSendType" SG_ 815 DwnLoadDynLtgPrmForFrntLeGrp15Mode1 1;
BA_ "GenSigSendType" SG_ 815 DwnLoadDynLtgPrmForFrntLeGrp15OffsetTime 1;
BA_ "GenSigSendType" SG_ 815 DwnLoadDynLtgPrmForFrntLeGrp15Timestamp 1;
// Frame: CemBodyExpoFr82
BA_ "GenMsgSendType" BO_ 816 1;
BA_ "GenMsgDelayTime" BO_ 816 35.000;
BA_ "GenSigSendType" SG_ 816 DwnLoadDynLtgPrmForFrntLeGrp16ContinueTime 1;
BA_ "GenSigSendType" SG_ 816 DwnLoadDynLtgPrmForFrntLeGrp16HighBrightness 1;
BA_ "GenSigSendType" SG_ 816 DwnLoadDynLtgPrmForFrntLeGrp16LowBrightness 1;
BA_ "GenSigSendType" SG_ 816 DwnLoadDynLtgPrmForFrntLeGrp16Mode1 1;
BA_ "GenSigSendType" SG_ 816 DwnLoadDynLtgPrmForFrntLeGrp16OffsetTime 1;
BA_ "GenSigSendType" SG_ 816 DwnLoadDynLtgPrmForFrntLeGrp16Timestamp 1;
// Frame: CemBodyExpoFr83
BA_ "GenMsgSendType" BO_ 817 1;
BA_ "GenMsgDelayTime" BO_ 817 35.000;
BA_ "GenSigSendType" SG_ 817 DwnLoadDynLtgPrmForFrntLeGrp17ContinueTime 1;
BA_ "GenSigSendType" SG_ 817 DwnLoadDynLtgPrmForFrntLeGrp17HighBrightness 1;
BA_ "GenSigSendType" SG_ 817 DwnLoadDynLtgPrmForFrntLeGrp17LowBrightness 1;
BA_ "GenSigSendType" SG_ 817 DwnLoadDynLtgPrmForFrntLeGrp17Mode1 1;
BA_ "GenSigSendType" SG_ 817 DwnLoadDynLtgPrmForFrntLeGrp17OffsetTime 1;
BA_ "GenSigSendType" SG_ 817 DwnLoadDynLtgPrmForFrntLeGrp17Timestamp 1;
// Frame: CemBodyExpoFr84
BA_ "GenMsgSendType" BO_ 818 1;
BA_ "GenMsgDelayTime" BO_ 818 35.000;
BA_ "GenSigSendType" SG_ 818 DwnLoadDynLtgPrmForFrntLeGrp18ContinueTime 1;
BA_ "GenSigSendType" SG_ 818 DwnLoadDynLtgPrmForFrntLeGrp18HighBrightness 1;
BA_ "GenSigSendType" SG_ 818 DwnLoadDynLtgPrmForFrntLeGrp18LowBrightness 1;
BA_ "GenSigSendType" SG_ 818 DwnLoadDynLtgPrmForFrntLeGrp18Mode1 1;
BA_ "GenSigSendType" SG_ 818 DwnLoadDynLtgPrmForFrntLeGrp18OffsetTime 1;
BA_ "GenSigSendType" SG_ 818 DwnLoadDynLtgPrmForFrntLeGrp18Timestamp 1;
// Frame: CemBodyExpoFr85
BA_ "GenMsgSendType" BO_ 819 1;
BA_ "GenMsgDelayTime" BO_ 819 35.000;
BA_ "GenSigSendType" SG_ 819 DwnLoadDynLtgPrmForFrntLeGrp19ContinueTime 1;
BA_ "GenSigSendType" SG_ 819 DwnLoadDynLtgPrmForFrntLeGrp19HighBrightness 1;
BA_ "GenSigSendType" SG_ 819 DwnLoadDynLtgPrmForFrntLeGrp19LowBrightness 1;
BA_ "GenSigSendType" SG_ 819 DwnLoadDynLtgPrmForFrntLeGrp19Mode1 1;
BA_ "GenSigSendType" SG_ 819 DwnLoadDynLtgPrmForFrntLeGrp19OffsetTime 1;
BA_ "GenSigSendType" SG_ 819 DwnLoadDynLtgPrmForFrntLeGrp19Timestamp 1;
// Frame: CemBodyExpoFr86
BA_ "GenMsgSendType" BO_ 820 1;
BA_ "GenMsgDelayTime" BO_ 820 35.000;
BA_ "GenSigSendType" SG_ 820 DwnLoadDynLtgPrmForFrntLeGrp20ContinueTime 1;
BA_ "GenSigSendType" SG_ 820 DwnLoadDynLtgPrmForFrntLeGrp20HighBrightness 1;
BA_ "GenSigSendType" SG_ 820 DwnLoadDynLtgPrmForFrntLeGrp20LowBrightness 1;
BA_ "GenSigSendType" SG_ 820 DwnLoadDynLtgPrmForFrntLeGrp20Mode1 1;
BA_ "GenSigSendType" SG_ 820 DwnLoadDynLtgPrmForFrntLeGrp20OffsetTime 1;
BA_ "GenSigSendType" SG_ 820 DwnLoadDynLtgPrmForFrntLeGrp20Timestamp 1;
// Frame: CemBodyExpoFr87
BA_ "GenMsgSendType" BO_ 821 1;
BA_ "GenMsgDelayTime" BO_ 821 35.000;
BA_ "GenSigSendType" SG_ 821 DwnLoadDynLtgPrmForFrntLeGrp21ContinueTime 1;
BA_ "GenSigSendType" SG_ 821 DwnLoadDynLtgPrmForFrntLeGrp21HighBrightness 1;
BA_ "GenSigSendType" SG_ 821 DwnLoadDynLtgPrmForFrntLeGrp21LowBrightness 1;
BA_ "GenSigSendType" SG_ 821 DwnLoadDynLtgPrmForFrntLeGrp21Mode1 1;
BA_ "GenSigSendType" SG_ 821 DwnLoadDynLtgPrmForFrntLeGrp21OffsetTime 1;
BA_ "GenSigSendType" SG_ 821 DwnLoadDynLtgPrmForFrntLeGrp21Timestamp 1;
// Frame: CemBodyExpoFr88
BA_ "GenMsgSendType" BO_ 822 1;
BA_ "GenMsgDelayTime" BO_ 822 35.000;
BA_ "GenSigSendType" SG_ 822 DwnLoadDynLtgPrmForFrntLeGrp22ContinueTime 1;
BA_ "GenSigSendType" SG_ 822 DwnLoadDynLtgPrmForFrntLeGrp22HighBrightness 1;
BA_ "GenSigSendType" SG_ 822 DwnLoadDynLtgPrmForFrntLeGrp22LowBrightness 1;
BA_ "GenSigSendType" SG_ 822 DwnLoadDynLtgPrmForFrntLeGrp22Mode1 1;
BA_ "GenSigSendType" SG_ 822 DwnLoadDynLtgPrmForFrntLeGrp22OffsetTime 1;
BA_ "GenSigSendType" SG_ 822 DwnLoadDynLtgPrmForFrntLeGrp22Timestamp 1;
// Frame: CemBodyExpoFr89
BA_ "GenMsgSendType" BO_ 823 1;
BA_ "GenMsgDelayTime" BO_ 823 35.000;
BA_ "GenSigSendType" SG_ 823 DwnLoadDynLtgPrmForFrntLeGrp23ContinueTime 1;
BA_ "GenSigSendType" SG_ 823 DwnLoadDynLtgPrmForFrntLeGrp23HighBrightness 1;
BA_ "GenSigSendType" SG_ 823 DwnLoadDynLtgPrmForFrntLeGrp23LowBrightness 1;
BA_ "GenSigSendType" SG_ 823 DwnLoadDynLtgPrmForFrntLeGrp23Mode1 1;
BA_ "GenSigSendType" SG_ 823 DwnLoadDynLtgPrmForFrntLeGrp23OffsetTime 1;
BA_ "GenSigSendType" SG_ 823 DwnLoadDynLtgPrmForFrntLeGrp23Timestamp 1;
// Frame: CemBodyExpoFr90
BA_ "GenMsgSendType" BO_ 824 1;
BA_ "GenMsgDelayTime" BO_ 824 35.000;
BA_ "GenSigSendType" SG_ 824 DwnLoadDynLtgPrmForFrntLeGrp24ContinueTime 1;
BA_ "GenSigSendType" SG_ 824 DwnLoadDynLtgPrmForFrntLeGrp24HighBrightness 1;
BA_ "GenSigSendType" SG_ 824 DwnLoadDynLtgPrmForFrntLeGrp24LowBrightness 1;
BA_ "GenSigSendType" SG_ 824 DwnLoadDynLtgPrmForFrntLeGrp24Mode1 1;
BA_ "GenSigSendType" SG_ 824 DwnLoadDynLtgPrmForFrntLeGrp24OffsetTime 1;
BA_ "GenSigSendType" SG_ 824 DwnLoadDynLtgPrmForFrntLeGrp24Timestamp 1;
// Frame: CemBodyExpoFr91
BA_ "GenMsgSendType" BO_ 825 1;
BA_ "GenMsgDelayTime" BO_ 825 35.000;
BA_ "GenSigSendType" SG_ 825 DwnLoadDynLtgPrmForFrntRIGrp1ContinueTime 1;
BA_ "GenSigSendType" SG_ 825 DwnLoadDynLtgPrmForFrntRIGrp1HighBrightness 1;
BA_ "GenSigSendType" SG_ 825 DwnLoadDynLtgPrmForFrntRIGrp1LowBrightness 1;
BA_ "GenSigSendType" SG_ 825 DwnLoadDynLtgPrmForFrntRIGrp1Mode1 1;
BA_ "GenSigSendType" SG_ 825 DwnLoadDynLtgPrmForFrntRIGrp1OffsetTime 1;
BA_ "GenSigSendType" SG_ 825 DwnLoadDynLtgPrmForFrntRIGrp1Timestamp 1;
// Frame: CemBodyExpoFr92
BA_ "GenMsgSendType" BO_ 826 1;
BA_ "GenMsgDelayTime" BO_ 826 35.000;
BA_ "GenSigSendType" SG_ 826 DwnLoadDynLtgPrmForFrntRIGrp2ContinueTime 1;
BA_ "GenSigSendType" SG_ 826 DwnLoadDynLtgPrmForFrntRIGrp2HighBrightness 1;
BA_ "GenSigSendType" SG_ 826 DwnLoadDynLtgPrmForFrntRIGrp2LowBrightness 1;
BA_ "GenSigSendType" SG_ 826 DwnLoadDynLtgPrmForFrntRIGrp2Mode1 1;
BA_ "GenSigSendType" SG_ 826 DwnLoadDynLtgPrmForFrntRIGrp2OffsetTime 1;
BA_ "GenSigSendType" SG_ 826 DwnLoadDynLtgPrmForFrntRIGrp2Timestamp 1;
// Frame: CemBodyExpoFr93
BA_ "GenMsgSendType" BO_ 827 1;
BA_ "GenMsgDelayTime" BO_ 827 35.000;
BA_ "GenSigSendType" SG_ 827 DwnLoadDynLtgPrmForFrntRIGrp3ContinueTime 1;
BA_ "GenSigSendType" SG_ 827 DwnLoadDynLtgPrmForFrntRIGrp3HighBrightness 1;
BA_ "GenSigSendType" SG_ 827 DwnLoadDynLtgPrmForFrntRIGrp3LowBrightness 1;
BA_ "GenSigSendType" SG_ 827 DwnLoadDynLtgPrmForFrntRIGrp3Mode1 1;
BA_ "GenSigSendType" SG_ 827 DwnLoadDynLtgPrmForFrntRIGrp3OffsetTime 1;
BA_ "GenSigSendType" SG_ 827 DwnLoadDynLtgPrmForFrntRIGrp3Timestamp 1;
// Frame: CemBodyExpoFr94
BA_ "GenMsgSendType" BO_ 828 1;
BA_ "GenMsgDelayTime" BO_ 828 35.000;
BA_ "GenSigSendType" SG_ 828 DwnLoadDynLtgPrmForFrntRIGrp4ContinueTime 1;
BA_ "GenSigSendType" SG_ 828 DwnLoadDynLtgPrmForFrntRIGrp4HighBrightness 1;
BA_ "GenSigSendType" SG_ 828 DwnLoadDynLtgPrmForFrntRIGrp4LowBrightness 1;
BA_ "GenSigSendType" SG_ 828 DwnLoadDynLtgPrmForFrntRIGrp4Mode1 1;
BA_ "GenSigSendType" SG_ 828 DwnLoadDynLtgPrmForFrntRIGrp4OffsetTime 1;
BA_ "GenSigSendType" SG_ 828 DwnLoadDynLtgPrmForFrntRIGrp4Timestamp 1;
// Frame: CemBodyExpoFr95
BA_ "GenMsgSendType" BO_ 829 1;
BA_ "GenMsgDelayTime" BO_ 829 35.000;
BA_ "GenSigSendType" SG_ 829 DwnLoadDynLtgPrmForFrntRIGrp5ContinueTime 1;
BA_ "GenSigSendType" SG_ 829 DwnLoadDynLtgPrmForFrntRIGrp5HighBrightness 1;
BA_ "GenSigSendType" SG_ 829 DwnLoadDynLtgPrmForFrntRIGrp5LowBrightness 1;
BA_ "GenSigSendType" SG_ 829 DwnLoadDynLtgPrmForFrntRIGrp5Mode1 1;
BA_ "GenSigSendType" SG_ 829 DwnLoadDynLtgPrmForFrntRIGrp5OffsetTime 1;
BA_ "GenSigSendType" SG_ 829 DwnLoadDynLtgPrmForFrntRIGrp5Timestamp 1;
// Frame: CemBodyExpoFr96
BA_ "GenMsgSendType" BO_ 830 1;
BA_ "GenMsgDelayTime" BO_ 830 35.000;
BA_ "GenSigSendType" SG_ 830 DwnLoadDynLtgPrmForFrntRIGrp6ContinueTime 1;
BA_ "GenSigSendType" SG_ 830 DwnLoadDynLtgPrmForFrntRIGrp6HighBrightness 1;
BA_ "GenSigSendType" SG_ 830 DwnLoadDynLtgPrmForFrntRIGrp6LowBrightness 1;
BA_ "GenSigSendType" SG_ 830 DwnLoadDynLtgPrmForFrntRIGrp6Mode1 1;
BA_ "GenSigSendType" SG_ 830 DwnLoadDynLtgPrmForFrntRIGrp6OffsetTime 1;
BA_ "GenSigSendType" SG_ 830 DwnLoadDynLtgPrmForFrntRIGrp6Timestamp 1;
// Frame: CemBodyExpoFr97
BA_ "GenMsgSendType" BO_ 831 1;
BA_ "GenMsgDelayTime" BO_ 831 35.000;
BA_ "GenSigSendType" SG_ 831 DwnLoadDynLtgPrmForFrntRIGrp7ContinueTime 1;
BA_ "GenSigSendType" SG_ 831 DwnLoadDynLtgPrmForFrntRIGrp7HighBrightness 1;
BA_ "GenSigSendType" SG_ 831 DwnLoadDynLtgPrmForFrntRIGrp7LowBrightness 1;
BA_ "GenSigSendType" SG_ 831 DwnLoadDynLtgPrmForFrntRIGrp7Mode1 1;
BA_ "GenSigSendType" SG_ 831 DwnLoadDynLtgPrmForFrntRIGrp7OffsetTime 1;
BA_ "GenSigSendType" SG_ 831 DwnLoadDynLtgPrmForFrntRIGrp7Timestamp 1;
// Frame: CemBodyExpoFr98
BA_ "GenMsgSendType" BO_ 832 1;
BA_ "GenMsgDelayTime" BO_ 832 35.000;
BA_ "GenSigSendType" SG_ 832 DwnLoadDynLtgPrmForFrntRIGrp8ContinueTime 1;
BA_ "GenSigSendType" SG_ 832 DwnLoadDynLtgPrmForFrntRIGrp8HighBrightness 1;
BA_ "GenSigSendType" SG_ 832 DwnLoadDynLtgPrmForFrntRIGrp8LowBrightness 1;
BA_ "GenSigSendType" SG_ 832 DwnLoadDynLtgPrmForFrntRIGrp8Mode1 1;
BA_ "GenSigSendType" SG_ 832 DwnLoadDynLtgPrmForFrntRIGrp8OffsetTime 1;
BA_ "GenSigSendType" SG_ 832 DwnLoadDynLtgPrmForFrntRIGrp8Timestamp 1;
// Frame: CemBodyExpoFr99
BA_ "GenMsgSendType" BO_ 833 1;
BA_ "GenMsgDelayTime" BO_ 833 35.000;
BA_ "GenSigSendType" SG_ 833 DwnLoadDynLtgPrmForFrntRIGrp9ContinueTime 1;
BA_ "GenSigSendType" SG_ 833 DwnLoadDynLtgPrmForFrntRIGrp9HighBrightness 1;
BA_ "GenSigSendType" SG_ 833 DwnLoadDynLtgPrmForFrntRIGrp9LowBrightness 1;
BA_ "GenSigSendType" SG_ 833 DwnLoadDynLtgPrmForFrntRIGrp9Mode1 1;
BA_ "GenSigSendType" SG_ 833 DwnLoadDynLtgPrmForFrntRIGrp9OffsetTime 1;
BA_ "GenSigSendType" SG_ 833 DwnLoadDynLtgPrmForFrntRIGrp9Timestamp 1;
// Frame: CemToAllFuncBodyCanExposedDiagReqFrame
BA_ "GenMsgSendType" BO_ 2047 1;
BA_ "GenMsgDelayTime" BO_ 2047 5.000;
// Frame: CemToDpod2BodyCanExposedDiagReqFrame
BA_ "GenMsgSendType" BO_ 1969 1;
BA_ "GenMsgDelayTime" BO_ 1969 5.000;
// Frame: CemToFccmBodyCanExposedDiagReqFrame
BA_ "GenMsgSendType" BO_ 1978 1;
BA_ "GenMsgDelayTime" BO_ 1978 5.000;
// Frame: CemToGcmBodyCanExposedDiagReqFrame
BA_ "GenMsgSendType" BO_ 1977 1;
BA_ "GenMsgDelayTime" BO_ 1977 5.000;
// Frame: CemToGpflBodyCanExposedDiagReqFrame
BA_ "GenMsgSendType" BO_ 1981 1;
BA_ "GenMsgDelayTime" BO_ 1981 5.000;
// Frame: CemToGpfrBodyCanExposedDiagReqFrame
BA_ "GenMsgSendType" BO_ 1982 1;
BA_ "GenMsgDelayTime" BO_ 1982 5.000;
// Frame: CemToGprlBodyCanExposedDiagReqFrame
BA_ "GenMsgSendType" BO_ 1984 1;
BA_ "GenMsgDelayTime" BO_ 1984 5.000;
// Frame: CemToGprrBodyCanExposedDiagReqFrame
BA_ "GenMsgSendType" BO_ 1985 1;
BA_ "GenMsgDelayTime" BO_ 1985 5.000;
// Frame: CemToHcmlBodyCanExposedDiagReqFrame
BA_ "GenMsgSendType" BO_ 1971 1;
BA_ "GenMsgDelayTime" BO_ 1971 5.000;
// Frame: CemToHcmrBodyCanExposedDiagReqFrame
BA_ "GenMsgSendType" BO_ 1972 1;
BA_ "GenMsgDelayTime" BO_ 1972 5.000;
// Frame: CemToLpod2BodyCanExposedDiagReqFrame
BA_ "GenMsgSendType" BO_ 1968 1;
BA_ "GenMsgDelayTime" BO_ 1968 5.000;
// Frame: CemToPpod2BodyCanExposedDiagReqFrame
BA_ "GenMsgSendType" BO_ 1980 1;
BA_ "GenMsgDelayTime" BO_ 1980 5.000;
// Frame: CemToRcmBodyCanExposedDiagReqFrame
BA_ "GenMsgSendType" BO_ 1970 1;
BA_ "GenMsgDelayTime" BO_ 1970 5.000;
// Frame: CemToRcmlBodyCanExposedDiagReqFrame
BA_ "GenMsgSendType" BO_ 1973 1;
BA_ "GenMsgDelayTime" BO_ 1973 5.000;
// Frame: CemToRcmmBodyCanExposedDiagReqFrame
BA_ "GenMsgSendType" BO_ 1975 1;
BA_ "GenMsgDelayTime" BO_ 1975 5.000;
// Frame: CemToRcmrBodyCanExposedDiagReqFrame
BA_ "GenMsgSendType" BO_ 1974 1;
BA_ "GenMsgDelayTime" BO_ 1974 5.000;
// Frame: CemToRpod2BodyCanExposedDiagReqFrame
BA_ "GenMsgSendType" BO_ 1979 1;
BA_ "GenMsgDelayTime" BO_ 1979 5.000;
// Frame: EtcToCemBodyExpoDevDiagFr03
BA_ "GenMsgSendType" BO_ 1425 1;
BA_ "GenMsgDelayTime" BO_ 1425 95.000;
BA_ "GenSigSendType" SG_ 1425 CEMdevelpsignalgroupreqFunctiondevpsignalgroup1 1;
BA_ "GenSigSendType" SG_ 1425 CEMdevelpsignalgroupreqFunctiondevpsignalgroup2 1;
BA_ "GenSigSendType" SG_ 1425 CEMdevelpsignalgroupreqFunctiondevpsignalgroup3 1;
BA_ "GenSigSendType" SG_ 1425 CEMdevelpsignalgroupreqFunctiondevpsignalgroup4 1;
BA_ "GenSigSendType" SG_ 1425 CEMdevelpsignalgroupreqFunctiondevpsignalgroup5 1;
BA_ "GenSigSendType" SG_ 1425 CEMdevelpsignalgroupreqFunctiondevpsignalgroup6 1;
BA_ "GenSigSendType" SG_ 1425 CEMdevelpsignalgroupreqFunctiondevpsignalgroup7 1;
BA_ "GenSigSendType" SG_ 1425 CEMdevelpsignalgroupreqFunctiondevpsignalgroup8 1;
// Frame: EtctoHcmlXCPFr01
BA_ "GenMsgSendType" BO_ 1430 1;
BA_ "GenMsgDelayTime" BO_ 1430 10.000;
// Frame: EtctoHcmrXCPFr01
BA_ "GenMsgSendType" BO_ 1428 1;
BA_ "GenMsgDelayTime" BO_ 1428 10.000;
// Frame: HcmlBodyExpoFr02
BA_ "GenMsgSendType" BO_ 593 0;
BA_ "GenMsgCycleTime" BO_ 593 50.000;
BA_ "GenSigSendType" SG_ 593 ExtrLiShowStoreStsFrntLe 0;
BA_ "GenSigSendType" SG_ 593 StsOfLedHiBeamLe 0;
BA_ "GenSigSendType" SG_ 593 StsOfLedLeLogoLamp 0;
BA_ "GenSigSendType" SG_ 593 StsOfLedLoBeamLe 0;
// Frame: HcmlBodyExpoFr04
BA_ "GenMsgSendType" BO_ 124 0;
BA_ "GenMsgCycleTime" BO_ 124 50.000;
BA_ "GenSigSendType" SG_ 124 DwnLoadStsFbOfHdlampLe 0;
BA_ "GenSigSendType" SG_ 124 DwnLoadStsFbOfLogoLampLe 0;
BA_ "GenSigSendType" SG_ 124 ExtrLiShowActvnFrntLeFb 0;
BA_ "GenSigSendType" SG_ 124 ExtrLiShowActvnLeLogoFb 0;
BA_ "GenSigSendType" SG_ 124 HdlampLeInpSts1 0;
BA_ "GenSigSendType" SG_ 124 HdlampLeInpSts2 0;
BA_ "GenSigSendType" SG_ 124 StsOfAfsLe 0;
BA_ "GenSigSendType" SG_ 124 StsOfAhbcLe 0;
BA_ "GenSigSendType" SG_ 124 StsOfFrntSideMkrLampLe2 0;
BA_ "GenSigSendType" SG_ 124 StsOfLedCornrgLampLe 0;
BA_ "GenSigSendType" SG_ 124 StsOfLedDaytiRunngLampLe 0;
BA_ "GenSigSendType" SG_ 124 StsOfLedFrntFogLampLe 0;
BA_ "GenSigSendType" SG_ 124 StsOfLedFrntPosnLampLe 0;
BA_ "GenSigSendType" SG_ 124 StsOfLedFrntTurnIndcrLe 0;
BA_ "GenSigSendType" SG_ 124 StsOfLvlgLeChks 0;
BA_ "GenSigSendType" SG_ 124 StsOfLvlgLeCntr 0;
BA_ "GenSigSendType" SG_ 124 StsOfLvlgLeStsOfLvlgLe 0;
BA_ "GenSigSendType" SG_ 124 StsOfSwvlgLe 0;
BA_ "GenSigSendType" SG_ 124 StsOfTouristModLe 0;
BA_ "GenSigSendType" SG_ 124 StsOfWelGbyFrntLe 0;
// Frame: HcmlBodyExposedNMFr
BA_ "GenMsgSendType" BO_ 1329 1;
BA_ "GenMsgDelayTime" BO_ 1329 20.000;
BA_ "GenMsgILSupport" BO_ 1329 0;
BA_ "NmAsrMessage" BO_ 1329 1;
// Frame: HcmlToCemBodyCanExposedDiagResFrame
BA_ "GenMsgSendType" BO_ 1715 1;
BA_ "GenMsgDelayTime" BO_ 1715 5.000;
// Frame: HcmltoEtcXCPFr01
BA_ "GenMsgSendType" BO_ 1424 1;
BA_ "GenMsgDelayTime" BO_ 1424 10.000;
// Frame: HcmrBodyExpoFr02
BA_ "GenMsgSendType" BO_ 594 0;
BA_ "GenMsgCycleTime" BO_ 594 50.000;
BA_ "GenSigSendType" SG_ 594 ExtrLiShowStoreStsFrntRi 0;
BA_ "GenSigSendType" SG_ 594 StsOfLedHiBeamRi 0;
BA_ "GenSigSendType" SG_ 594 StsOfLedLoBeamRi 0;
BA_ "GenSigSendType" SG_ 594 StsOfLedRiLogoLamp 0;
// Frame: HcmrBodyExpoFr04
BA_ "GenMsgSendType" BO_ 127 0;
BA_ "GenMsgCycleTime" BO_ 127 50.000;
BA_ "GenSigSendType" SG_ 127 DwnLoadStsFbOfHdlampRi 0;
BA_ "GenSigSendType" SG_ 127 DwnLoadStsFbOfLogoLampRi 0;
BA_ "GenSigSendType" SG_ 127 ExtrLiShowActvnFrntRiFb 0;
BA_ "GenSigSendType" SG_ 127 ExtrLiShowActvnRiLogoFb 0;
BA_ "GenSigSendType" SG_ 127 HdlampRiInpSts1 0;
BA_ "GenSigSendType" SG_ 127 HdlampRiInpSts2 0;
BA_ "GenSigSendType" SG_ 127 StsOfAfsRi 0;
BA_ "GenSigSendType" SG_ 127 StsOfAhbcRi 0;
BA_ "GenSigSendType" SG_ 127 StsOfFrntSideMkrLampRi2 0;
BA_ "GenSigSendType" SG_ 127 StsOfLedCornrgLampRi 0;
BA_ "GenSigSendType" SG_ 127 StsOfLedDaytiRunngLampRi 0;
BA_ "GenSigSendType" SG_ 127 StsOfLedFrntFogLampRi 0;
BA_ "GenSigSendType" SG_ 127 StsOfLedFrntPosnLampRi 0;
BA_ "GenSigSendType" SG_ 127 StsOfLedFrntTurnIndcrRi 0;
BA_ "GenSigSendType" SG_ 127 StsOfLvlgRiChks 0;
BA_ "GenSigSendType" SG_ 127 StsOfLvlgRiCntr 0;
BA_ "GenSigSendType" SG_ 127 StsOfLvlgRiStsOfLvlgRi 0;
BA_ "GenSigSendType" SG_ 127 StsOfSwvlgRi 0;
BA_ "GenSigSendType" SG_ 127 StsOfTouristModRi 0;
BA_ "GenSigSendType" SG_ 127 StsOfWelGbyFrntRi 0;
// Frame: HcmrBodyExposedNMFr
BA_ "GenMsgSendType" BO_ 1330 1;
BA_ "GenMsgDelayTime" BO_ 1330 20.000;
BA_ "GenMsgILSupport" BO_ 1330 0;
BA_ "NmAsrMessage" BO_ 1330 1;
// Frame: HcmrToCemBodyCanExposedDiagResFrame
BA_ "GenMsgSendType" BO_ 1716 1;
BA_ "GenMsgDelayTime" BO_ 1716 5.000;
// Frame: HcmrtoEtcXCPFr01
BA_ "GenMsgSendType" BO_ 1426 1;
BA_ "GenMsgDelayTime" BO_ 1426 10.000;
// Frame: RcmlBodyExpoFr01
BA_ "GenMsgSendType" BO_ 592 0;
BA_ "GenMsgCycleTime" BO_ 592 50.000;
BA_ "GenSigSendType" SG_ 592 DwnLoadStsFbOfReLampCtrlLe1 0;
BA_ "GenSigSendType" SG_ 592 ExtrLiShowActvnReLeFb 0;
BA_ "GenSigSendType" SG_ 592 ExtrLiShowStoreStsReLe1 0;
BA_ "GenSigSendType" SG_ 592 StsOfLedPosnLampLe1 0;
BA_ "GenSigSendType" SG_ 592 StsOfLedReFogLampLe1 0;
BA_ "GenSigSendType" SG_ 592 StsOfLedReLampLe1 0;
BA_ "GenSigSendType" SG_ 592 StsOfLedRvsgLampLe1 0;
BA_ "GenSigSendType" SG_ 592 StsOfLedStopLampLe1 0;
BA_ "GenSigSendType" SG_ 592 StsOfLedTurnIndcrLe1 0;
BA_ "GenSigSendType" SG_ 592 StsOfWelGbyReLe1 0;
// Frame: RcmlBodyExposedNMFr
BA_ "GenMsgSendType" BO_ 1331 1;
BA_ "GenMsgDelayTime" BO_ 1331 20.000;
BA_ "GenMsgILSupport" BO_ 1331 0;
BA_ "NmAsrMessage" BO_ 1331 1;
// Frame: RcmlToCemBodyCanExposedDiagResFrame
BA_ "GenMsgSendType" BO_ 1717 1;
BA_ "GenMsgDelayTime" BO_ 1717 5.000;
// Frame: RcmmBodyExpoFr02
BA_ "GenMsgSendType" BO_ 596 0;
BA_ "GenMsgCycleTime" BO_ 596 50.000;
BA_ "GenSigSendType" SG_ 596 DwnLoadStsFbOfReLampCtrlLe2 0;
BA_ "GenSigSendType" SG_ 596 DwnLoadStsFbOfReLampCtrlRi2 0;
BA_ "GenSigSendType" SG_ 596 ExtrLiShowActvnReLe2Fb 0;
BA_ "GenSigSendType" SG_ 596 ExtrLiShowActvnReRi2Fb 0;
BA_ "GenSigSendType" SG_ 596 ExtrLiShowStoreStsReLe2 0;
BA_ "GenSigSendType" SG_ 596 ExtrLiShowStoreStsReRi2 0;
BA_ "GenSigSendType" SG_ 596 StsOfLedPosnLampLe2 0;
BA_ "GenSigSendType" SG_ 596 StsOfLedPosnLampRi2 0;
BA_ "GenSigSendType" SG_ 596 StsOfLedReFogLampLe2 0;
BA_ "GenSigSendType" SG_ 596 StsOfLedReFogLampRi2 0;
BA_ "GenSigSendType" SG_ 596 StsOfLedReLampLe2 0;
BA_ "GenSigSendType" SG_ 596 StsOfLedReLampRi2 0;
BA_ "GenSigSendType" SG_ 596 StsOfLedRvsgLampLe2 0;
BA_ "GenSigSendType" SG_ 596 StsOfLedRvsgLampRi2 0;
BA_ "GenSigSendType" SG_ 596 StsOfLedStopLampLe2 0;
BA_ "GenSigSendType" SG_ 596 StsOfLedStopLampRi2 0;
BA_ "GenSigSendType" SG_ 596 StsOfLedTurnIndcrLe2 0;
BA_ "GenSigSendType" SG_ 596 StsOfLedTurnIndcrRi2 0;
BA_ "GenSigSendType" SG_ 596 StsOfWelGbyReLe2 0;
BA_ "GenSigSendType" SG_ 596 StsOfWelGbyReRi2 0;
// Frame: RcmmBodyExposedNMFr
BA_ "GenMsgSendType" BO_ 1333 1;
BA_ "GenMsgDelayTime" BO_ 1333 20.000;
BA_ "GenMsgILSupport" BO_ 1333 0;
BA_ "NmAsrMessage" BO_ 1333 1;
// Frame: RcmmToCemBodyCanExposedDiagResFrame
BA_ "GenMsgSendType" BO_ 1719 1;
BA_ "GenMsgDelayTime" BO_ 1719 5.000;
// Frame: RcmrBodyExpoFr01
BA_ "GenMsgSendType" BO_ 608 0;
BA_ "GenMsgCycleTime" BO_ 608 50.000;
BA_ "GenSigSendType" SG_ 608 DwnLoadStsFbOfReLampCtrlRi1 0;
BA_ "GenSigSendType" SG_ 608 ExtrLiShowActvnReRiFb 0;
BA_ "GenSigSendType" SG_ 608 ExtrLiShowStoreStsReRi1 0;
BA_ "GenSigSendType" SG_ 608 StsOfLedPosnLampRi1 0;
BA_ "GenSigSendType" SG_ 608 StsOfLedReFogLampRi1 0;
BA_ "GenSigSendType" SG_ 608 StsOfLedReLampRi1 0;
BA_ "GenSigSendType" SG_ 608 StsOfLedRvsgLampRi1 0;
BA_ "GenSigSendType" SG_ 608 StsOfLedStopLampRi1 0;
BA_ "GenSigSendType" SG_ 608 StsOfLedTurnIndcrRi1 0;
BA_ "GenSigSendType" SG_ 608 StsOfWelGbyReRi1 0;
// Frame: RcmrBodyExposedNMFr
BA_ "GenMsgSendType" BO_ 1332 1;
BA_ "GenMsgDelayTime" BO_ 1332 20.000;
BA_ "GenMsgILSupport" BO_ 1332 0;
BA_ "NmAsrMessage" BO_ 1332 1;
// Frame: RcmrToCemBodyCanExposedDiagResFrame
BA_ "GenMsgSendType" BO_ 1718 1;
BA_ "GenMsgDelayTime" BO_ 1718 5.000;
VAL_ 789 DHUcontrolCrossreversinglight 0 "OnOffNoReq_NoReq" 1 "OnOffNoReq_On" 2 "OnOffNoReq_Off";
VAL_ 789 DHUcontrolleftbrakelightLamp 0 "OnOffNoReq_NoReq" 1 "OnOffNoReq_On" 2 "OnOffNoReq_Off";
VAL_ 789 DHUcontrolleftpositionlight 0 "OnOffNoReq_NoReq" 1 "OnOffNoReq_On" 2 "OnOffNoReq_Off";
VAL_ 789 DHUcontrolrightbrakelight 0 "OnOffNoReq_NoReq" 1 "OnOffNoReq_On" 2 "OnOffNoReq_Off";
VAL_ 335 DwnLoadDynLitPrmLedFrntMidPosnLiModePrm 0 "Mode1_Off" 1 "Mode1_On" 2 "Mode1_GradualOn" 3 "Mode1_GradualOff" 4 "Mode1_ForwardWipingOn" 5 "Mode1_BackwardWipingOn" 6 "Mode1_OutwardWipingOn" 7 "Mode1_InwardWipingOn" 8 "Mode1_ForwardWipingOff" 9 "Mode1_BackwardWipingOff" 10 "Mode1_OutwardWipingOff" 11 "Mode1_InwardWipingOff" 12 "Mode1_ForwardScanning" 13 "Mode1_BackwardScanning" 14 "Mode1_BreathOn" 15 "Mode1_BreathOff" 16 "Mode1_Spare1" 17 "Mode1_Spare2";
VAL_ 336 DwnLoadDynLitPrmLedLeSideLogoLiModePrm 0 "Mode1_Off" 1 "Mode1_On" 2 "Mode1_GradualOn" 3 "Mode1_GradualOff" 4 "Mode1_ForwardWipingOn" 5 "Mode1_BackwardWipingOn" 6 "Mode1_OutwardWipingOn" 7 "Mode1_InwardWipingOn" 8 "Mode1_ForwardWipingOff" 9 "Mode1_BackwardWipingOff" 10 "Mode1_OutwardWipingOff" 11 "Mode1_InwardWipingOff" 12 "Mode1_ForwardScanning" 13 "Mode1_BackwardScanning" 14 "Mode1_BreathOn" 15 "Mode1_BreathOff" 16 "Mode1_Spare1" 17 "Mode1_Spare2";
VAL_ 337 DwnLoadDynLitPrmLedRiSideLogoLiModePrm 0 "Mode1_Off" 1 "Mode1_On" 2 "Mode1_GradualOn" 3 "Mode1_GradualOff" 4 "Mode1_ForwardWipingOn" 5 "Mode1_BackwardWipingOn" 6 "Mode1_OutwardWipingOn" 7 "Mode1_InwardWipingOn" 8 "Mode1_ForwardWipingOff" 9 "Mode1_BackwardWipingOff" 10 "Mode1_OutwardWipingOff" 11 "Mode1_InwardWipingOff" 12 "Mode1_ForwardScanning" 13 "Mode1_BackwardScanning" 14 "Mode1_BreathOn" 15 "Mode1_BreathOff" 16 "Mode1_Spare1" 17 "Mode1_Spare2";
VAL_ 801 DHUcontrolLedLogoLamp 0 "OnOffNoReq_NoReq" 1 "OnOffNoReq_On" 2 "OnOffNoReq_Off";
VAL_ 801 DwnLoadDynLtgPrmForFrntLeGrp1Mode1 0 "Mode4_Off" 1 "Mode4_On" 2 "Mode4_GradualOn" 3 "Mode4_GradualOff" 4 "Mode4_ForwardWipingOn" 5 "Mode4_BackwardWipingOn" 6 "Mode4_OutwardWipingOn" 7 "Mode4_InwardWipingOn" 8 "Mode4_ForwardWipingOff" 9 "Mode4_BackwardWipingOff" 10 "Mode4_OutwardWipingOff" 11 "Mode4_InwardWipingOff" 12 "Mode4_ForwardScanning" 13 "Mode4_BackwardScanning" 14 "Mode4_BreathOn" 15 "Mode4_BreathOff" 16 "Mode4_1stHalfONand2ndHalfOFF" 17 "Mode4_HalfOFFHalfON" 18 "Mode4_HalfDimmingONHalfOFF" 19 "Mode4_HalfDimmingONHalfON" 20 "Mode4_HalfOFFHalfDimmingON" 21 "Mode4_HalfONHalfDimmingON" 22 "Mode4_HalfDimmingOFFHalfOFF" 23 "Mode4_HalfDimmingOFFHalfON" 24 "Mode4_HalfOFFHalfDimmingOFF" 25 "Mode4_HalfONHalfDimmingOFF" 26 "Mode4_SingleOn1" 27 "Mode4_SingleOn2" 28 "Mode4_SingleOn3" 29 "Mode4_SingleOn4" 30 "Mode4_SingleOn5" 31 "Mode4_SingleOn6" 32 "Mode4_SingleOn7" 33 "Mode4_SingleOn8" 34 "Mode4_SingleOn9" 35 "Mode4_SingleOn10" 36 "Mode4_SingleOn11" 37 "Mode4_SingleOn12" 38 "Mode4_SingleOff1" 39 "Mode4_SingleOff2" 40 "Mode4_SingleOff3" 41 "Mode4_SingleOff4" 42 "Mode4_SingleOff5" 43 "Mode4_SingleOff6" 44 "Mode4_SingleOff7" 45 "Mode4_SingleOff8" 46 "Mode4_SingleOff9" 47 "Mode4_SingleOff10" 48 "Mode4_SingleOff11" 49 "Mode4_SingleOff12";
VAL_ 801 WelLiFileTxReq 0 "OnOff1_Off" 1 "OnOff1_On";
VAL_ 802 DwnLoadDynLtgPrmForFrntLeGrp2Mode1 0 "Mode4_Off" 1 "Mode4_On" 2 "Mode4_GradualOn" 3 "Mode4_GradualOff" 4 "Mode4_ForwardWipingOn" 5 "Mode4_BackwardWipingOn" 6 "Mode4_OutwardWipingOn" 7 "Mode4_InwardWipingOn" 8 "Mode4_ForwardWipingOff" 9 "Mode4_BackwardWipingOff" 10 "Mode4_OutwardWipingOff" 11 "Mode4_InwardWipingOff" 12 "Mode4_ForwardScanning" 13 "Mode4_BackwardScanning" 14 "Mode4_BreathOn" 15 "Mode4_BreathOff" 16 "Mode4_1stHalfONand2ndHalfOFF" 17 "Mode4_HalfOFFHalfON" 18 "Mode4_HalfDimmingONHalfOFF" 19 "Mode4_HalfDimmingONHalfON" 20 "Mode4_HalfOFFHalfDimmingON" 21 "Mode4_HalfONHalfDimmingON" 22 "Mode4_HalfDimmingOFFHalfOFF" 23 "Mode4_HalfDimmingOFFHalfON" 24 "Mode4_HalfOFFHalfDimmingOFF" 25 "Mode4_HalfONHalfDimmingOFF" 26 "Mode4_SingleOn1" 27 "Mode4_SingleOn2" 28 "Mode4_SingleOn3" 29 "Mode4_SingleOn4" 30 "Mode4_SingleOn5" 31 "Mode4_SingleOn6" 32 "Mode4_SingleOn7" 33 "Mode4_SingleOn8" 34 "Mode4_SingleOn9" 35 "Mode4_SingleOn10" 36 "Mode4_SingleOn11" 37 "Mode4_SingleOn12" 38 "Mode4_SingleOff1" 39 "Mode4_SingleOff2" 40 "Mode4_SingleOff3" 41 "Mode4_SingleOff4" 42 "Mode4_SingleOff5" 43 "Mode4_SingleOff6" 44 "Mode4_SingleOff7" 45 "Mode4_SingleOff8" 46 "Mode4_SingleOff9" 47 "Mode4_SingleOff10" 48 "Mode4_SingleOff11" 49 "Mode4_SingleOff12";
VAL_ 803 DwnLoadDynLtgPrmForFrntLeGrp3Mode1 0 "Mode4_Off" 1 "Mode4_On" 2 "Mode4_GradualOn" 3 "Mode4_GradualOff" 4 "Mode4_ForwardWipingOn" 5 "Mode4_BackwardWipingOn" 6 "Mode4_OutwardWipingOn" 7 "Mode4_InwardWipingOn" 8 "Mode4_ForwardWipingOff" 9 "Mode4_BackwardWipingOff" 10 "Mode4_OutwardWipingOff" 11 "Mode4_InwardWipingOff" 12 "Mode4_ForwardScanning" 13 "Mode4_BackwardScanning" 14 "Mode4_BreathOn" 15 "Mode4_BreathOff" 16 "Mode4_1stHalfONand2ndHalfOFF" 17 "Mode4_HalfOFFHalfON" 18 "Mode4_HalfDimmingONHalfOFF" 19 "Mode4_HalfDimmingONHalfON" 20 "Mode4_HalfOFFHalfDimmingON" 21 "Mode4_HalfONHalfDimmingON" 22 "Mode4_HalfDimmingOFFHalfOFF" 23 "Mode4_HalfDimmingOFFHalfON" 24 "Mode4_HalfOFFHalfDimmingOFF" 25 "Mode4_HalfONHalfDimmingOFF" 26 "Mode4_SingleOn1" 27 "Mode4_SingleOn2" 28 "Mode4_SingleOn3" 29 "Mode4_SingleOn4" 30 "Mode4_SingleOn5" 31 "Mode4_SingleOn6" 32 "Mode4_SingleOn7" 33 "Mode4_SingleOn8" 34 "Mode4_SingleOn9" 35 "Mode4_SingleOn10" 36 "Mode4_SingleOn11" 37 "Mode4_SingleOn12" 38 "Mode4_SingleOff1" 39 "Mode4_SingleOff2" 40 "Mode4_SingleOff3" 41 "Mode4_SingleOff4" 42 "Mode4_SingleOff5" 43 "Mode4_SingleOff6" 44 "Mode4_SingleOff7" 45 "Mode4_SingleOff8" 46 "Mode4_SingleOff9" 47 "Mode4_SingleOff10" 48 "Mode4_SingleOff11" 49 "Mode4_SingleOff12";
VAL_ 804 DwnLoadDynLtgPrmForFrntLeGrp4Mode1 0 "Mode4_Off" 1 "Mode4_On" 2 "Mode4_GradualOn" 3 "Mode4_GradualOff" 4 "Mode4_ForwardWipingOn" 5 "Mode4_BackwardWipingOn" 6 "Mode4_OutwardWipingOn" 7 "Mode4_InwardWipingOn" 8 "Mode4_ForwardWipingOff" 9 "Mode4_BackwardWipingOff" 10 "Mode4_OutwardWipingOff" 11 "Mode4_InwardWipingOff" 12 "Mode4_ForwardScanning" 13 "Mode4_BackwardScanning" 14 "Mode4_BreathOn" 15 "Mode4_BreathOff" 16 "Mode4_1stHalfONand2ndHalfOFF" 17 "Mode4_HalfOFFHalfON" 18 "Mode4_HalfDimmingONHalfOFF" 19 "Mode4_HalfDimmingONHalfON" 20 "Mode4_HalfOFFHalfDimmingON" 21 "Mode4_HalfONHalfDimmingON" 22 "Mode4_HalfDimmingOFFHalfOFF" 23 "Mode4_HalfDimmingOFFHalfON" 24 "Mode4_HalfOFFHalfDimmingOFF" 25 "Mode4_HalfONHalfDimmingOFF" 26 "Mode4_SingleOn1" 27 "Mode4_SingleOn2" 28 "Mode4_SingleOn3" 29 "Mode4_SingleOn4" 30 "Mode4_SingleOn5" 31 "Mode4_SingleOn6" 32 "Mode4_SingleOn7" 33 "Mode4_SingleOn8" 34 "Mode4_SingleOn9" 35 "Mode4_SingleOn10" 36 "Mode4_SingleOn11" 37 "Mode4_SingleOn12" 38 "Mode4_SingleOff1" 39 "Mode4_SingleOff2" 40 "Mode4_SingleOff3" 41 "Mode4_SingleOff4" 42 "Mode4_SingleOff5" 43 "Mode4_SingleOff6" 44 "Mode4_SingleOff7" 45 "Mode4_SingleOff8" 46 "Mode4_SingleOff9" 47 "Mode4_SingleOff10" 48 "Mode4_SingleOff11" 49 "Mode4_SingleOff12";
VAL_ 805 DwnLoadDynLtgPrmForFrntLeGrp5Mode1 0 "Mode4_Off" 1 "Mode4_On" 2 "Mode4_GradualOn" 3 "Mode4_GradualOff" 4 "Mode4_ForwardWipingOn" 5 "Mode4_BackwardWipingOn" 6 "Mode4_OutwardWipingOn" 7 "Mode4_InwardWipingOn" 8 "Mode4_ForwardWipingOff" 9 "Mode4_BackwardWipingOff" 10 "Mode4_OutwardWipingOff" 11 "Mode4_InwardWipingOff" 12 "Mode4_ForwardScanning" 13 "Mode4_BackwardScanning" 14 "Mode4_BreathOn" 15 "Mode4_BreathOff" 16 "Mode4_1stHalfONand2ndHalfOFF" 17 "Mode4_HalfOFFHalfON" 18 "Mode4_HalfDimmingONHalfOFF" 19 "Mode4_HalfDimmingONHalfON" 20 "Mode4_HalfOFFHalfDimmingON" 21 "Mode4_HalfONHalfDimmingON" 22 "Mode4_HalfDimmingOFFHalfOFF" 23 "Mode4_HalfDimmingOFFHalfON" 24 "Mode4_HalfOFFHalfDimmingOFF" 25 "Mode4_HalfONHalfDimmingOFF" 26 "Mode4_SingleOn1" 27 "Mode4_SingleOn2" 28 "Mode4_SingleOn3" 29 "Mode4_SingleOn4" 30 "Mode4_SingleOn5" 31 "Mode4_SingleOn6" 32 "Mode4_SingleOn7" 33 "Mode4_SingleOn8" 34 "Mode4_SingleOn9" 35 "Mode4_SingleOn10" 36 "Mode4_SingleOn11" 37 "Mode4_SingleOn12" 38 "Mode4_SingleOff1" 39 "Mode4_SingleOff2" 40 "Mode4_SingleOff3" 41 "Mode4_SingleOff4" 42 "Mode4_SingleOff5" 43 "Mode4_SingleOff6" 44 "Mode4_SingleOff7" 45 "Mode4_SingleOff8" 46 "Mode4_SingleOff9" 47 "Mode4_SingleOff10" 48 "Mode4_SingleOff11" 49 "Mode4_SingleOff12";
VAL_ 806 DwnLoadDynLtgPrmForFrntLeGrp6Mode1 0 "Mode4_Off" 1 "Mode4_On" 2 "Mode4_GradualOn" 3 "Mode4_GradualOff" 4 "Mode4_ForwardWipingOn" 5 "Mode4_BackwardWipingOn" 6 "Mode4_OutwardWipingOn" 7 "Mode4_InwardWipingOn" 8 "Mode4_ForwardWipingOff" 9 "Mode4_BackwardWipingOff" 10 "Mode4_OutwardWipingOff" 11 "Mode4_InwardWipingOff" 12 "Mode4_ForwardScanning" 13 "Mode4_BackwardScanning" 14 "Mode4_BreathOn" 15 "Mode4_BreathOff" 16 "Mode4_1stHalfONand2ndHalfOFF" 17 "Mode4_HalfOFFHalfON" 18 "Mode4_HalfDimmingONHalfOFF" 19 "Mode4_HalfDimmingONHalfON" 20 "Mode4_HalfOFFHalfDimmingON" 21 "Mode4_HalfONHalfDimmingON" 22 "Mode4_HalfDimmingOFFHalfOFF" 23 "Mode4_HalfDimmingOFFHalfON" 24 "Mode4_HalfOFFHalfDimmingOFF" 25 "Mode4_HalfONHalfDimmingOFF" 26 "Mode4_SingleOn1" 27 "Mode4_SingleOn2" 28 "Mode4_SingleOn3" 29 "Mode4_SingleOn4" 30 "Mode4_SingleOn5" 31 "Mode4_SingleOn6" 32 "Mode4_SingleOn7" 33 "Mode4_SingleOn8" 34 "Mode4_SingleOn9" 35 "Mode4_SingleOn10" 36 "Mode4_SingleOn11" 37 "Mode4_SingleOn12" 38 "Mode4_SingleOff1" 39 "Mode4_SingleOff2" 40 "Mode4_SingleOff3" 41 "Mode4_SingleOff4" 42 "Mode4_SingleOff5" 43 "Mode4_SingleOff6" 44 "Mode4_SingleOff7" 45 "Mode4_SingleOff8" 46 "Mode4_SingleOff9" 47 "Mode4_SingleOff10" 48 "Mode4_SingleOff11" 49 "Mode4_SingleOff12";
VAL_ 807 DwnLoadDynLtgPrmForFrntLeGrp7Mode1 0 "Mode4_Off" 1 "Mode4_On" 2 "Mode4_GradualOn" 3 "Mode4_GradualOff" 4 "Mode4_ForwardWipingOn" 5 "Mode4_BackwardWipingOn" 6 "Mode4_OutwardWipingOn" 7 "Mode4_InwardWipingOn" 8 "Mode4_ForwardWipingOff" 9 "Mode4_BackwardWipingOff" 10 "Mode4_OutwardWipingOff" 11 "Mode4_InwardWipingOff" 12 "Mode4_ForwardScanning" 13 "Mode4_BackwardScanning" 14 "Mode4_BreathOn" 15 "Mode4_BreathOff" 16 "Mode4_1stHalfONand2ndHalfOFF" 17 "Mode4_HalfOFFHalfON" 18 "Mode4_HalfDimmingONHalfOFF" 19 "Mode4_HalfDimmingONHalfON" 20 "Mode4_HalfOFFHalfDimmingON" 21 "Mode4_HalfONHalfDimmingON" 22 "Mode4_HalfDimmingOFFHalfOFF" 23 "Mode4_HalfDimmingOFFHalfON" 24 "Mode4_HalfOFFHalfDimmingOFF" 25 "Mode4_HalfONHalfDimmingOFF" 26 "Mode4_SingleOn1" 27 "Mode4_SingleOn2" 28 "Mode4_SingleOn3" 29 "Mode4_SingleOn4" 30 "Mode4_SingleOn5" 31 "Mode4_SingleOn6" 32 "Mode4_SingleOn7" 33 "Mode4_SingleOn8" 34 "Mode4_SingleOn9" 35 "Mode4_SingleOn10" 36 "Mode4_SingleOn11" 37 "Mode4_SingleOn12" 38 "Mode4_SingleOff1" 39 "Mode4_SingleOff2" 40 "Mode4_SingleOff3" 41 "Mode4_SingleOff4" 42 "Mode4_SingleOff5" 43 "Mode4_SingleOff6" 44 "Mode4_SingleOff7" 45 "Mode4_SingleOff8" 46 "Mode4_SingleOff9" 47 "Mode4_SingleOff10" 48 "Mode4_SingleOff11" 49 "Mode4_SingleOff12";
VAL_ 808 DwnLoadDynLtgPrmForFrntLeGrp8Mode1 0 "Mode4_Off" 1 "Mode4_On" 2 "Mode4_GradualOn" 3 "Mode4_GradualOff" 4 "Mode4_ForwardWipingOn" 5 "Mode4_BackwardWipingOn" 6 "Mode4_OutwardWipingOn" 7 "Mode4_InwardWipingOn" 8 "Mode4_ForwardWipingOff" 9 "Mode4_BackwardWipingOff" 10 "Mode4_OutwardWipingOff" 11 "Mode4_InwardWipingOff" 12 "Mode4_ForwardScanning" 13 "Mode4_BackwardScanning" 14 "Mode4_BreathOn" 15 "Mode4_BreathOff" 16 "Mode4_1stHalfONand2ndHalfOFF" 17 "Mode4_HalfOFFHalfON" 18 "Mode4_HalfDimmingONHalfOFF" 19 "Mode4_HalfDimmingONHalfON" 20 "Mode4_HalfOFFHalfDimmingON" 21 "Mode4_HalfONHalfDimmingON" 22 "Mode4_HalfDimmingOFFHalfOFF" 23 "Mode4_HalfDimmingOFFHalfON" 24 "Mode4_HalfOFFHalfDimmingOFF" 25 "Mode4_HalfONHalfDimmingOFF" 26 "Mode4_SingleOn1" 27 "Mode4_SingleOn2" 28 "Mode4_SingleOn3" 29 "Mode4_SingleOn4" 30 "Mode4_SingleOn5" 31 "Mode4_SingleOn6" 32 "Mode4_SingleOn7" 33 "Mode4_SingleOn8" 34 "Mode4_SingleOn9" 35 "Mode4_SingleOn10" 36 "Mode4_SingleOn11" 37 "Mode4_SingleOn12" 38 "Mode4_SingleOff1" 39 "Mode4_SingleOff2" 40 "Mode4_SingleOff3" 41 "Mode4_SingleOff4" 42 "Mode4_SingleOff5" 43 "Mode4_SingleOff6" 44 "Mode4_SingleOff7" 45 "Mode4_SingleOff8" 46 "Mode4_SingleOff9" 47 "Mode4_SingleOff10" 48 "Mode4_SingleOff11" 49 "Mode4_SingleOff12";
VAL_ 809 DwnLoadDynLtgPrmForFrntLeGrp9Mode1 0 "Mode4_Off" 1 "Mode4_On" 2 "Mode4_GradualOn" 3 "Mode4_GradualOff" 4 "Mode4_ForwardWipingOn" 5 "Mode4_BackwardWipingOn" 6 "Mode4_OutwardWipingOn" 7 "Mode4_InwardWipingOn" 8 "Mode4_ForwardWipingOff" 9 "Mode4_BackwardWipingOff" 10 "Mode4_OutwardWipingOff" 11 "Mode4_InwardWipingOff" 12 "Mode4_ForwardScanning" 13 "Mode4_BackwardScanning" 14 "Mode4_BreathOn" 15 "Mode4_BreathOff" 16 "Mode4_1stHalfONand2ndHalfOFF" 17 "Mode4_HalfOFFHalfON" 18 "Mode4_HalfDimmingONHalfOFF" 19 "Mode4_HalfDimmingONHalfON" 20 "Mode4_HalfOFFHalfDimmingON" 21 "Mode4_HalfONHalfDimmingON" 22 "Mode4_HalfDimmingOFFHalfOFF" 23 "Mode4_HalfDimmingOFFHalfON" 24 "Mode4_HalfOFFHalfDimmingOFF" 25 "Mode4_HalfONHalfDimmingOFF" 26 "Mode4_SingleOn1" 27 "Mode4_SingleOn2" 28 "Mode4_SingleOn3" 29 "Mode4_SingleOn4" 30 "Mode4_SingleOn5" 31 "Mode4_SingleOn6" 32 "Mode4_SingleOn7" 33 "Mode4_SingleOn8" 34 "Mode4_SingleOn9" 35 "Mode4_SingleOn10" 36 "Mode4_SingleOn11" 37 "Mode4_SingleOn12" 38 "Mode4_SingleOff1" 39 "Mode4_SingleOff2" 40 "Mode4_SingleOff3" 41 "Mode4_SingleOff4" 42 "Mode4_SingleOff5" 43 "Mode4_SingleOff6" 44 "Mode4_SingleOff7" 45 "Mode4_SingleOff8" 46 "Mode4_SingleOff9" 47 "Mode4_SingleOff10" 48 "Mode4_SingleOff11" 49 "Mode4_SingleOff12";
VAL_ 810 DwnLoadDynLtgPrmForFrntLeGrp10Mode1 0 "Mode4_Off" 1 "Mode4_On" 2 "Mode4_GradualOn" 3 "Mode4_GradualOff" 4 "Mode4_ForwardWipingOn" 5 "Mode4_BackwardWipingOn" 6 "Mode4_OutwardWipingOn" 7 "Mode4_InwardWipingOn" 8 "Mode4_ForwardWipingOff" 9 "Mode4_BackwardWipingOff" 10 "Mode4_OutwardWipingOff" 11 "Mode4_InwardWipingOff" 12 "Mode4_ForwardScanning" 13 "Mode4_BackwardScanning" 14 "Mode4_BreathOn" 15 "Mode4_BreathOff" 16 "Mode4_1stHalfONand2ndHalfOFF" 17 "Mode4_HalfOFFHalfON" 18 "Mode4_HalfDimmingONHalfOFF" 19 "Mode4_HalfDimmingONHalfON" 20 "Mode4_HalfOFFHalfDimmingON" 21 "Mode4_HalfONHalfDimmingON" 22 "Mode4_HalfDimmingOFFHalfOFF" 23 "Mode4_HalfDimmingOFFHalfON" 24 "Mode4_HalfOFFHalfDimmingOFF" 25 "Mode4_HalfONHalfDimmingOFF" 26 "Mode4_SingleOn1" 27 "Mode4_SingleOn2" 28 "Mode4_SingleOn3" 29 "Mode4_SingleOn4" 30 "Mode4_SingleOn5" 31 "Mode4_SingleOn6" 32 "Mode4_SingleOn7" 33 "Mode4_SingleOn8" 34 "Mode4_SingleOn9" 35 "Mode4_SingleOn10" 36 "Mode4_SingleOn11" 37 "Mode4_SingleOn12" 38 "Mode4_SingleOff1" 39 "Mode4_SingleOff2" 40 "Mode4_SingleOff3" 41 "Mode4_SingleOff4" 42 "Mode4_SingleOff5" 43 "Mode4_SingleOff6" 44 "Mode4_SingleOff7" 45 "Mode4_SingleOff8" 46 "Mode4_SingleOff9" 47 "Mode4_SingleOff10" 48 "Mode4_SingleOff11" 49 "Mode4_SingleOff12";
VAL_ 811 DwnLoadDynLtgPrmForFrntLeGrp11Mode1 0 "Mode4_Off" 1 "Mode4_On" 2 "Mode4_GradualOn" 3 "Mode4_GradualOff" 4 "Mode4_ForwardWipingOn" 5 "Mode4_BackwardWipingOn" 6 "Mode4_OutwardWipingOn" 7 "Mode4_InwardWipingOn" 8 "Mode4_ForwardWipingOff" 9 "Mode4_BackwardWipingOff" 10 "Mode4_OutwardWipingOff" 11 "Mode4_InwardWipingOff" 12 "Mode4_ForwardScanning" 13 "Mode4_BackwardScanning" 14 "Mode4_BreathOn" 15 "Mode4_BreathOff" 16 "Mode4_1stHalfONand2ndHalfOFF" 17 "Mode4_HalfOFFHalfON" 18 "Mode4_HalfDimmingONHalfOFF" 19 "Mode4_HalfDimmingONHalfON" 20 "Mode4_HalfOFFHalfDimmingON" 21 "Mode4_HalfONHalfDimmingON" 22 "Mode4_HalfDimmingOFFHalfOFF" 23 "Mode4_HalfDimmingOFFHalfON" 24 "Mode4_HalfOFFHalfDimmingOFF" 25 "Mode4_HalfONHalfDimmingOFF" 26 "Mode4_SingleOn1" 27 "Mode4_SingleOn2" 28 "Mode4_SingleOn3" 29 "Mode4_SingleOn4" 30 "Mode4_SingleOn5" 31 "Mode4_SingleOn6" 32 "Mode4_SingleOn7" 33 "Mode4_SingleOn8" 34 "Mode4_SingleOn9" 35 "Mode4_SingleOn10" 36 "Mode4_SingleOn11" 37 "Mode4_SingleOn12" 38 "Mode4_SingleOff1" 39 "Mode4_SingleOff2" 40 "Mode4_SingleOff3" 41 "Mode4_SingleOff4" 42 "Mode4_SingleOff5" 43 "Mode4_SingleOff6" 44 "Mode4_SingleOff7" 45 "Mode4_SingleOff8" 46 "Mode4_SingleOff9" 47 "Mode4_SingleOff10" 48 "Mode4_SingleOff11" 49 "Mode4_SingleOff12";
VAL_ 812 DwnLoadDynLtgPrmForFrntLeGrp12Mode1 0 "Mode4_Off" 1 "Mode4_On" 2 "Mode4_GradualOn" 3 "Mode4_GradualOff" 4 "Mode4_ForwardWipingOn" 5 "Mode4_BackwardWipingOn" 6 "Mode4_OutwardWipingOn" 7 "Mode4_InwardWipingOn" 8 "Mode4_ForwardWipingOff" 9 "Mode4_BackwardWipingOff" 10 "Mode4_OutwardWipingOff" 11 "Mode4_InwardWipingOff" 12 "Mode4_ForwardScanning" 13 "Mode4_BackwardScanning" 14 "Mode4_BreathOn" 15 "Mode4_BreathOff" 16 "Mode4_1stHalfONand2ndHalfOFF" 17 "Mode4_HalfOFFHalfON" 18 "Mode4_HalfDimmingONHalfOFF" 19 "Mode4_HalfDimmingONHalfON" 20 "Mode4_HalfOFFHalfDimmingON" 21 "Mode4_HalfONHalfDimmingON" 22 "Mode4_HalfDimmingOFFHalfOFF" 23 "Mode4_HalfDimmingOFFHalfON" 24 "Mode4_HalfOFFHalfDimmingOFF" 25 "Mode4_HalfONHalfDimmingOFF" 26 "Mode4_SingleOn1" 27 "Mode4_SingleOn2" 28 "Mode4_SingleOn3" 29 "Mode4_SingleOn4" 30 "Mode4_SingleOn5" 31 "Mode4_SingleOn6" 32 "Mode4_SingleOn7" 33 "Mode4_SingleOn8" 34 "Mode4_SingleOn9" 35 "Mode4_SingleOn10" 36 "Mode4_SingleOn11" 37 "Mode4_SingleOn12" 38 "Mode4_SingleOff1" 39 "Mode4_SingleOff2" 40 "Mode4_SingleOff3" 41 "Mode4_SingleOff4" 42 "Mode4_SingleOff5" 43 "Mode4_SingleOff6" 44 "Mode4_SingleOff7" 45 "Mode4_SingleOff8" 46 "Mode4_SingleOff9" 47 "Mode4_SingleOff10" 48 "Mode4_SingleOff11" 49 "Mode4_SingleOff12";
VAL_ 813 DwnLoadDynLtgPrmForFrntLeGrp13Mode1 0 "Mode4_Off" 1 "Mode4_On" 2 "Mode4_GradualOn" 3 "Mode4_GradualOff" 4 "Mode4_ForwardWipingOn" 5 "Mode4_BackwardWipingOn" 6 "Mode4_OutwardWipingOn" 7 "Mode4_InwardWipingOn" 8 "Mode4_ForwardWipingOff" 9 "Mode4_BackwardWipingOff" 10 "Mode4_OutwardWipingOff" 11 "Mode4_InwardWipingOff" 12 "Mode4_ForwardScanning" 13 "Mode4_BackwardScanning" 14 "Mode4_BreathOn" 15 "Mode4_BreathOff" 16 "Mode4_1stHalfONand2ndHalfOFF" 17 "Mode4_HalfOFFHalfON" 18 "Mode4_HalfDimmingONHalfOFF" 19 "Mode4_HalfDimmingONHalfON" 20 "Mode4_HalfOFFHalfDimmingON" 21 "Mode4_HalfONHalfDimmingON" 22 "Mode4_HalfDimmingOFFHalfOFF" 23 "Mode4_HalfDimmingOFFHalfON" 24 "Mode4_HalfOFFHalfDimmingOFF" 25 "Mode4_HalfONHalfDimmingOFF" 26 "Mode4_SingleOn1" 27 "Mode4_SingleOn2" 28 "Mode4_SingleOn3" 29 "Mode4_SingleOn4" 30 "Mode4_SingleOn5" 31 "Mode4_SingleOn6" 32 "Mode4_SingleOn7" 33 "Mode4_SingleOn8" 34 "Mode4_SingleOn9" 35 "Mode4_SingleOn10" 36 "Mode4_SingleOn11" 37 "Mode4_SingleOn12" 38 "Mode4_SingleOff1" 39 "Mode4_SingleOff2" 40 "Mode4_SingleOff3" 41 "Mode4_SingleOff4" 42 "Mode4_SingleOff5" 43 "Mode4_SingleOff6" 44 "Mode4_SingleOff7" 45 "Mode4_SingleOff8" 46 "Mode4_SingleOff9" 47 "Mode4_SingleOff10" 48 "Mode4_SingleOff11" 49 "Mode4_SingleOff12";
VAL_ 814 DwnLoadDynLtgPrmForFrntLeGrp14Mode1 0 "Mode4_Off" 1 "Mode4_On" 2 "Mode4_GradualOn" 3 "Mode4_GradualOff" 4 "Mode4_ForwardWipingOn" 5 "Mode4_BackwardWipingOn" 6 "Mode4_OutwardWipingOn" 7 "Mode4_InwardWipingOn" 8 "Mode4_ForwardWipingOff" 9 "Mode4_BackwardWipingOff" 10 "Mode4_OutwardWipingOff" 11 "Mode4_InwardWipingOff" 12 "Mode4_ForwardScanning" 13 "Mode4_BackwardScanning" 14 "Mode4_BreathOn" 15 "Mode4_BreathOff" 16 "Mode4_1stHalfONand2ndHalfOFF" 17 "Mode4_HalfOFFHalfON" 18 "Mode4_HalfDimmingONHalfOFF" 19 "Mode4_HalfDimmingONHalfON" 20 "Mode4_HalfOFFHalfDimmingON" 21 "Mode4_HalfONHalfDimmingON" 22 "Mode4_HalfDimmingOFFHalfOFF" 23 "Mode4_HalfDimmingOFFHalfON" 24 "Mode4_HalfOFFHalfDimmingOFF" 25 "Mode4_HalfONHalfDimmingOFF" 26 "Mode4_SingleOn1" 27 "Mode4_SingleOn2" 28 "Mode4_SingleOn3" 29 "Mode4_SingleOn4" 30 "Mode4_SingleOn5" 31 "Mode4_SingleOn6" 32 "Mode4_SingleOn7" 33 "Mode4_SingleOn8" 34 "Mode4_SingleOn9" 35 "Mode4_SingleOn10" 36 "Mode4_SingleOn11" 37 "Mode4_SingleOn12" 38 "Mode4_SingleOff1" 39 "Mode4_SingleOff2" 40 "Mode4_SingleOff3" 41 "Mode4_SingleOff4" 42 "Mode4_SingleOff5" 43 "Mode4_SingleOff6" 44 "Mode4_SingleOff7" 45 "Mode4_SingleOff8" 46 "Mode4_SingleOff9" 47 "Mode4_SingleOff10" 48 "Mode4_SingleOff11" 49 "Mode4_SingleOff12";
VAL_ 815 DwnLoadDynLtgPrmForFrntLeGrp15Mode1 0 "Mode4_Off" 1 "Mode4_On" 2 "Mode4_GradualOn" 3 "Mode4_GradualOff" 4 "Mode4_ForwardWipingOn" 5 "Mode4_BackwardWipingOn" 6 "Mode4_OutwardWipingOn" 7 "Mode4_InwardWipingOn" 8 "Mode4_ForwardWipingOff" 9 "Mode4_BackwardWipingOff" 10 "Mode4_OutwardWipingOff" 11 "Mode4_InwardWipingOff" 12 "Mode4_ForwardScanning" 13 "Mode4_BackwardScanning" 14 "Mode4_BreathOn" 15 "Mode4_BreathOff" 16 "Mode4_1stHalfONand2ndHalfOFF" 17 "Mode4_HalfOFFHalfON" 18 "Mode4_HalfDimmingONHalfOFF" 19 "Mode4_HalfDimmingONHalfON" 20 "Mode4_HalfOFFHalfDimmingON" 21 "Mode4_HalfONHalfDimmingON" 22 "Mode4_HalfDimmingOFFHalfOFF" 23 "Mode4_HalfDimmingOFFHalfON" 24 "Mode4_HalfOFFHalfDimmingOFF" 25 "Mode4_HalfONHalfDimmingOFF" 26 "Mode4_SingleOn1" 27 "Mode4_SingleOn2" 28 "Mode4_SingleOn3" 29 "Mode4_SingleOn4" 30 "Mode4_SingleOn5" 31 "Mode4_SingleOn6" 32 "Mode4_SingleOn7" 33 "Mode4_SingleOn8" 34 "Mode4_SingleOn9" 35 "Mode4_SingleOn10" 36 "Mode4_SingleOn11" 37 "Mode4_SingleOn12" 38 "Mode4_SingleOff1" 39 "Mode4_SingleOff2" 40 "Mode4_SingleOff3" 41 "Mode4_SingleOff4" 42 "Mode4_SingleOff5" 43 "Mode4_SingleOff6" 44 "Mode4_SingleOff7" 45 "Mode4_SingleOff8" 46 "Mode4_SingleOff9" 47 "Mode4_SingleOff10" 48 "Mode4_SingleOff11" 49 "Mode4_SingleOff12";
VAL_ 816 DwnLoadDynLtgPrmForFrntLeGrp16Mode1 0 "Mode4_Off" 1 "Mode4_On" 2 "Mode4_GradualOn" 3 "Mode4_GradualOff" 4 "Mode4_ForwardWipingOn" 5 "Mode4_BackwardWipingOn" 6 "Mode4_OutwardWipingOn" 7 "Mode4_InwardWipingOn" 8 "Mode4_ForwardWipingOff" 9 "Mode4_BackwardWipingOff" 10 "Mode4_OutwardWipingOff" 11 "Mode4_InwardWipingOff" 12 "Mode4_ForwardScanning" 13 "Mode4_BackwardScanning" 14 "Mode4_BreathOn" 15 "Mode4_BreathOff" 16 "Mode4_1stHalfONand2ndHalfOFF" 17 "Mode4_HalfOFFHalfON" 18 "Mode4_HalfDimmingONHalfOFF" 19 "Mode4_HalfDimmingONHalfON" 20 "Mode4_HalfOFFHalfDimmingON" 21 "Mode4_HalfONHalfDimmingON" 22 "Mode4_HalfDimmingOFFHalfOFF" 23 "Mode4_HalfDimmingOFFHalfON" 24 "Mode4_HalfOFFHalfDimmingOFF" 25 "Mode4_HalfONHalfDimmingOFF" 26 "Mode4_SingleOn1" 27 "Mode4_SingleOn2" 28 "Mode4_SingleOn3" 29 "Mode4_SingleOn4" 30 "Mode4_SingleOn5" 31 "Mode4_SingleOn6" 32 "Mode4_SingleOn7" 33 "Mode4_SingleOn8" 34 "Mode4_SingleOn9" 35 "Mode4_SingleOn10" 36 "Mode4_SingleOn11" 37 "Mode4_SingleOn12" 38 "Mode4_SingleOff1" 39 "Mode4_SingleOff2" 40 "Mode4_SingleOff3" 41 "Mode4_SingleOff4" 42 "Mode4_SingleOff5" 43 "Mode4_SingleOff6" 44 "Mode4_SingleOff7" 45 "Mode4_SingleOff8" 46 "Mode4_SingleOff9" 47 "Mode4_SingleOff10" 48 "Mode4_SingleOff11" 49 "Mode4_SingleOff12";
VAL_ 817 DwnLoadDynLtgPrmForFrntLeGrp17Mode1 0 "Mode4_Off" 1 "Mode4_On" 2 "Mode4_GradualOn" 3 "Mode4_GradualOff" 4 "Mode4_ForwardWipingOn" 5 "Mode4_BackwardWipingOn" 6 "Mode4_OutwardWipingOn" 7 "Mode4_InwardWipingOn" 8 "Mode4_ForwardWipingOff" 9 "Mode4_BackwardWipingOff" 10 "Mode4_OutwardWipingOff" 11 "Mode4_InwardWipingOff" 12 "Mode4_ForwardScanning" 13 "Mode4_BackwardScanning" 14 "Mode4_BreathOn" 15 "Mode4_BreathOff" 16 "Mode4_1stHalfONand2ndHalfOFF" 17 "Mode4_HalfOFFHalfON" 18 "Mode4_HalfDimmingONHalfOFF" 19 "Mode4_HalfDimmingONHalfON" 20 "Mode4_HalfOFFHalfDimmingON" 21 "Mode4_HalfONHalfDimmingON" 22 "Mode4_HalfDimmingOFFHalfOFF" 23 "Mode4_HalfDimmingOFFHalfON" 24 "Mode4_HalfOFFHalfDimmingOFF" 25 "Mode4_HalfONHalfDimmingOFF" 26 "Mode4_SingleOn1" 27 "Mode4_SingleOn2" 28 "Mode4_SingleOn3" 29 "Mode4_SingleOn4" 30 "Mode4_SingleOn5" 31 "Mode4_SingleOn6" 32 "Mode4_SingleOn7" 33 "Mode4_SingleOn8" 34 "Mode4_SingleOn9" 35 "Mode4_SingleOn10" 36 "Mode4_SingleOn11" 37 "Mode4_SingleOn12" 38 "Mode4_SingleOff1" 39 "Mode4_SingleOff2" 40 "Mode4_SingleOff3" 41 "Mode4_SingleOff4" 42 "Mode4_SingleOff5" 43 "Mode4_SingleOff6" 44 "Mode4_SingleOff7" 45 "Mode4_SingleOff8" 46 "Mode4_SingleOff9" 47 "Mode4_SingleOff10" 48 "Mode4_SingleOff11" 49 "Mode4_SingleOff12";
VAL_ 818 DwnLoadDynLtgPrmForFrntLeGrp18Mode1 0 "Mode4_Off" 1 "Mode4_On" 2 "Mode4_GradualOn" 3 "Mode4_GradualOff" 4 "Mode4_ForwardWipingOn" 5 "Mode4_BackwardWipingOn" 6 "Mode4_OutwardWipingOn" 7 "Mode4_InwardWipingOn" 8 "Mode4_ForwardWipingOff" 9 "Mode4_BackwardWipingOff" 10 "Mode4_OutwardWipingOff" 11 "Mode4_InwardWipingOff" 12 "Mode4_ForwardScanning" 13 "Mode4_BackwardScanning" 14 "Mode4_BreathOn" 15 "Mode4_BreathOff" 16 "Mode4_1stHalfONand2ndHalfOFF" 17 "Mode4_HalfOFFHalfON" 18 "Mode4_HalfDimmingONHalfOFF" 19 "Mode4_HalfDimmingONHalfON" 20 "Mode4_HalfOFFHalfDimmingON" 21 "Mode4_HalfONHalfDimmingON" 22 "Mode4_HalfDimmingOFFHalfOFF" 23 "Mode4_HalfDimmingOFFHalfON" 24 "Mode4_HalfOFFHalfDimmingOFF" 25 "Mode4_HalfONHalfDimmingOFF" 26 "Mode4_SingleOn1" 27 "Mode4_SingleOn2" 28 "Mode4_SingleOn3" 29 "Mode4_SingleOn4" 30 "Mode4_SingleOn5" 31 "Mode4_SingleOn6" 32 "Mode4_SingleOn7" 33 "Mode4_SingleOn8" 34 "Mode4_SingleOn9" 35 "Mode4_SingleOn10" 36 "Mode4_SingleOn11" 37 "Mode4_SingleOn12" 38 "Mode4_SingleOff1" 39 "Mode4_SingleOff2" 40 "Mode4_SingleOff3" 41 "Mode4_SingleOff4" 42 "Mode4_SingleOff5" 43 "Mode4_SingleOff6" 44 "Mode4_SingleOff7" 45 "Mode4_SingleOff8" 46 "Mode4_SingleOff9" 47 "Mode4_SingleOff10" 48 "Mode4_SingleOff11" 49 "Mode4_SingleOff12";
VAL_ 819 DwnLoadDynLtgPrmForFrntLeGrp19Mode1 0 "Mode4_Off" 1 "Mode4_On" 2 "Mode4_GradualOn" 3 "Mode4_GradualOff" 4 "Mode4_ForwardWipingOn" 5 "Mode4_BackwardWipingOn" 6 "Mode4_OutwardWipingOn" 7 "Mode4_InwardWipingOn" 8 "Mode4_ForwardWipingOff" 9 "Mode4_BackwardWipingOff" 10 "Mode4_OutwardWipingOff" 11 "Mode4_InwardWipingOff" 12 "Mode4_ForwardScanning" 13 "Mode4_BackwardScanning" 14 "Mode4_BreathOn" 15 "Mode4_BreathOff" 16 "Mode4_1stHalfONand2ndHalfOFF" 17 "Mode4_HalfOFFHalfON" 18 "Mode4_HalfDimmingONHalfOFF" 19 "Mode4_HalfDimmingONHalfON" 20 "Mode4_HalfOFFHalfDimmingON" 21 "Mode4_HalfONHalfDimmingON" 22 "Mode4_HalfDimmingOFFHalfOFF" 23 "Mode4_HalfDimmingOFFHalfON" 24 "Mode4_HalfOFFHalfDimmingOFF" 25 "Mode4_HalfONHalfDimmingOFF" 26 "Mode4_SingleOn1" 27 "Mode4_SingleOn2" 28 "Mode4_SingleOn3" 29 "Mode4_SingleOn4" 30 "Mode4_SingleOn5" 31 "Mode4_SingleOn6" 32 "Mode4_SingleOn7" 33 "Mode4_SingleOn8" 34 "Mode4_SingleOn9" 35 "Mode4_SingleOn10" 36 "Mode4_SingleOn11" 37 "Mode4_SingleOn12" 38 "Mode4_SingleOff1" 39 "Mode4_SingleOff2" 40 "Mode4_SingleOff3" 41 "Mode4_SingleOff4" 42 "Mode4_SingleOff5" 43 "Mode4_SingleOff6" 44 "Mode4_SingleOff7" 45 "Mode4_SingleOff8" 46 "Mode4_SingleOff9" 47 "Mode4_SingleOff10" 48 "Mode4_SingleOff11" 49 "Mode4_SingleOff12";
VAL_ 820 DwnLoadDynLtgPrmForFrntLeGrp20Mode1 0 "Mode4_Off" 1 "Mode4_On" 2 "Mode4_GradualOn" 3 "Mode4_GradualOff" 4 "Mode4_ForwardWipingOn" 5 "Mode4_BackwardWipingOn" 6 "Mode4_OutwardWipingOn" 7 "Mode4_InwardWipingOn" 8 "Mode4_ForwardWipingOff" 9 "Mode4_BackwardWipingOff" 10 "Mode4_OutwardWipingOff" 11 "Mode4_InwardWipingOff" 12 "Mode4_ForwardScanning" 13 "Mode4_BackwardScanning" 14 "Mode4_BreathOn" 15 "Mode4_BreathOff" 16 "Mode4_1stHalfONand2ndHalfOFF" 17 "Mode4_HalfOFFHalfON" 18 "Mode4_HalfDimmingONHalfOFF" 19 "Mode4_HalfDimmingONHalfON" 20 "Mode4_HalfOFFHalfDimmingON" 21 "Mode4_HalfONHalfDimmingON" 22 "Mode4_HalfDimmingOFFHalfOFF" 23 "Mode4_HalfDimmingOFFHalfON" 24 "Mode4_HalfOFFHalfDimmingOFF" 25 "Mode4_HalfONHalfDimmingOFF" 26 "Mode4_SingleOn1" 27 "Mode4_SingleOn2" 28 "Mode4_SingleOn3" 29 "Mode4_SingleOn4" 30 "Mode4_SingleOn5" 31 "Mode4_SingleOn6" 32 "Mode4_SingleOn7" 33 "Mode4_SingleOn8" 34 "Mode4_SingleOn9" 35 "Mode4_SingleOn10" 36 "Mode4_SingleOn11" 37 "Mode4_SingleOn12" 38 "Mode4_SingleOff1" 39 "Mode4_SingleOff2" 40 "Mode4_SingleOff3" 41 "Mode4_SingleOff4" 42 "Mode4_SingleOff5" 43 "Mode4_SingleOff6" 44 "Mode4_SingleOff7" 45 "Mode4_SingleOff8" 46 "Mode4_SingleOff9" 47 "Mode4_SingleOff10" 48 "Mode4_SingleOff11" 49 "Mode4_SingleOff12";
VAL_ 821 DwnLoadDynLtgPrmForFrntLeGrp21Mode1 0 "Mode4_Off" 1 "Mode4_On" 2 "Mode4_GradualOn" 3 "Mode4_GradualOff" 4 "Mode4_ForwardWipingOn" 5 "Mode4_BackwardWipingOn" 6 "Mode4_OutwardWipingOn" 7 "Mode4_InwardWipingOn" 8 "Mode4_ForwardWipingOff" 9 "Mode4_BackwardWipingOff" 10 "Mode4_OutwardWipingOff" 11 "Mode4_InwardWipingOff" 12 "Mode4_ForwardScanning" 13 "Mode4_BackwardScanning" 14 "Mode4_BreathOn" 15 "Mode4_BreathOff" 16 "Mode4_1stHalfONand2ndHalfOFF" 17 "Mode4_HalfOFFHalfON" 18 "Mode4_HalfDimmingONHalfOFF" 19 "Mode4_HalfDimmingONHalfON" 20 "Mode4_HalfOFFHalfDimmingON" 21 "Mode4_HalfONHalfDimmingON" 22 "Mode4_HalfDimmingOFFHalfOFF" 23 "Mode4_HalfDimmingOFFHalfON" 24 "Mode4_HalfOFFHalfDimmingOFF" 25 "Mode4_HalfONHalfDimmingOFF" 26 "Mode4_SingleOn1" 27 "Mode4_SingleOn2" 28 "Mode4_SingleOn3" 29 "Mode4_SingleOn4" 30 "Mode4_SingleOn5" 31 "Mode4_SingleOn6" 32 "Mode4_SingleOn7" 33 "Mode4_SingleOn8" 34 "Mode4_SingleOn9" 35 "Mode4_SingleOn10" 36 "Mode4_SingleOn11" 37 "Mode4_SingleOn12" 38 "Mode4_SingleOff1" 39 "Mode4_SingleOff2" 40 "Mode4_SingleOff3" 41 "Mode4_SingleOff4" 42 "Mode4_SingleOff5" 43 "Mode4_SingleOff6" 44 "Mode4_SingleOff7" 45 "Mode4_SingleOff8" 46 "Mode4_SingleOff9" 47 "Mode4_SingleOff10" 48 "Mode4_SingleOff11" 49 "Mode4_SingleOff12";
VAL_ 822 DwnLoadDynLtgPrmForFrntLeGrp22Mode1 0 "Mode4_Off" 1 "Mode4_On" 2 "Mode4_GradualOn" 3 "Mode4_GradualOff" 4 "Mode4_ForwardWipingOn" 5 "Mode4_BackwardWipingOn" 6 "Mode4_OutwardWipingOn" 7 "Mode4_InwardWipingOn" 8 "Mode4_ForwardWipingOff" 9 "Mode4_BackwardWipingOff" 10 "Mode4_OutwardWipingOff" 11 "Mode4_InwardWipingOff" 12 "Mode4_ForwardScanning" 13 "Mode4_BackwardScanning" 14 "Mode4_BreathOn" 15 "Mode4_BreathOff" 16 "Mode4_1stHalfONand2ndHalfOFF" 17 "Mode4_HalfOFFHalfON" 18 "Mode4_HalfDimmingONHalfOFF" 19 "Mode4_HalfDimmingONHalfON" 20 "Mode4_HalfOFFHalfDimmingON" 21 "Mode4_HalfONHalfDimmingON" 22 "Mode4_HalfDimmingOFFHalfOFF" 23 "Mode4_HalfDimmingOFFHalfON" 24 "Mode4_HalfOFFHalfDimmingOFF" 25 "Mode4_HalfONHalfDimmingOFF" 26 "Mode4_SingleOn1" 27 "Mode4_SingleOn2" 28 "Mode4_SingleOn3" 29 "Mode4_SingleOn4" 30 "Mode4_SingleOn5" 31 "Mode4_SingleOn6" 32 "Mode4_SingleOn7" 33 "Mode4_SingleOn8" 34 "Mode4_SingleOn9" 35 "Mode4_SingleOn10" 36 "Mode4_SingleOn11" 37 "Mode4_SingleOn12" 38 "Mode4_SingleOff1" 39 "Mode4_SingleOff2" 40 "Mode4_SingleOff3" 41 "Mode4_SingleOff4" 42 "Mode4_SingleOff5" 43 "Mode4_SingleOff6" 44 "Mode4_SingleOff7" 45 "Mode4_SingleOff8" 46 "Mode4_SingleOff9" 47 "Mode4_SingleOff10" 48 "Mode4_SingleOff11" 49 "Mode4_SingleOff12";
VAL_ 823 DwnLoadDynLtgPrmForFrntLeGrp23Mode1 0 "Mode4_Off" 1 "Mode4_On" 2 "Mode4_GradualOn" 3 "Mode4_GradualOff" 4 "Mode4_ForwardWipingOn" 5 "Mode4_BackwardWipingOn" 6 "Mode4_OutwardWipingOn" 7 "Mode4_InwardWipingOn" 8 "Mode4_ForwardWipingOff" 9 "Mode4_BackwardWipingOff" 10 "Mode4_OutwardWipingOff" 11 "Mode4_InwardWipingOff" 12 "Mode4_ForwardScanning" 13 "Mode4_BackwardScanning" 14 "Mode4_BreathOn" 15 "Mode4_BreathOff" 16 "Mode4_1stHalfONand2ndHalfOFF" 17 "Mode4_HalfOFFHalfON" 18 "Mode4_HalfDimmingONHalfOFF" 19 "Mode4_HalfDimmingONHalfON" 20 "Mode4_HalfOFFHalfDimmingON" 21 "Mode4_HalfONHalfDimmingON" 22 "Mode4_HalfDimmingOFFHalfOFF" 23 "Mode4_HalfDimmingOFFHalfON" 24 "Mode4_HalfOFFHalfDimmingOFF" 25 "Mode4_HalfONHalfDimmingOFF" 26 "Mode4_SingleOn1" 27 "Mode4_SingleOn2" 28 "Mode4_SingleOn3" 29 "Mode4_SingleOn4" 30 "Mode4_SingleOn5" 31 "Mode4_SingleOn6" 32 "Mode4_SingleOn7" 33 "Mode4_SingleOn8" 34 "Mode4_SingleOn9" 35 "Mode4_SingleOn10" 36 "Mode4_SingleOn11" 37 "Mode4_SingleOn12" 38 "Mode4_SingleOff1" 39 "Mode4_SingleOff2" 40 "Mode4_SingleOff3" 41 "Mode4_SingleOff4" 42 "Mode4_SingleOff5" 43 "Mode4_SingleOff6" 44 "Mode4_SingleOff7" 45 "Mode4_SingleOff8" 46 "Mode4_SingleOff9" 47 "Mode4_SingleOff10" 48 "Mode4_SingleOff11" 49 "Mode4_SingleOff12";
VAL_ 824 DwnLoadDynLtgPrmForFrntLeGrp24Mode1 0 "Mode4_Off" 1 "Mode4_On" 2 "Mode4_GradualOn" 3 "Mode4_GradualOff" 4 "Mode4_ForwardWipingOn" 5 "Mode4_BackwardWipingOn" 6 "Mode4_OutwardWipingOn" 7 "Mode4_InwardWipingOn" 8 "Mode4_ForwardWipingOff" 9 "Mode4_BackwardWipingOff" 10 "Mode4_OutwardWipingOff" 11 "Mode4_InwardWipingOff" 12 "Mode4_ForwardScanning" 13 "Mode4_BackwardScanning" 14 "Mode4_BreathOn" 15 "Mode4_BreathOff" 16 "Mode4_1stHalfONand2ndHalfOFF" 17 "Mode4_HalfOFFHalfON" 18 "Mode4_HalfDimmingONHalfOFF" 19 "Mode4_HalfDimmingONHalfON" 20 "Mode4_HalfOFFHalfDimmingON" 21 "Mode4_HalfONHalfDimmingON" 22 "Mode4_HalfDimmingOFFHalfOFF" 23 "Mode4_HalfDimmingOFFHalfON" 24 "Mode4_HalfOFFHalfDimmingOFF" 25 "Mode4_HalfONHalfDimmingOFF" 26 "Mode4_SingleOn1" 27 "Mode4_SingleOn2" 28 "Mode4_SingleOn3" 29 "Mode4_SingleOn4" 30 "Mode4_SingleOn5" 31 "Mode4_SingleOn6" 32 "Mode4_SingleOn7" 33 "Mode4_SingleOn8" 34 "Mode4_SingleOn9" 35 "Mode4_SingleOn10" 36 "Mode4_SingleOn11" 37 "Mode4_SingleOn12" 38 "Mode4_SingleOff1" 39 "Mode4_SingleOff2" 40 "Mode4_SingleOff3" 41 "Mode4_SingleOff4" 42 "Mode4_SingleOff5" 43 "Mode4_SingleOff6" 44 "Mode4_SingleOff7" 45 "Mode4_SingleOff8" 46 "Mode4_SingleOff9" 47 "Mode4_SingleOff10" 48 "Mode4_SingleOff11" 49 "Mode4_SingleOff12";
VAL_ 825 DwnLoadDynLtgPrmForFrntRIGrp1Mode1 0 "Mode4_Off" 1 "Mode4_On" 2 "Mode4_GradualOn" 3 "Mode4_GradualOff" 4 "Mode4_ForwardWipingOn" 5 "Mode4_BackwardWipingOn" 6 "Mode4_OutwardWipingOn" 7 "Mode4_InwardWipingOn" 8 "Mode4_ForwardWipingOff" 9 "Mode4_BackwardWipingOff" 10 "Mode4_OutwardWipingOff" 11 "Mode4_InwardWipingOff" 12 "Mode4_ForwardScanning" 13 "Mode4_BackwardScanning" 14 "Mode4_BreathOn" 15 "Mode4_BreathOff" 16 "Mode4_1stHalfONand2ndHalfOFF" 17 "Mode4_HalfOFFHalfON" 18 "Mode4_HalfDimmingONHalfOFF" 19 "Mode4_HalfDimmingONHalfON" 20 "Mode4_HalfOFFHalfDimmingON" 21 "Mode4_HalfONHalfDimmingON" 22 "Mode4_HalfDimmingOFFHalfOFF" 23 "Mode4_HalfDimmingOFFHalfON" 24 "Mode4_HalfOFFHalfDimmingOFF" 25 "Mode4_HalfONHalfDimmingOFF" 26 "Mode4_SingleOn1" 27 "Mode4_SingleOn2" 28 "Mode4_SingleOn3" 29 "Mode4_SingleOn4" 30 "Mode4_SingleOn5" 31 "Mode4_SingleOn6" 32 "Mode4_SingleOn7" 33 "Mode4_SingleOn8" 34 "Mode4_SingleOn9" 35 "Mode4_SingleOn10" 36 "Mode4_SingleOn11" 37 "Mode4_SingleOn12" 38 "Mode4_SingleOff1" 39 "Mode4_SingleOff2" 40 "Mode4_SingleOff3" 41 "Mode4_SingleOff4" 42 "Mode4_SingleOff5" 43 "Mode4_SingleOff6" 44 "Mode4_SingleOff7" 45 "Mode4_SingleOff8" 46 "Mode4_SingleOff9" 47 "Mode4_SingleOff10" 48 "Mode4_SingleOff11" 49 "Mode4_SingleOff12";
VAL_ 826 DwnLoadDynLtgPrmForFrntRIGrp2Mode1 0 "Mode4_Off" 1 "Mode4_On" 2 "Mode4_GradualOn" 3 "Mode4_GradualOff" 4 "Mode4_ForwardWipingOn" 5 "Mode4_BackwardWipingOn" 6 "Mode4_OutwardWipingOn" 7 "Mode4_InwardWipingOn" 8 "Mode4_ForwardWipingOff" 9 "Mode4_BackwardWipingOff" 10 "Mode4_OutwardWipingOff" 11 "Mode4_InwardWipingOff" 12 "Mode4_ForwardScanning" 13 "Mode4_BackwardScanning" 14 "Mode4_BreathOn" 15 "Mode4_BreathOff" 16 "Mode4_1stHalfONand2ndHalfOFF" 17 "Mode4_HalfOFFHalfON" 18 "Mode4_HalfDimmingONHalfOFF" 19 "Mode4_HalfDimmingONHalfON" 20 "Mode4_HalfOFFHalfDimmingON" 21 "Mode4_HalfONHalfDimmingON" 22 "Mode4_HalfDimmingOFFHalfOFF" 23 "Mode4_HalfDimmingOFFHalfON" 24 "Mode4_HalfOFFHalfDimmingOFF" 25 "Mode4_HalfONHalfDimmingOFF" 26 "Mode4_SingleOn1" 27 "Mode4_SingleOn2" 28 "Mode4_SingleOn3" 29 "Mode4_SingleOn4" 30 "Mode4_SingleOn5" 31 "Mode4_SingleOn6" 32 "Mode4_SingleOn7" 33 "Mode4_SingleOn8" 34 "Mode4_SingleOn9" 35 "Mode4_SingleOn10" 36 "Mode4_SingleOn11" 37 "Mode4_SingleOn12" 38 "Mode4_SingleOff1" 39 "Mode4_SingleOff2" 40 "Mode4_SingleOff3" 41 "Mode4_SingleOff4" 42 "Mode4_SingleOff5" 43 "Mode4_SingleOff6" 44 "Mode4_SingleOff7" 45 "Mode4_SingleOff8" 46 "Mode4_SingleOff9" 47 "Mode4_SingleOff10" 48 "Mode4_SingleOff11" 49 "Mode4_SingleOff12";
VAL_ 827 DwnLoadDynLtgPrmForFrntRIGrp3Mode1 0 "Mode4_Off" 1 "Mode4_On" 2 "Mode4_GradualOn" 3 "Mode4_GradualOff" 4 "Mode4_ForwardWipingOn" 5 "Mode4_BackwardWipingOn" 6 "Mode4_OutwardWipingOn" 7 "Mode4_InwardWipingOn" 8 "Mode4_ForwardWipingOff" 9 "Mode4_BackwardWipingOff" 10 "Mode4_OutwardWipingOff" 11 "Mode4_InwardWipingOff" 12 "Mode4_ForwardScanning" 13 "Mode4_BackwardScanning" 14 "Mode4_BreathOn" 15 "Mode4_BreathOff" 16 "Mode4_1stHalfONand2ndHalfOFF" 17 "Mode4_HalfOFFHalfON" 18 "Mode4_HalfDimmingONHalfOFF" 19 "Mode4_HalfDimmingONHalfON" 20 "Mode4_HalfOFFHalfDimmingON" 21 "Mode4_HalfONHalfDimmingON" 22 "Mode4_HalfDimmingOFFHalfOFF" 23 "Mode4_HalfDimmingOFFHalfON" 24 "Mode4_HalfOFFHalfDimmingOFF" 25 "Mode4_HalfONHalfDimmingOFF" 26 "Mode4_SingleOn1" 27 "Mode4_SingleOn2" 28 "Mode4_SingleOn3" 29 "Mode4_SingleOn4" 30 "Mode4_SingleOn5" 31 "Mode4_SingleOn6" 32 "Mode4_SingleOn7" 33 "Mode4_SingleOn8" 34 "Mode4_SingleOn9" 35 "Mode4_SingleOn10" 36 "Mode4_SingleOn11" 37 "Mode4_SingleOn12" 38 "Mode4_SingleOff1" 39 "Mode4_SingleOff2" 40 "Mode4_SingleOff3" 41 "Mode4_SingleOff4" 42 "Mode4_SingleOff5" 43 "Mode4_SingleOff6" 44 "Mode4_SingleOff7" 45 "Mode4_SingleOff8" 46 "Mode4_SingleOff9" 47 "Mode4_SingleOff10" 48 "Mode4_SingleOff11" 49 "Mode4_SingleOff12";
VAL_ 828 DwnLoadDynLtgPrmForFrntRIGrp4Mode1 0 "Mode4_Off" 1 "Mode4_On" 2 "Mode4_GradualOn" 3 "Mode4_GradualOff" 4 "Mode4_ForwardWipingOn" 5 "Mode4_BackwardWipingOn" 6 "Mode4_OutwardWipingOn" 7 "Mode4_InwardWipingOn" 8 "Mode4_ForwardWipingOff" 9 "Mode4_BackwardWipingOff" 10 "Mode4_OutwardWipingOff" 11 "Mode4_InwardWipingOff" 12 "Mode4_ForwardScanning" 13 "Mode4_BackwardScanning" 14 "Mode4_BreathOn" 15 "Mode4_BreathOff" 16 "Mode4_1stHalfONand2ndHalfOFF" 17 "Mode4_HalfOFFHalfON" 18 "Mode4_HalfDimmingONHalfOFF" 19 "Mode4_HalfDimmingONHalfON" 20 "Mode4_HalfOFFHalfDimmingON" 21 "Mode4_HalfONHalfDimmingON" 22 "Mode4_HalfDimmingOFFHalfOFF" 23 "Mode4_HalfDimmingOFFHalfON" 24 "Mode4_HalfOFFHalfDimmingOFF" 25 "Mode4_HalfONHalfDimmingOFF" 26 "Mode4_SingleOn1" 27 "Mode4_SingleOn2" 28 "Mode4_SingleOn3" 29 "Mode4_SingleOn4" 30 "Mode4_SingleOn5" 31 "Mode4_SingleOn6" 32 "Mode4_SingleOn7" 33 "Mode4_SingleOn8" 34 "Mode4_SingleOn9" 35 "Mode4_SingleOn10" 36 "Mode4_SingleOn11" 37 "Mode4_SingleOn12" 38 "Mode4_SingleOff1" 39 "Mode4_SingleOff2" 40 "Mode4_SingleOff3" 41 "Mode4_SingleOff4" 42 "Mode4_SingleOff5" 43 "Mode4_SingleOff6" 44 "Mode4_SingleOff7" 45 "Mode4_SingleOff8" 46 "Mode4_SingleOff9" 47 "Mode4_SingleOff10" 48 "Mode4_SingleOff11" 49 "Mode4_SingleOff12";
VAL_ 829 DwnLoadDynLtgPrmForFrntRIGrp5Mode1 0 "Mode4_Off" 1 "Mode4_On" 2 "Mode4_GradualOn" 3 "Mode4_GradualOff" 4 "Mode4_ForwardWipingOn" 5 "Mode4_BackwardWipingOn" 6 "Mode4_OutwardWipingOn" 7 "Mode4_InwardWipingOn" 8 "Mode4_ForwardWipingOff" 9 "Mode4_BackwardWipingOff" 10 "Mode4_OutwardWipingOff" 11 "Mode4_InwardWipingOff" 12 "Mode4_ForwardScanning" 13 "Mode4_BackwardScanning" 14 "Mode4_BreathOn" 15 "Mode4_BreathOff" 16 "Mode4_1stHalfONand2ndHalfOFF" 17 "Mode4_HalfOFFHalfON" 18 "Mode4_HalfDimmingONHalfOFF" 19 "Mode4_HalfDimmingONHalfON" 20 "Mode4_HalfOFFHalfDimmingON" 21 "Mode4_HalfONHalfDimmingON" 22 "Mode4_HalfDimmingOFFHalfOFF" 23 "Mode4_HalfDimmingOFFHalfON" 24 "Mode4_HalfOFFHalfDimmingOFF" 25 "Mode4_HalfONHalfDimmingOFF" 26 "Mode4_SingleOn1" 27 "Mode4_SingleOn2" 28 "Mode4_SingleOn3" 29 "Mode4_SingleOn4" 30 "Mode4_SingleOn5" 31 "Mode4_SingleOn6" 32 "Mode4_SingleOn7" 33 "Mode4_SingleOn8" 34 "Mode4_SingleOn9" 35 "Mode4_SingleOn10" 36 "Mode4_SingleOn11" 37 "Mode4_SingleOn12" 38 "Mode4_SingleOff1" 39 "Mode4_SingleOff2" 40 "Mode4_SingleOff3" 41 "Mode4_SingleOff4" 42 "Mode4_SingleOff5" 43 "Mode4_SingleOff6" 44 "Mode4_SingleOff7" 45 "Mode4_SingleOff8" 46 "Mode4_SingleOff9" 47 "Mode4_SingleOff10" 48 "Mode4_SingleOff11" 49 "Mode4_SingleOff12";
VAL_ 830 DwnLoadDynLtgPrmForFrntRIGrp6Mode1 0 "Mode4_Off" 1 "Mode4_On" 2 "Mode4_GradualOn" 3 "Mode4_GradualOff" 4 "Mode4_ForwardWipingOn" 5 "Mode4_BackwardWipingOn" 6 "Mode4_OutwardWipingOn" 7 "Mode4_InwardWipingOn" 8 "Mode4_ForwardWipingOff" 9 "Mode4_BackwardWipingOff" 10 "Mode4_OutwardWipingOff" 11 "Mode4_InwardWipingOff" 12 "Mode4_ForwardScanning" 13 "Mode4_BackwardScanning" 14 "Mode4_BreathOn" 15 "Mode4_BreathOff" 16 "Mode4_1stHalfONand2ndHalfOFF" 17 "Mode4_HalfOFFHalfON" 18 "Mode4_HalfDimmingONHalfOFF" 19 "Mode4_HalfDimmingONHalfON" 20 "Mode4_HalfOFFHalfDimmingON" 21 "Mode4_HalfONHalfDimmingON" 22 "Mode4_HalfDimmingOFFHalfOFF" 23 "Mode4_HalfDimmingOFFHalfON" 24 "Mode4_HalfOFFHalfDimmingOFF" 25 "Mode4_HalfONHalfDimmingOFF" 26 "Mode4_SingleOn1" 27 "Mode4_SingleOn2" 28 "Mode4_SingleOn3" 29 "Mode4_SingleOn4" 30 "Mode4_SingleOn5" 31 "Mode4_SingleOn6" 32 "Mode4_SingleOn7" 33 "Mode4_SingleOn8" 34 "Mode4_SingleOn9" 35 "Mode4_SingleOn10" 36 "Mode4_SingleOn11" 37 "Mode4_SingleOn12" 38 "Mode4_SingleOff1" 39 "Mode4_SingleOff2" 40 "Mode4_SingleOff3" 41 "Mode4_SingleOff4" 42 "Mode4_SingleOff5" 43 "Mode4_SingleOff6" 44 "Mode4_SingleOff7" 45 "Mode4_SingleOff8" 46 "Mode4_SingleOff9" 47 "Mode4_SingleOff10" 48 "Mode4_SingleOff11" 49 "Mode4_SingleOff12";
VAL_ 831 DwnLoadDynLtgPrmForFrntRIGrp7Mode1 0 "Mode4_Off" 1 "Mode4_On" 2 "Mode4_GradualOn" 3 "Mode4_GradualOff" 4 "Mode4_ForwardWipingOn" 5 "Mode4_BackwardWipingOn" 6 "Mode4_OutwardWipingOn" 7 "Mode4_InwardWipingOn" 8 "Mode4_ForwardWipingOff" 9 "Mode4_BackwardWipingOff" 10 "Mode4_OutwardWipingOff" 11 "Mode4_InwardWipingOff" 12 "Mode4_ForwardScanning" 13 "Mode4_BackwardScanning" 14 "Mode4_BreathOn" 15 "Mode4_BreathOff" 16 "Mode4_1stHalfONand2ndHalfOFF" 17 "Mode4_HalfOFFHalfON" 18 "Mode4_HalfDimmingONHalfOFF" 19 "Mode4_HalfDimmingONHalfON" 20 "Mode4_HalfOFFHalfDimmingON" 21 "Mode4_HalfONHalfDimmingON" 22 "Mode4_HalfDimmingOFFHalfOFF" 23 "Mode4_HalfDimmingOFFHalfON" 24 "Mode4_HalfOFFHalfDimmingOFF" 25 "Mode4_HalfONHalfDimmingOFF" 26 "Mode4_SingleOn1" 27 "Mode4_SingleOn2" 28 "Mode4_SingleOn3" 29 "Mode4_SingleOn4" 30 "Mode4_SingleOn5" 31 "Mode4_SingleOn6" 32 "Mode4_SingleOn7" 33 "Mode4_SingleOn8" 34 "Mode4_SingleOn9" 35 "Mode4_SingleOn10" 36 "Mode4_SingleOn11" 37 "Mode4_SingleOn12" 38 "Mode4_SingleOff1" 39 "Mode4_SingleOff2" 40 "Mode4_SingleOff3" 41 "Mode4_SingleOff4" 42 "Mode4_SingleOff5" 43 "Mode4_SingleOff6" 44 "Mode4_SingleOff7" 45 "Mode4_SingleOff8" 46 "Mode4_SingleOff9" 47 "Mode4_SingleOff10" 48 "Mode4_SingleOff11" 49 "Mode4_SingleOff12";
VAL_ 832 DwnLoadDynLtgPrmForFrntRIGrp8Mode1 0 "Mode4_Off" 1 "Mode4_On" 2 "Mode4_GradualOn" 3 "Mode4_GradualOff" 4 "Mode4_ForwardWipingOn" 5 "Mode4_BackwardWipingOn" 6 "Mode4_OutwardWipingOn" 7 "Mode4_InwardWipingOn" 8 "Mode4_ForwardWipingOff" 9 "Mode4_BackwardWipingOff" 10 "Mode4_OutwardWipingOff" 11 "Mode4_InwardWipingOff" 12 "Mode4_ForwardScanning" 13 "Mode4_BackwardScanning" 14 "Mode4_BreathOn" 15 "Mode4_BreathOff" 16 "Mode4_1stHalfONand2ndHalfOFF" 17 "Mode4_HalfOFFHalfON" 18 "Mode4_HalfDimmingONHalfOFF" 19 "Mode4_HalfDimmingONHalfON" 20 "Mode4_HalfOFFHalfDimmingON" 21 "Mode4_HalfONHalfDimmingON" 22 "Mode4_HalfDimmingOFFHalfOFF" 23 "Mode4_HalfDimmingOFFHalfON" 24 "Mode4_HalfOFFHalfDimmingOFF" 25 "Mode4_HalfONHalfDimmingOFF" 26 "Mode4_SingleOn1" 27 "Mode4_SingleOn2" 28 "Mode4_SingleOn3" 29 "Mode4_SingleOn4" 30 "Mode4_SingleOn5" 31 "Mode4_SingleOn6" 32 "Mode4_SingleOn7" 33 "Mode4_SingleOn8" 34 "Mode4_SingleOn9" 35 "Mode4_SingleOn10" 36 "Mode4_SingleOn11" 37 "Mode4_SingleOn12" 38 "Mode4_SingleOff1" 39 "Mode4_SingleOff2" 40 "Mode4_SingleOff3" 41 "Mode4_SingleOff4" 42 "Mode4_SingleOff5" 43 "Mode4_SingleOff6" 44 "Mode4_SingleOff7" 45 "Mode4_SingleOff8" 46 "Mode4_SingleOff9" 47 "Mode4_SingleOff10" 48 "Mode4_SingleOff11" 49 "Mode4_SingleOff12";
VAL_ 833 DwnLoadDynLtgPrmForFrntRIGrp9Mode1 0 "Mode4_Off" 1 "Mode4_On" 2 "Mode4_GradualOn" 3 "Mode4_GradualOff" 4 "Mode4_ForwardWipingOn" 5 "Mode4_BackwardWipingOn" 6 "Mode4_OutwardWipingOn" 7 "Mode4_InwardWipingOn" 8 "Mode4_ForwardWipingOff" 9 "Mode4_BackwardWipingOff" 10 "Mode4_OutwardWipingOff" 11 "Mode4_InwardWipingOff" 12 "Mode4_ForwardScanning" 13 "Mode4_BackwardScanning" 14 "Mode4_BreathOn" 15 "Mode4_BreathOff" 16 "Mode4_1stHalfONand2ndHalfOFF" 17 "Mode4_HalfOFFHalfON" 18 "Mode4_HalfDimmingONHalfOFF" 19 "Mode4_HalfDimmingONHalfON" 20 "Mode4_HalfOFFHalfDimmingON" 21 "Mode4_HalfONHalfDimmingON" 22 "Mode4_HalfDimmingOFFHalfOFF" 23 "Mode4_HalfDimmingOFFHalfON" 24 "Mode4_HalfOFFHalfDimmingOFF" 25 "Mode4_HalfONHalfDimmingOFF" 26 "Mode4_SingleOn1" 27 "Mode4_SingleOn2" 28 "Mode4_SingleOn3" 29 "Mode4_SingleOn4" 30 "Mode4_SingleOn5" 31 "Mode4_SingleOn6" 32 "Mode4_SingleOn7" 33 "Mode4_SingleOn8" 34 "Mode4_SingleOn9" 35 "Mode4_SingleOn10" 36 "Mode4_SingleOn11" 37 "Mode4_SingleOn12" 38 "Mode4_SingleOff1" 39 "Mode4_SingleOff2" 40 "Mode4_SingleOff3" 41 "Mode4_SingleOff4" 42 "Mode4_SingleOff5" 43 "Mode4_SingleOff6" 44 "Mode4_SingleOff7" 45 "Mode4_SingleOff8" 46 "Mode4_SingleOff9" 47 "Mode4_SingleOff10" 48 "Mode4_SingleOff11" 49 "Mode4_SingleOff12";
VAL_ 593 ExtrLiShowStoreStsFrntLe 0 "OnOff1_Off" 1 "OnOff1_On";
VAL_ 593 StsOfLedHiBeamLe 0 "DevSts4_Off" 1 "DevSts4_On" 2 "DevSts4_Err" 3 "DevSts4_Resd";
VAL_ 593 StsOfLedLeLogoLamp 0 "DevSts4_Off" 1 "DevSts4_On" 2 "DevSts4_Err" 3 "DevSts4_Resd";
VAL_ 593 StsOfLedLoBeamLe 0 "DevSts4_Off" 1 "DevSts4_On" 2 "DevSts4_Err" 3 "DevSts4_Resd";
VAL_ 124 DwnLoadStsFbOfHdlampLe 0 "Sts_Resd" 1 "Sts_Err" 2 "Sts_CmplOk" 3 "Sts_InProgs";
VAL_ 124 DwnLoadStsFbOfLogoLampLe 0 "Sts_Resd" 1 "Sts_Err" 2 "Sts_CmplOk" 3 "Sts_InProgs";
VAL_ 124 ExtrLiShowActvnFrntLeFb 0 "Sts_Resd" 1 "Sts_Err" 2 "Sts_CmplOk" 3 "Sts_InProgs";
VAL_ 124 ExtrLiShowActvnLeLogoFb 0 "Sts_Resd" 1 "Sts_Err" 2 "Sts_CmplOk" 3 "Sts_InProgs";
VAL_ 124 HdlampLeInpSts1 0 "Boolean_FALSE" 1 "Boolean_TRUE";
VAL_ 124 HdlampLeInpSts2 0 "Boolean_FALSE" 1 "Boolean_TRUE";
VAL_ 124 StsOfAfsLe 0 "DevSts4_Off" 1 "DevSts4_On" 2 "DevSts4_Err" 3 "DevSts4_Resd";
VAL_ 124 StsOfAhbcLe 0 "DevSts4_Off" 1 "DevSts4_On" 2 "DevSts4_Err" 3 "DevSts4_Resd";
VAL_ 124 StsOfFrntSideMkrLampLe2 0 "DevSts4_Off" 1 "DevSts4_On" 2 "DevSts4_Err" 3 "DevSts4_Resd";
VAL_ 124 StsOfLedCornrgLampLe 0 "DevSts4_Off" 1 "DevSts4_On" 2 "DevSts4_Err" 3 "DevSts4_Resd";
VAL_ 124 StsOfLedDaytiRunngLampLe 0 "DevSts4_Off" 1 "DevSts4_On" 2 "DevSts4_Err" 3 "DevSts4_Resd";
VAL_ 124 StsOfLedFrntFogLampLe 0 "DevSts4_Off" 1 "DevSts4_On" 2 "DevSts4_Err" 3 "DevSts4_Resd";
VAL_ 124 StsOfLedFrntPosnLampLe 0 "DevSts4_Off" 1 "DevSts4_On" 2 "DevSts4_Err" 3 "DevSts4_Resd";
VAL_ 124 StsOfLedFrntTurnIndcrLe 0 "DevSts4_Off" 1 "DevSts4_On" 2 "DevSts4_Err" 3 "DevSts4_Resd";
VAL_ 124 StsOfLvlgLeStsOfLvlgLe 0 "DevSts4_Off" 1 "DevSts4_On" 2 "DevSts4_Err" 3 "DevSts4_Resd";
VAL_ 124 StsOfSwvlgLe 0 "DevSts4_Off" 1 "DevSts4_On" 2 "DevSts4_Err" 3 "DevSts4_Resd";
VAL_ 124 StsOfTouristModLe 0 "DevSts4_Off" 1 "DevSts4_On" 2 "DevSts4_Err" 3 "DevSts4_Resd";
VAL_ 124 StsOfWelGbyFrntLe 0 "OnOff1_Off" 1 "OnOff1_On";
VAL_ 594 ExtrLiShowStoreStsFrntRi 0 "OnOff1_Off" 1 "OnOff1_On";
VAL_ 594 StsOfLedHiBeamRi 0 "DevSts4_Off" 1 "DevSts4_On" 2 "DevSts4_Err" 3 "DevSts4_Resd";
VAL_ 594 StsOfLedLoBeamRi 0 "DevSts4_Off" 1 "DevSts4_On" 2 "DevSts4_Err" 3 "DevSts4_Resd";
VAL_ 594 StsOfLedRiLogoLamp 0 "DevSts4_Off" 1 "DevSts4_On" 2 "DevSts4_Err" 3 "DevSts4_Resd";
VAL_ 127 DwnLoadStsFbOfHdlampRi 0 "Sts_Resd" 1 "Sts_Err" 2 "Sts_CmplOk" 3 "Sts_InProgs";
VAL_ 127 DwnLoadStsFbOfLogoLampRi 0 "Sts_Resd" 1 "Sts_Err" 2 "Sts_CmplOk" 3 "Sts_InProgs";
VAL_ 127 ExtrLiShowActvnFrntRiFb 0 "Sts_Resd" 1 "Sts_Err" 2 "Sts_CmplOk" 3 "Sts_InProgs";
VAL_ 127 ExtrLiShowActvnRiLogoFb 0 "Sts_Resd" 1 "Sts_Err" 2 "Sts_CmplOk" 3 "Sts_InProgs";
VAL_ 127 HdlampRiInpSts1 0 "Boolean_FALSE" 1 "Boolean_TRUE";
VAL_ 127 HdlampRiInpSts2 0 "Boolean_FALSE" 1 "Boolean_TRUE";
VAL_ 127 StsOfAfsRi 0 "DevSts4_Off" 1 "DevSts4_On" 2 "DevSts4_Err" 3 "DevSts4_Resd";
VAL_ 127 StsOfAhbcRi 0 "DevSts4_Off" 1 "DevSts4_On" 2 "DevSts4_Err" 3 "DevSts4_Resd";
VAL_ 127 StsOfFrntSideMkrLampRi2 0 "DevSts4_Off" 1 "DevSts4_On" 2 "DevSts4_Err" 3 "DevSts4_Resd";
VAL_ 127 StsOfLedCornrgLampRi 0 "DevSts4_Off" 1 "DevSts4_On" 2 "DevSts4_Err" 3 "DevSts4_Resd";
VAL_ 127 StsOfLedDaytiRunngLampRi 0 "DevSts4_Off" 1 "DevSts4_On" 2 "DevSts4_Err" 3 "DevSts4_Resd";
VAL_ 127 StsOfLedFrntFogLampRi 0 "DevSts4_Off" 1 "DevSts4_On" 2 "DevSts4_Err" 3 "DevSts4_Resd";
VAL_ 127 StsOfLedFrntPosnLampRi 0 "DevSts4_Off" 1 "DevSts4_On" 2 "DevSts4_Err" 3 "DevSts4_Resd";
VAL_ 127 StsOfLedFrntTurnIndcrRi 0 "DevSts4_Off" 1 "DevSts4_On" 2 "DevSts4_Err" 3 "DevSts4_Resd";
VAL_ 127 StsOfLvlgRiStsOfLvlgRi 0 "DevSts4_Off" 1 "DevSts4_On" 2 "DevSts4_Err" 3 "DevSts4_Resd";
VAL_ 127 StsOfSwvlgRi 0 "DevSts4_Off" 1 "DevSts4_On" 2 "DevSts4_Err" 3 "DevSts4_Resd";
VAL_ 127 StsOfTouristModRi 0 "DevSts4_Off" 1 "DevSts4_On" 2 "DevSts4_Err" 3 "DevSts4_Resd";
VAL_ 127 StsOfWelGbyFrntRi 0 "OnOff1_Off" 1 "OnOff1_On";
VAL_ 592 DwnLoadStsFbOfReLampCtrlLe1 0 "Sts_Resd" 1 "Sts_Err" 2 "Sts_CmplOk" 3 "Sts_InProgs";
VAL_ 592 ExtrLiShowActvnReLeFb 0 "Sts_Resd" 1 "Sts_Err" 2 "Sts_CmplOk" 3 "Sts_InProgs";
VAL_ 592 ExtrLiShowStoreStsReLe1 0 "OnOff1_Off" 1 "OnOff1_On";
VAL_ 592 StsOfLedPosnLampLe1 0 "DevSts4_Off" 1 "DevSts4_On" 2 "DevSts4_Err" 3 "DevSts4_Resd";
VAL_ 592 StsOfLedReFogLampLe1 0 "DevSts4_Off" 1 "DevSts4_On" 2 "DevSts4_Err" 3 "DevSts4_Resd";
VAL_ 592 StsOfLedReLampLe1 0 "DevSts4_Off" 1 "DevSts4_On" 2 "DevSts4_Err" 3 "DevSts4_Resd";
VAL_ 592 StsOfLedRvsgLampLe1 0 "DevSts4_Off" 1 "DevSts4_On" 2 "DevSts4_Err" 3 "DevSts4_Resd";
VAL_ 592 StsOfLedStopLampLe1 0 "DevSts4_Off" 1 "DevSts4_On" 2 "DevSts4_Err" 3 "DevSts4_Resd";
VAL_ 592 StsOfLedTurnIndcrLe1 0 "DevSts4_Off" 1 "DevSts4_On" 2 "DevSts4_Err" 3 "DevSts4_Resd";
VAL_ 592 StsOfWelGbyReLe1 0 "OnOff1_Off" 1 "OnOff1_On";
VAL_ 596 DwnLoadStsFbOfReLampCtrlLe2 0 "Sts_Resd" 1 "Sts_Err" 2 "Sts_CmplOk" 3 "Sts_InProgs";
VAL_ 596 DwnLoadStsFbOfReLampCtrlRi2 0 "Sts_Resd" 1 "Sts_Err" 2 "Sts_CmplOk" 3 "Sts_InProgs";
VAL_ 596 ExtrLiShowActvnReLe2Fb 0 "Sts_Resd" 1 "Sts_Err" 2 "Sts_CmplOk" 3 "Sts_InProgs";
VAL_ 596 ExtrLiShowActvnReRi2Fb 0 "Sts_Resd" 1 "Sts_Err" 2 "Sts_CmplOk" 3 "Sts_InProgs";
VAL_ 596 ExtrLiShowStoreStsReLe2 0 "OnOff1_Off" 1 "OnOff1_On";
VAL_ 596 ExtrLiShowStoreStsReRi2 0 "OnOff1_Off" 1 "OnOff1_On";
VAL_ 596 StsOfLedPosnLampLe2 0 "DevSts4_Off" 1 "DevSts4_On" 2 "DevSts4_Err" 3 "DevSts4_Resd";
VAL_ 596 StsOfLedPosnLampRi2 0 "DevSts4_Off" 1 "DevSts4_On" 2 "DevSts4_Err" 3 "DevSts4_Resd";
VAL_ 596 StsOfLedReFogLampLe2 0 "DevSts4_Off" 1 "DevSts4_On" 2 "DevSts4_Err" 3 "DevSts4_Resd";
VAL_ 596 StsOfLedReFogLampRi2 0 "DevSts4_Off" 1 "DevSts4_On" 2 "DevSts4_Err" 3 "DevSts4_Resd";
VAL_ 596 StsOfLedReLampLe2 0 "DevSts4_Off" 1 "DevSts4_On" 2 "DevSts4_Err" 3 "DevSts4_Resd";
VAL_ 596 StsOfLedReLampRi2 0 "DevSts4_Off" 1 "DevSts4_On" 2 "DevSts4_Err" 3 "DevSts4_Resd";
VAL_ 596 StsOfLedRvsgLampLe2 0 "DevSts4_Off" 1 "DevSts4_On" 2 "DevSts4_Err" 3 "DevSts4_Resd";
VAL_ 596 StsOfLedRvsgLampRi2 0 "DevSts4_Off" 1 "DevSts4_On" 2 "DevSts4_Err" 3 "DevSts4_Resd";
VAL_ 596 StsOfLedStopLampLe2 0 "DevSts4_Off" 1 "DevSts4_On" 2 "DevSts4_Err" 3 "DevSts4_Resd";
VAL_ 596 StsOfLedStopLampRi2 0 "DevSts4_Off" 1 "DevSts4_On" 2 "DevSts4_Err" 3 "DevSts4_Resd";
VAL_ 596 StsOfLedTurnIndcrLe2 0 "DevSts4_Off" 1 "DevSts4_On" 2 "DevSts4_Err" 3 "DevSts4_Resd";
VAL_ 596 StsOfLedTurnIndcrRi2 0 "DevSts4_Off" 1 "DevSts4_On" 2 "DevSts4_Err" 3 "DevSts4_Resd";
VAL_ 596 StsOfWelGbyReLe2 0 "OnOff1_Off" 1 "OnOff1_On";
VAL_ 596 StsOfWelGbyReRi2 0 "OnOff1_Off" 1 "OnOff1_On";
VAL_ 608 DwnLoadStsFbOfReLampCtrlRi1 0 "Sts_Resd" 1 "Sts_Err" 2 "Sts_CmplOk" 3 "Sts_InProgs";
VAL_ 608 ExtrLiShowActvnReRiFb 0 "Sts_Resd" 1 "Sts_Err" 2 "Sts_CmplOk" 3 "Sts_InProgs";
VAL_ 608 ExtrLiShowStoreStsReRi1 0 "OnOff1_Off" 1 "OnOff1_On";
VAL_ 608 StsOfLedPosnLampRi1 0 "DevSts4_Off" 1 "DevSts4_On" 2 "DevSts4_Err" 3 "DevSts4_Resd";
VAL_ 608 StsOfLedReFogLampRi1 0 "DevSts4_Off" 1 "DevSts4_On" 2 "DevSts4_Err" 3 "DevSts4_Resd";
VAL_ 608 StsOfLedReLampRi1 0 "DevSts4_Off" 1 "DevSts4_On" 2 "DevSts4_Err" 3 "DevSts4_Resd";
VAL_ 608 StsOfLedRvsgLampRi1 0 "DevSts4_Off" 1 "DevSts4_On" 2 "DevSts4_Err" 3 "DevSts4_Resd";
VAL_ 608 StsOfLedStopLampRi1 0 "DevSts4_Off" 1 "DevSts4_On" 2 "DevSts4_Err" 3 "DevSts4_Resd";
VAL_ 608 StsOfLedTurnIndcrRi1 0 "DevSts4_Off" 1 "DevSts4_On" 2 "DevSts4_Err" 3 "DevSts4_Resd";
VAL_ 608 StsOfWelGbyReRi1 0 "OnOff1_Off" 1 "OnOff1_On";
SIG_GROUP_ 1425 CEMdevelpsignalgroupreq 1 : CEMdevelpsignalgroupreqFunctiondevpsignalgroup1 CEMdevelpsignalgroupreqFunctiondevpsignalgroup2 CEMdevelpsignalgroupreqFunctiondevpsignalgroup3 CEMdevelpsignalgroupreqFunctiondevpsignalgroup4 CEMdevelpsignalgroupreqFunctiondevpsignalgroup5 CEMdevelpsignalgroupreqFunctiondevpsignalgroup6 CEMdevelpsignalgroupreqFunctiondevpsignalgroup7 CEMdevelpsignalgroupreqFunctiondevpsignalgroup8;
SIG_GROUP_ 335 DwnLoadDynLitPrmLedFrntMidPosnLi 1 : DwnLoadDynLitPrmLedFrntMidPosnLiContTiPrm DwnLoadDynLitPrmLedFrntMidPosnLiLowBriPrm DwnLoadDynLitPrmLedFrntMidPosnLiModePrm DwnLoadDynLitPrmLedFrntMidPosnLiOffsTiPrm DwnLoadDynLitPrmLedFrntMidPosnLiTistamp DwnLoadDynLitPrmLedFrntMidPosnLiUpprBriPrm;
SIG_GROUP_ 336 DwnLoadDynLitPrmLedLeSideLogoLi 1 : DwnLoadDynLitPrmLedLeSideLogoLiContTiPrm DwnLoadDynLitPrmLedLeSideLogoLiLowBriPrm DwnLoadDynLitPrmLedLeSideLogoLiModePrm DwnLoadDynLitPrmLedLeSideLogoLiOffsTiPrm DwnLoadDynLitPrmLedLeSideLogoLiTistamp DwnLoadDynLitPrmLedLeSideLogoLiUpprBriPrm;
SIG_GROUP_ 337 DwnLoadDynLitPrmLedRiSideLogoLi 1 : DwnLoadDynLitPrmLedRiSideLogoLiContTiPrm DwnLoadDynLitPrmLedRiSideLogoLiLowBriPrm DwnLoadDynLitPrmLedRiSideLogoLiModePrm DwnLoadDynLitPrmLedRiSideLogoLiOffsTiPrm DwnLoadDynLitPrmLedRiSideLogoLiTistamp DwnLoadDynLitPrmLedRiSideLogoLiUpprBriPrm;
SIG_GROUP_ 801 DwnLoadDynLtgPrmForFrntLeGrp1 1 : DwnLoadDynLtgPrmForFrntLeGrp1ContinueTime DwnLoadDynLtgPrmForFrntLeGrp1HighBrightness DwnLoadDynLtgPrmForFrntLeGrp1LowBrightness DwnLoadDynLtgPrmForFrntLeGrp1Mode1 DwnLoadDynLtgPrmForFrntLeGrp1OffsetTime DwnLoadDynLtgPrmForFrntLeGrp1Timestamp;
SIG_GROUP_ 810 DwnLoadDynLtgPrmForFrntLeGrp10 1 : DwnLoadDynLtgPrmForFrntLeGrp10ContinueTime DwnLoadDynLtgPrmForFrntLeGrp10HighBrightness DwnLoadDynLtgPrmForFrntLeGrp10LowBrightness DwnLoadDynLtgPrmForFrntLeGrp10Mode1 DwnLoadDynLtgPrmForFrntLeGrp10OffsetTime DwnLoadDynLtgPrmForFrntLeGrp10Timestamp;
SIG_GROUP_ 811 DwnLoadDynLtgPrmForFrntLeGrp11 1 : DwnLoadDynLtgPrmForFrntLeGrp11ContinueTime DwnLoadDynLtgPrmForFrntLeGrp11HighBrightness DwnLoadDynLtgPrmForFrntLeGrp11LowBrightness DwnLoadDynLtgPrmForFrntLeGrp11Mode1 DwnLoadDynLtgPrmForFrntLeGrp11OffsetTime DwnLoadDynLtgPrmForFrntLeGrp11Timestamp;
SIG_GROUP_ 812 DwnLoadDynLtgPrmForFrntLeGrp12 1 : DwnLoadDynLtgPrmForFrntLeGrp12ContinueTime DwnLoadDynLtgPrmForFrntLeGrp12HighBrightness DwnLoadDynLtgPrmForFrntLeGrp12LowBrightness DwnLoadDynLtgPrmForFrntLeGrp12Mode1 DwnLoadDynLtgPrmForFrntLeGrp12OffsetTime DwnLoadDynLtgPrmForFrntLeGrp12Timestamp;
SIG_GROUP_ 813 DwnLoadDynLtgPrmForFrntLeGrp13 1 : DwnLoadDynLtgPrmForFrntLeGrp13ContinueTime DwnLoadDynLtgPrmForFrntLeGrp13HighBrightness DwnLoadDynLtgPrmForFrntLeGrp13LowBrightness DwnLoadDynLtgPrmForFrntLeGrp13Mode1 DwnLoadDynLtgPrmForFrntLeGrp13OffsetTime DwnLoadDynLtgPrmForFrntLeGrp13Timestamp;
SIG_GROUP_ 814 DwnLoadDynLtgPrmForFrntLeGrp14 1 : DwnLoadDynLtgPrmForFrntLeGrp14ContinueTime DwnLoadDynLtgPrmForFrntLeGrp14HighBrightness DwnLoadDynLtgPrmForFrntLeGrp14LowBrightness DwnLoadDynLtgPrmForFrntLeGrp14Mode1 DwnLoadDynLtgPrmForFrntLeGrp14OffsetTime DwnLoadDynLtgPrmForFrntLeGrp14Timestamp;
SIG_GROUP_ 815 DwnLoadDynLtgPrmForFrntLeGrp15 1 : DwnLoadDynLtgPrmForFrntLeGrp15ContinueTime DwnLoadDynLtgPrmForFrntLeGrp15HighBrightness DwnLoadDynLtgPrmForFrntLeGrp15LowBrightness DwnLoadDynLtgPrmForFrntLeGrp15Mode1 DwnLoadDynLtgPrmForFrntLeGrp15OffsetTime DwnLoadDynLtgPrmForFrntLeGrp15Timestamp;
SIG_GROUP_ 816 DwnLoadDynLtgPrmForFrntLeGrp16 1 : DwnLoadDynLtgPrmForFrntLeGrp16ContinueTime DwnLoadDynLtgPrmForFrntLeGrp16HighBrightness DwnLoadDynLtgPrmForFrntLeGrp16LowBrightness DwnLoadDynLtgPrmForFrntLeGrp16Mode1 DwnLoadDynLtgPrmForFrntLeGrp16OffsetTime DwnLoadDynLtgPrmForFrntLeGrp16Timestamp;
SIG_GROUP_ 817 DwnLoadDynLtgPrmForFrntLeGrp17 1 : DwnLoadDynLtgPrmForFrntLeGrp17ContinueTime DwnLoadDynLtgPrmForFrntLeGrp17HighBrightness DwnLoadDynLtgPrmForFrntLeGrp17LowBrightness DwnLoadDynLtgPrmForFrntLeGrp17Mode1 DwnLoadDynLtgPrmForFrntLeGrp17OffsetTime DwnLoadDynLtgPrmForFrntLeGrp17Timestamp;
SIG_GROUP_ 818 DwnLoadDynLtgPrmForFrntLeGrp18 1 : DwnLoadDynLtgPrmForFrntLeGrp18ContinueTime DwnLoadDynLtgPrmForFrntLeGrp18HighBrightness DwnLoadDynLtgPrmForFrntLeGrp18LowBrightness DwnLoadDynLtgPrmForFrntLeGrp18Mode1 DwnLoadDynLtgPrmForFrntLeGrp18OffsetTime DwnLoadDynLtgPrmForFrntLeGrp18Timestamp;
SIG_GROUP_ 819 DwnLoadDynLtgPrmForFrntLeGrp19 1 : DwnLoadDynLtgPrmForFrntLeGrp19ContinueTime DwnLoadDynLtgPrmForFrntLeGrp19HighBrightness DwnLoadDynLtgPrmForFrntLeGrp19LowBrightness DwnLoadDynLtgPrmForFrntLeGrp19Mode1 DwnLoadDynLtgPrmForFrntLeGrp19OffsetTime DwnLoadDynLtgPrmForFrntLeGrp19Timestamp;
SIG_GROUP_ 802 DwnLoadDynLtgPrmForFrntLeGrp2 1 : DwnLoadDynLtgPrmForFrntLeGrp2ContinueTime DwnLoadDynLtgPrmForFrntLeGrp2HighBrightness DwnLoadDynLtgPrmForFrntLeGrp2LowBrightness DwnLoadDynLtgPrmForFrntLeGrp2Mode1 DwnLoadDynLtgPrmForFrntLeGrp2OffsetTime DwnLoadDynLtgPrmForFrntLeGrp2Timestamp;
SIG_GROUP_ 820 DwnLoadDynLtgPrmForFrntLeGrp20 1 : DwnLoadDynLtgPrmForFrntLeGrp20ContinueTime DwnLoadDynLtgPrmForFrntLeGrp20HighBrightness DwnLoadDynLtgPrmForFrntLeGrp20LowBrightness DwnLoadDynLtgPrmForFrntLeGrp20Mode1 DwnLoadDynLtgPrmForFrntLeGrp20OffsetTime DwnLoadDynLtgPrmForFrntLeGrp20Timestamp;
SIG_GROUP_ 821 DwnLoadDynLtgPrmForFrntLeGrp21 1 : DwnLoadDynLtgPrmForFrntLeGrp21ContinueTime DwnLoadDynLtgPrmForFrntLeGrp21HighBrightness DwnLoadDynLtgPrmForFrntLeGrp21LowBrightness DwnLoadDynLtgPrmForFrntLeGrp21Mode1 DwnLoadDynLtgPrmForFrntLeGrp21OffsetTime DwnLoadDynLtgPrmForFrntLeGrp21Timestamp;
SIG_GROUP_ 822 DwnLoadDynLtgPrmForFrntLeGrp22 1 : DwnLoadDynLtgPrmForFrntLeGrp22ContinueTime DwnLoadDynLtgPrmForFrntLeGrp22HighBrightness DwnLoadDynLtgPrmForFrntLeGrp22LowBrightness DwnLoadDynLtgPrmForFrntLeGrp22Mode1 DwnLoadDynLtgPrmForFrntLeGrp22OffsetTime DwnLoadDynLtgPrmForFrntLeGrp22Timestamp;
SIG_GROUP_ 823 DwnLoadDynLtgPrmForFrntLeGrp23 1 : DwnLoadDynLtgPrmForFrntLeGrp23ContinueTime DwnLoadDynLtgPrmForFrntLeGrp23HighBrightness DwnLoadDynLtgPrmForFrntLeGrp23LowBrightness DwnLoadDynLtgPrmForFrntLeGrp23Mode1 DwnLoadDynLtgPrmForFrntLeGrp23OffsetTime DwnLoadDynLtgPrmForFrntLeGrp23Timestamp;
SIG_GROUP_ 824 DwnLoadDynLtgPrmForFrntLeGrp24 1 : DwnLoadDynLtgPrmForFrntLeGrp24ContinueTime DwnLoadDynLtgPrmForFrntLeGrp24HighBrightness DwnLoadDynLtgPrmForFrntLeGrp24LowBrightness DwnLoadDynLtgPrmForFrntLeGrp24Mode1 DwnLoadDynLtgPrmForFrntLeGrp24OffsetTime DwnLoadDynLtgPrmForFrntLeGrp24Timestamp;
SIG_GROUP_ 803 DwnLoadDynLtgPrmForFrntLeGrp3 1 : DwnLoadDynLtgPrmForFrntLeGrp3ContinueTime DwnLoadDynLtgPrmForFrntLeGrp3HighBrightness DwnLoadDynLtgPrmForFrntLeGrp3LowBrightness DwnLoadDynLtgPrmForFrntLeGrp3Mode1 DwnLoadDynLtgPrmForFrntLeGrp3OffsetTime DwnLoadDynLtgPrmForFrntLeGrp3Timestamp;
SIG_GROUP_ 804 DwnLoadDynLtgPrmForFrntLeGrp4 1 : DwnLoadDynLtgPrmForFrntLeGrp4ContinueTime DwnLoadDynLtgPrmForFrntLeGrp4HighBrightness DwnLoadDynLtgPrmForFrntLeGrp4LowBrightness DwnLoadDynLtgPrmForFrntLeGrp4Mode1 DwnLoadDynLtgPrmForFrntLeGrp4OffsetTime DwnLoadDynLtgPrmForFrntLeGrp4Timestamp;
SIG_GROUP_ 805 DwnLoadDynLtgPrmForFrntLeGrp5 1 : DwnLoadDynLtgPrmForFrntLeGrp5ContinueTime DwnLoadDynLtgPrmForFrntLeGrp5HighBrightness DwnLoadDynLtgPrmForFrntLeGrp5LowBrightness DwnLoadDynLtgPrmForFrntLeGrp5Mode1 DwnLoadDynLtgPrmForFrntLeGrp5OffsetTime DwnLoadDynLtgPrmForFrntLeGrp5Timestamp;
SIG_GROUP_ 806 DwnLoadDynLtgPrmForFrntLeGrp6 1 : DwnLoadDynLtgPrmForFrntLeGrp6ContinueTime DwnLoadDynLtgPrmForFrntLeGrp6HighBrightness DwnLoadDynLtgPrmForFrntLeGrp6LowBrightness DwnLoadDynLtgPrmForFrntLeGrp6Mode1 DwnLoadDynLtgPrmForFrntLeGrp6OffsetTime DwnLoadDynLtgPrmForFrntLeGrp6Timestamp;
SIG_GROUP_ 807 DwnLoadDynLtgPrmForFrntLeGrp7 1 : DwnLoadDynLtgPrmForFrntLeGrp7ContinueTime DwnLoadDynLtgPrmForFrntLeGrp7HighBrightness DwnLoadDynLtgPrmForFrntLeGrp7LowBrightness DwnLoadDynLtgPrmForFrntLeGrp7Mode1 DwnLoadDynLtgPrmForFrntLeGrp7OffsetTime DwnLoadDynLtgPrmForFrntLeGrp7Timestamp;
SIG_GROUP_ 808 DwnLoadDynLtgPrmForFrntLeGrp8 1 : DwnLoadDynLtgPrmForFrntLeGrp8ContinueTime DwnLoadDynLtgPrmForFrntLeGrp8HighBrightness DwnLoadDynLtgPrmForFrntLeGrp8LowBrightness DwnLoadDynLtgPrmForFrntLeGrp8Mode1 DwnLoadDynLtgPrmForFrntLeGrp8OffsetTime DwnLoadDynLtgPrmForFrntLeGrp8Timestamp;
SIG_GROUP_ 809 DwnLoadDynLtgPrmForFrntLeGrp9 1 : DwnLoadDynLtgPrmForFrntLeGrp9ContinueTime DwnLoadDynLtgPrmForFrntLeGrp9HighBrightness DwnLoadDynLtgPrmForFrntLeGrp9LowBrightness DwnLoadDynLtgPrmForFrntLeGrp9Mode1 DwnLoadDynLtgPrmForFrntLeGrp9OffsetTime DwnLoadDynLtgPrmForFrntLeGrp9Timestamp;
SIG_GROUP_ 825 DwnLoadDynLtgPrmForFrntRIGrp1 1 : DwnLoadDynLtgPrmForFrntRIGrp1ContinueTime DwnLoadDynLtgPrmForFrntRIGrp1HighBrightness DwnLoadDynLtgPrmForFrntRIGrp1LowBrightness DwnLoadDynLtgPrmForFrntRIGrp1Mode1 DwnLoadDynLtgPrmForFrntRIGrp1OffsetTime DwnLoadDynLtgPrmForFrntRIGrp1Timestamp;
SIG_GROUP_ 826 DwnLoadDynLtgPrmForFrntRIGrp2 1 : DwnLoadDynLtgPrmForFrntRIGrp2ContinueTime DwnLoadDynLtgPrmForFrntRIGrp2HighBrightness DwnLoadDynLtgPrmForFrntRIGrp2LowBrightness DwnLoadDynLtgPrmForFrntRIGrp2Mode1 DwnLoadDynLtgPrmForFrntRIGrp2OffsetTime DwnLoadDynLtgPrmForFrntRIGrp2Timestamp;
SIG_GROUP_ 827 DwnLoadDynLtgPrmForFrntRIGrp3 1 : DwnLoadDynLtgPrmForFrntRIGrp3ContinueTime DwnLoadDynLtgPrmForFrntRIGrp3HighBrightness DwnLoadDynLtgPrmForFrntRIGrp3LowBrightness DwnLoadDynLtgPrmForFrntRIGrp3Mode1 DwnLoadDynLtgPrmForFrntRIGrp3OffsetTime DwnLoadDynLtgPrmForFrntRIGrp3Timestamp;
SIG_GROUP_ 828 DwnLoadDynLtgPrmForFrntRIGrp4 1 : DwnLoadDynLtgPrmForFrntRIGrp4ContinueTime DwnLoadDynLtgPrmForFrntRIGrp4HighBrightness DwnLoadDynLtgPrmForFrntRIGrp4LowBrightness DwnLoadDynLtgPrmForFrntRIGrp4Mode1 DwnLoadDynLtgPrmForFrntRIGrp4OffsetTime DwnLoadDynLtgPrmForFrntRIGrp4Timestamp;
SIG_GROUP_ 829 DwnLoadDynLtgPrmForFrntRIGrp5 1 : DwnLoadDynLtgPrmForFrntRIGrp5ContinueTime DwnLoadDynLtgPrmForFrntRIGrp5HighBrightness DwnLoadDynLtgPrmForFrntRIGrp5LowBrightness DwnLoadDynLtgPrmForFrntRIGrp5Mode1 DwnLoadDynLtgPrmForFrntRIGrp5OffsetTime DwnLoadDynLtgPrmForFrntRIGrp5Timestamp;
SIG_GROUP_ 830 DwnLoadDynLtgPrmForFrntRIGrp6 1 : DwnLoadDynLtgPrmForFrntRIGrp6ContinueTime DwnLoadDynLtgPrmForFrntRIGrp6HighBrightness DwnLoadDynLtgPrmForFrntRIGrp6LowBrightness DwnLoadDynLtgPrmForFrntRIGrp6Mode1 DwnLoadDynLtgPrmForFrntRIGrp6OffsetTime DwnLoadDynLtgPrmForFrntRIGrp6Timestamp;
SIG_GROUP_ 831 DwnLoadDynLtgPrmForFrntRIGrp7 1 : DwnLoadDynLtgPrmForFrntRIGrp7ContinueTime DwnLoadDynLtgPrmForFrntRIGrp7HighBrightness DwnLoadDynLtgPrmForFrntRIGrp7LowBrightness DwnLoadDynLtgPrmForFrntRIGrp7Mode1 DwnLoadDynLtgPrmForFrntRIGrp7OffsetTime DwnLoadDynLtgPrmForFrntRIGrp7Timestamp;
SIG_GROUP_ 832 DwnLoadDynLtgPrmForFrntRIGrp8 1 : DwnLoadDynLtgPrmForFrntRIGrp8ContinueTime DwnLoadDynLtgPrmForFrntRIGrp8HighBrightness DwnLoadDynLtgPrmForFrntRIGrp8LowBrightness DwnLoadDynLtgPrmForFrntRIGrp8Mode1 DwnLoadDynLtgPrmForFrntRIGrp8OffsetTime DwnLoadDynLtgPrmForFrntRIGrp8Timestamp;
SIG_GROUP_ 833 DwnLoadDynLtgPrmForFrntRIGrp9 1 : DwnLoadDynLtgPrmForFrntRIGrp9ContinueTime DwnLoadDynLtgPrmForFrntRIGrp9HighBrightness DwnLoadDynLtgPrmForFrntRIGrp9LowBrightness DwnLoadDynLtgPrmForFrntRIGrp9Mode1 DwnLoadDynLtgPrmForFrntRIGrp9OffsetTime DwnLoadDynLtgPrmForFrntRIGrp9Timestamp;
SIG_GROUP_ 124 StsOfLvlgLe 1 : StsOfLvlgLeChks StsOfLvlgLeCntr StsOfLvlgLeStsOfLvlgLe;
SIG_GROUP_ 127 StsOfLvlgRi 1 : StsOfLvlgRiChks StsOfLvlgRiCntr StsOfLvlgRiStsOfLvlgRi;
